VERSION ""

NS_ :

BS_:

BU_: AVM_SD CGW IVI eHBox

BO_ 1543 BCM_A106: 8 CGW
  SG_ SilentModeActivationState : 4|1@0+ (1,0) [0|0] "" IVI
  SG_ MirrorDownDisplayRequest : 8|1@0+ (1,0) [0|0] "" IVI
  SG_ MirrorUpDisplayRequest : 9|1@0+ (1,0) [0|0] "" IVI
  SG_ MirrorRightDisplayRequest : 10|1@0+ (1,0) [0|0] "" IVI
  SG_ MirrorLeftDisplayRequest : 11|1@0+ (1,0) [0|0] "" IVI
  SG_ MirrorSideSelectDisplayRequest : 13|2@0+ (1,0) [0|0] "" IVI
  SG_ AmbiLightColorStatus_v2 : 23|7@0+ (1,0) [0|0] "" IVI
  SG_ VR_AuthCondition_RL : 24|1@0+ (1,0) [0|0] "" IVI
  SG_ VR_AuthCondition_FR : 25|1@0+ (1,0) [0|0] "" IVI
  SG_ VR_AuthCondition_FL : 26|1@0+ (1,0) [0|0] "" IVI
  SG_ EmblemLightIntensityStatus : 36|5@0+ (5,0) [0|100] "%" IVI
  SG_ VR_AuthCondition_SSU : 37|1@0+ (1,0) [0|0] "" IVI
  SG_ VR_AuthCondition_SRU : 38|1@0+ (1,0) [0|0] "" IVI
  SG_ VR_AuthCondition_RR : 39|1@0+ (1,0) [0|0] "" IVI
  SG_ RearLeftWheelPressure_V2_twin : 47|8@0+ (30,0) [0|7620] "mbar" IVI
  SG_ RearRightWheelPressure_V2_twin : 55|8@0+ (30,0) [0|7620] "mbar" IVI
  SG_ EcoAdviceTirePressureRR_twin : 59|1@0+ (1,0) [0|0] "" IVI
  SG_ EcoAdviceTirePressureRL_twin : 60|1@0+ (1,0) [0|0] "" IVI

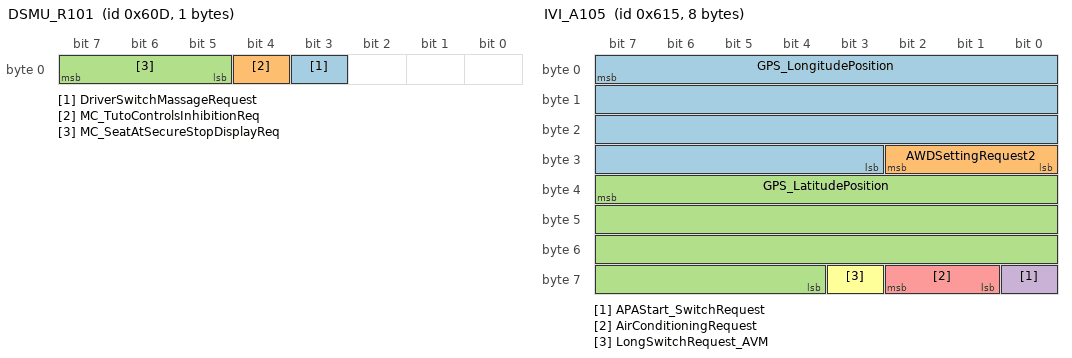
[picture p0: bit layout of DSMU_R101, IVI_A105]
BO_ 1549 DSMU_R101: 1 CGW
  SG_ DriverSwitchMassageRequest : 3|1@0+ (1,0) [0|0] "" IVI
  SG_ MC_TutoControlsInhibitionReq : 4|1@0+ (1,0) [0|0] "" IVI
  SG_ MC_SeatAtSecureStopDisplayReq : 7|3@0+ (1,0) [0|0] "" IVI

BO_ 1553 HVAC_A106: 8 CGW
  SG_ SecondRowCentralSeatStatus : 2|3@0+ (1,0) [0|0] "" IVI
  SG_ ClimForcedFreshDisplayStatus : 6|1@0+ (1,0) [0|0] "" IVI
  SG_ ClimForcedRecyDisplayStatus : 7|1@0+ (1,0) [0|0] "" IVI
  SG_ ClimForcedFreshDisplay : 9|2@0+ (1,0) [0|0] "" IVI
  SG_ ClimAQSSensitivityDisplay : 12|3@0+ (1,0) [0|0] "" IVI
  SG_ ClimExternalAirPollutionDisplay : 15|3@0+ (1,0) [0|0] "" IVI
  SG_ ClimRearDefrostDisplayStatus : 16|1@0+ (1,0) [0|0] "" IVI
  SG_ ClimExternAirPollutioDispStatus : 17|1@0+ (1,0) [0|0] "" IVI
  SG_ ClimLinkPriorityFLSeatAutoDisp : 20|3@0+ (1,0) [0|0] "" IVI
  SG_ ClimLinkPriorityFRSeatAutoDisp : 23|3@0+ (1,0) [0|0] "" IVI
  SG_ FrontRightSeatDisplayStatus : 24|1@0+ (1,0) [0|0] "" IVI
  SG_ FrontRightSeatStatus : 27|3@0+ (1,0) [0|0] "" IVI
  SG_ FrontLeftSeatStatus : 30|3@0+ (1,0) [0|0] "" IVI
  SG_ FrontLeftSeatDisplayStatus : 31|1@0+ (1,0) [0|0] "" IVI
  SG_ SecondRowLeftSeatAutoDisplay : 33|2@0+ (1,0) [0|0] "" IVI
  SG_ SecondRowRightSeatAutoDisplay : 35|2@0+ (1,0) [0|0] "" IVI
  SG_ FrontLeftSeatAutoDisplay : 37|2@0+ (1,0) [0|0] "" IVI
  SG_ FrontRightSeatAutoDisplay : 39|2@0+ (1,0) [0|0] "" IVI
  SG_ ThirdRowLeftSeatAutoDisplay : 41|2@0+ (1,0) [0|0] "" IVI
  SG_ ThirdRowRightSeatDisplayStatus : 42|1@0+ (1,0) [0|0] "" IVI
  SG_ ThirdRowLeftSeatDisplayStatus : 43|1@0+ (1,0) [0|0] "" IVI
  SG_ ThirdRowRightSeatAutoDisplay : 45|2@0+ (1,0) [0|0] "" IVI
  SG_ SecondRowRightSeatDisplayStatus : 46|1@0+ (1,0) [0|0] "" IVI
  SG_ SecondRowLeftSeatDisplayStatus : 47|1@0+ (1,0) [0|0] "" IVI
  SG_ ClimCabinTempDisplayUnit : 48|1@0+ (1,0) [0|0] "" IVI
  SG_ ClimLastFuncModifiedByCustomer_v2 : 55|4@0+ (1,0) [0|0] "" IVI
  SG_ ClimLinkPrioRearSeatsAutoDisp : 58|3@0+ (1,0) [0|0] "" IVI
  SG_ ClimACmaxDisplay : 63|2@0+ (1,0) [0|0] "" IVI

BO_ 1557 IVI_A105: 8 IVI
  SG_ GPS_LongitudePosition : 7|29@0+ (0.00010,-18000) [-18000|17959.999] "min" CGW
  SG_ AWDSettingRequest2 : 26|3@0+ (1,0) [0|0] "" CGW
  SG_ GPS_LatitudePosition : 39|28@0+ (0.00010,-9000) [-9000|8959.999] "min" CGW
  SG_ APAStart_SwitchRequest : 56|1@0+ (1,0) [0|0] "" CGW
  SG_ AirConditioningRequest : 58|2@0+ (1,0) [0|0] "" CGW
  SG_ LongSwitchRequest_AVM : 59|1@0+ (1,0) [0|0] "" CGW

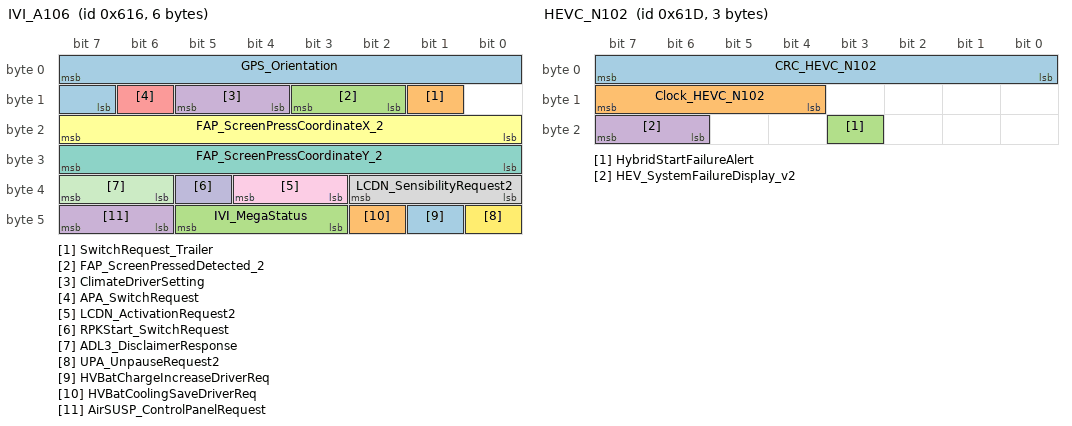
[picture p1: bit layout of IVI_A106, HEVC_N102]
BO_ 1558 IVI_A106: 6 IVI
  SG_ GPS_Orientation : 7|9@0+ (1,-180) [-180|179] "deg" CGW
  SG_ SwitchRequest_Trailer : 9|1@0+ (1,0) [0|0] "" CGW
  SG_ FAP_ScreenPressedDetected_2 : 11|2@0+ (1,0) [0|0] "" CGW
  SG_ ClimateDriverSetting : 13|2@0+ (1,0) [0|0] "" CGW
  SG_ APA_SwitchRequest : 14|1@0+ (1,0) [0|0] "" CGW
  SG_ FAP_ScreenPressCoordinateX_2 : 23|8@0+ (1,0) [0|255] "" CGW
  SG_ FAP_ScreenPressCoordinateY_2 : 31|8@0+ (1,0) [0|255] "" CGW
  SG_ LCDN_SensibilityRequest2 : 34|3@0+ (1,0) [0|0] "" CGW
  SG_ LCDN_ActivationRequest2 : 36|2@0+ (1,0) [0|0] "" CGW
  SG_ RPKStart_SwitchRequest : 37|1@0+ (1,0) [0|0] "" CGW
  SG_ ADL3_DisclaimerResponse : 39|2@0+ (1,0) [0|0] "" CGW
  SG_ UPA_UnpauseRequest2 : 40|1@0+ (1,0) [0|0] "" CGW
  SG_ HVBatChargeIncreaseDriverReq : 41|1@0+ (1,0) [0|0] "" CGW
  SG_ HVBatCoolingSaveDriverReq : 42|1@0+ (1,0) [0|0] "" CGW
  SG_ IVI_MegaStatus : 45|3@0+ (1,0) [0|0] "" CGW
  SG_ AirSUSP_ControlPanelRequest : 47|2@0+ (1,0) [0|0] "" CGW

BO_ 1561 HEVC_A131: 8 CGW
  SG_ HVB_MaxCapacity_HEVC_v2 : 9|16@0+ (0.1,0) [0|6553.5] "kWh" IVI

BO_ 1564 HEVC_A135: 8 CGW
  SG_ ReacheableUSOCatDepartureTime : 7|7@0+ (1,0) [0|100] "%" IVI
  SG_ ReacheableUSOCatDepartureTimeAl : 51|1@0+ (1,0) [0|0] "" IVI

BO_ 1565 HEVC_N102: 3 CGW
  SG_ CRC_HEVC_N102 : 7|8@0+ (1,0) [0|255] "" IVI
  SG_ Clock_HEVC_N102 : 15|4@0+ (1,0) [0|15] "" IVI
  SG_ HybridStartFailureAlert : 19|1@0+ (1,0) [0|0] "" IVI
  SG_ HEV_SystemFailureDisplay_v2 : 23|2@0+ (1,0) [0|0] "" IVI

BO_ 1567 AUDIOamp_A1: 2 CGW
  SG_ AudioAvailability_Amp : 10|1@0+ (1,0) [0|0] "" IVI

BO_ 1568 HEVC_A35: 5 CGW
  SG_ EcoNavDistanceSaving : 7|17@0+ (0.1,0) [0|10000] "wu" IVI

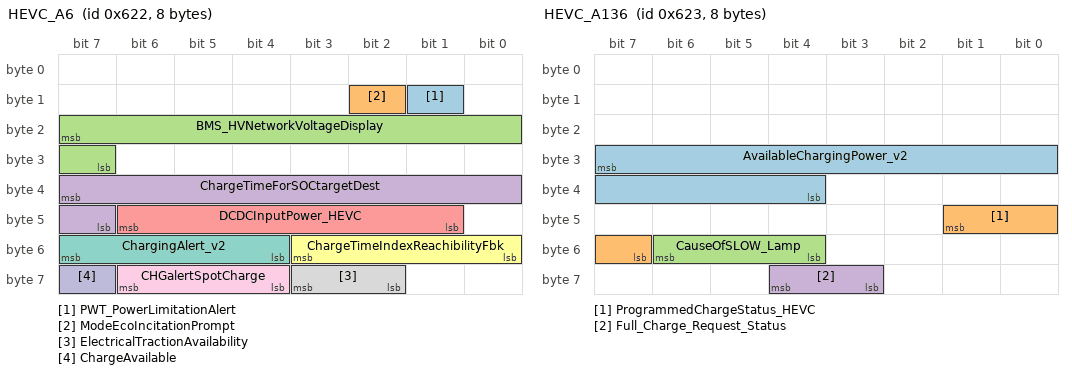
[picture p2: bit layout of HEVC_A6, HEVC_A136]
BO_ 1570 HEVC_A6: 8 CGW
  SG_ PWT_PowerLimitationAlert : 9|1@0+ (1,0) [0|0] "" IVI
  SG_ ModeEcoIncitationPrompt : 10|1@0+ (1,0) [0|0] "" IVI
  SG_ BMS_HVNetworkVoltageDisplay : 23|9@0+ (1,0) [0|500] "V" IVI
  SG_ ChargeTimeForSOCtargetDest : 39|9@0+ (5,0) [0|2555] "min" IVI
  SG_ DCDCInputPower_HEVC : 46|6@0+ (0.1,0) [0|6] "kW" IVI
  SG_ ChargeTimeIndexReachibilityFbk : 51|4@0+ (1,0) [0|0] "" IVI
  SG_ ChargingAlert_v2 : 55|4@0+ (1,0) [0|0] "" IVI
  SG_ ElectricalTractionAvailability : 59|2@0+ (1,0) [0|0] "" IVI
  SG_ CHGalertSpotCharge : 62|3@0+ (1,0) [0|0] "" IVI
  SG_ ChargeAvailable : 63|1@0+ (1,0) [0|0] "" IVI

BO_ 1571 HEVC_A136: 8 CGW
  SG_ AvailableChargingPower_v2 : 31|12@0+ (0.05,0) [0|200] "kW" IVI
  SG_ ProgrammedChargeStatus_HEVC : 41|3@0+ (1,0) [0|0] "" IVI
  SG_ CauseOfSLOW_Lamp : 54|3@0+ (1,0) [0|0] "" IVI
  SG_ Full_Charge_Request_Status : 60|2@0+ (1,0) [0|0] "" IVI

BO_ 1572 HEVC_R105: 7 CGW
  SG_ TotalConsumption_LastTrip : 7|12@0+ (0.1,0) [0|409.4] "kWh" IVI
  SG_ TotalRecovery_LastTrip : 11|12@0+ (0.1,0) [0|409.4] "kWh" IVI

BO_ 1573 HEVC_A23: 6 CGW
  SG_ CHGTemp_BLMS : 23|7@0+ (1,0) [0|100] "%" IVI
  SG_ OperatingTypeStatus_BLMS : 39|4@0+ (1,0) [0|0] "" IVI

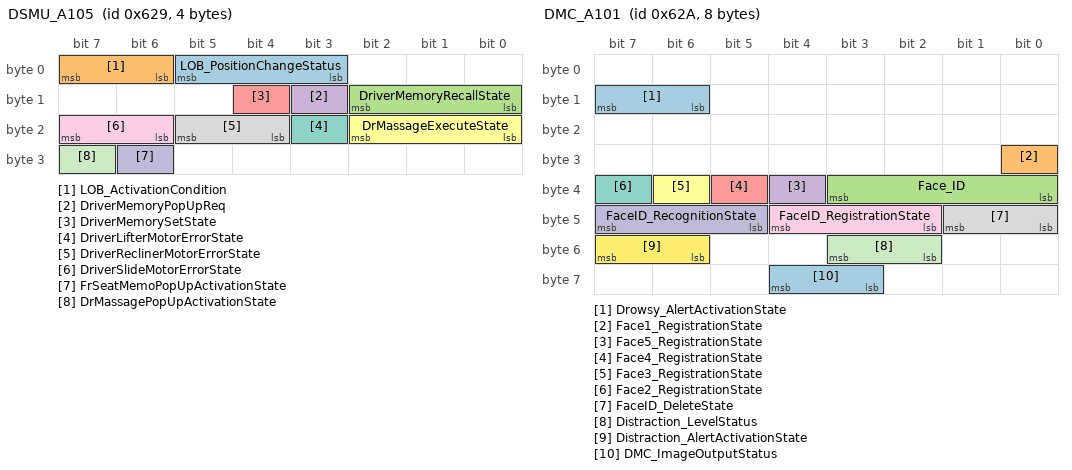
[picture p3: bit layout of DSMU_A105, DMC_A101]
BO_ 1577 DSMU_A105: 4 CGW
  SG_ LOB_PositionChangeStatus : 5|3@0+ (1,0) [0|0] "" IVI
  SG_ LOB_ActivationCondition : 7|2@0+ (1,0) [0|0] "" IVI
  SG_ DriverMemoryRecallState : 10|3@0+ (1,0) [0|0] "" IVI
  SG_ DriverMemoryPopUpReq : 11|1@0+ (1,0) [0|0] "" IVI
  SG_ DriverMemorySetState : 12|1@0+ (1,0) [0|0] "" IVI
  SG_ DrMassageExecuteState : 18|3@0+ (1,0) [0|0] "" IVI
  SG_ DriverLifterMotorErrorState : 19|1@0+ (1,0) [0|0] "" IVI
  SG_ DriverReclinerMotorErrorState : 21|2@0+ (1,0) [0|0] "" IVI
  SG_ DriverSlideMotorErrorState : 23|2@0+ (1,0) [0|0] "" IVI
  SG_ FrSeatMemoPopUpActivationState : 30|1@0+ (1,0) [0|0] "" IVI
  SG_ DrMassagePopUpActivationState : 31|1@0+ (1,0) [0|0] "" IVI

BO_ 1578 DMC_A101: 8 CGW
  SG_ Drowsy_AlertActivationState : 15|2@0+ (1,0) [0|0] "" IVI
  SG_ Face1_RegistrationState : 24|1@0+ (1,0) [0|0] "" IVI
  SG_ Face_ID : 35|4@0+ (1,0) [0|0] "" IVI
  SG_ Face5_RegistrationState : 36|1@0+ (1,0) [0|0] "" IVI
  SG_ Face4_RegistrationState : 37|1@0+ (1,0) [0|0] "" IVI
  SG_ Face3_RegistrationState : 38|1@0+ (1,0) [0|0] "" IVI
  SG_ Face2_RegistrationState : 39|1@0+ (1,0) [0|0] "" IVI
  SG_ FaceID_DeleteState : 41|2@0+ (1,0) [0|0] "" IVI
  SG_ FaceID_RegistrationState : 44|3@0+ (1,0) [0|0] "" IVI
  SG_ FaceID_RecognitionState : 47|3@0+ (1,0) [0|0] "" IVI
  SG_ Distraction_LevelStatus : 51|2@0+ (1,0) [0|0] "" IVI
  SG_ Distraction_AlertActivationState : 55|2@0+ (1,0) [0|0] "" IVI
  SG_ DMC_ImageOutputStatus : 60|2@0+ (1,0) [0|0] "" IVI

BO_ 1579 FRCAMERA_A115: 2 CGW
  SG_ OverspeedAlertActivationStatus : 7|2@0+ (1,0) [0|0] "" IVI

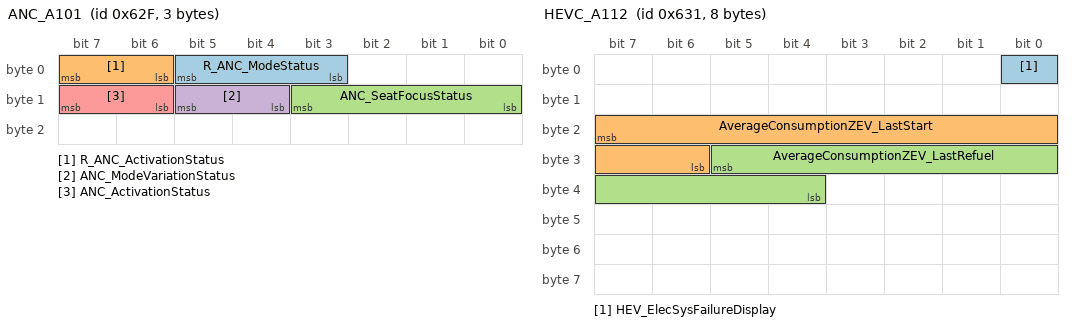
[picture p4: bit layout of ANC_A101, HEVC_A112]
BO_ 1583 ANC_A101: 3 CGW
  SG_ R_ANC_ModeStatus : 5|3@0+ (1,0) [0|0] "" IVI
  SG_ R_ANC_ActivationStatus : 7|2@0+ (1,0) [0|0] "" IVI
  SG_ ANC_SeatFocusStatus : 11|4@0+ (1,0) [0|0] "" IVI
  SG_ ANC_ModeVariationStatus : 13|2@0+ (1,0) [0|0] "" IVI
  SG_ ANC_ActivationStatus : 15|2@0+ (1,0) [0|0] "" IVI

BO_ 1585 HEVC_A112: 8 CGW
  SG_ HEV_ElecSysFailureDisplay : 0|1@0+ (1,0) [0|0] "" IVI
  SG_ AverageConsumptionZEV_LastStart : 23|10@0+ (0.1,0) [0|102.2] "-" IVI
  SG_ AverageConsumptionZEV_LastRefuel : 29|10@0+ (0.1,0) [0|102.2] "" IVI

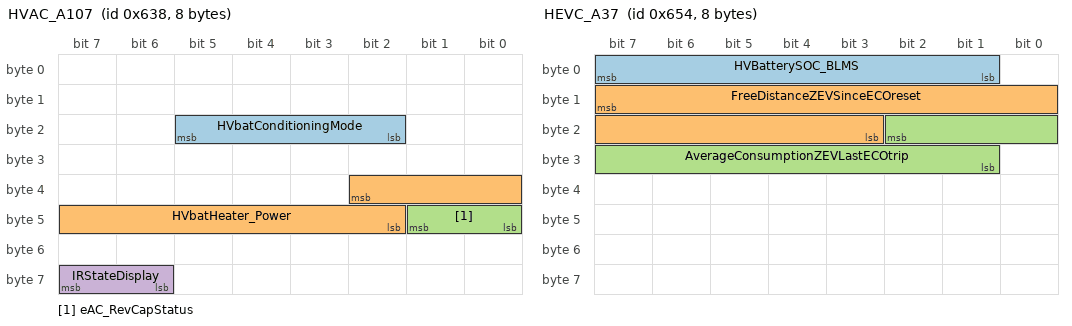
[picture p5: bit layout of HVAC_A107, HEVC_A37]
BO_ 1592 HVAC_A107: 8 CGW
  SG_ HVbatConditioningMode : 21|4@0+ (1,0) [0|0] "" IVI
  SG_ HVbatHeater_Power : 34|9@0+ (10,0) [0|5000] "W" IVI
  SG_ eAC_RevCapStatus : 41|2@0+ (1,0) [0|0] "" IVI
  SG_ IRStateDisplay : 63|2@0+ (1,0) [0|0] "" IVI

BO_ 1595 IVI_A114: 8 IVI
  SG_ FOTA_ProgValueRequest : 5|11@0+ (1,0) [0|1440] "min" CGW
  SG_ TrailerGuidelineActivationRequest : 7|2@0+ (1,0) [0|0] "" CGW
  SG_ HUD_RotationPositionRequest2 : 19|5@0+ (1,0) [0|0] "" CGW
  SG_ AVM_GuidelinesActivationRequest2 : 25|3@0+ (1,0) [0|0] "" CGW
  SG_ OffsetValue_Request2 : 30|5@0+ (1,0) [0|0] "" CGW
  SG_ AmbientLightingAreaADReq : 32|2@0+ (1,0) [0|0] "" CGW
  SG_ VolumAlarmActivationRequest2 : 35|3@0+ (1,0) [0|0] "" CGW
  SG_ ContextSpeed_ActivationRequest2 : 38|3@0+ (1,0) [0|0] "" CGW
  SG_ OffsetActivation_Request2 : 42|2@0+ (1,0) [0|0] "" CGW
  SG_ FOTA_ProgRequest : 44|2@0+ (1,0) [0|0] "" CGW
  SG_ ContextRoad_ActivationRequest2 : 46|2@0+ (1,0) [0|0] "" CGW
  SG_ Drowsy_AlertActivationRequest2 : 49|2@0+ (1,0) [0|0] "" CGW
  SG_ RearViewRVC_CancelReason_RER : 50|1@0+ (1,0) [0|0] "" CGW
  SG_ ZoomAutoActivationRequest2 : 52|2@0+ (1,0) [0|0] "" CGW
  SG_ RearViewRVC_CancelReason : 54|2@0+ (1,0) [0|0] "" CGW
  SG_ HVbatteryWarmingRequest : 57|2@0+ (1,0) [0|0] "" CGW
  SG_ OSE_ActivationRequest2 : 59|2@0+ (1,0) [0|0] "" CGW

BO_ 1596 IVI_R103: 8 IVI
  SG_ NextTurnProximityDetected : 0|1@0+ (1,0) [0|0] "" CGW
  SG_ CurrentAudioState : 2|2@0+ (1,0) [0|0] "" CGW
  SG_ CompassPosition : 7|5@0+ (1,0) [0|31] "wu" CGW
  SG_ CurrentRadioFavorite : 8|1@0+ (1,0) [0|0] "" CGW
  SG_ CurrentPhoneStatus : 11|3@0+ (1,0) [0|0] "" CGW
  SG_ CurrentAudioSource_v2 : 15|4@0+ (1,0) [0|0] "" CGW
  SG_ CurrentRadioBand_v2 : 23|3@0+ (1,0) [0|0] "" CGW
  SG_ AutoDimmingRequest : 25|2@0+ (1,0) [0|0] "" CGW
  SG_ CurrentRadioMode : 27|2@0+ (1,0) [0|0] "" CGW
  SG_ IconNumberForNavigationDisplay : 39|8@0+ (1,0) [0|255] "wu" CGW
  SG_ SC_DepartureTimeMinute : 41|6@0+ (1,0) [0|59] "min" CGW
  SG_ PnCactivationRequest_IVI : 43|2@0+ (1,0) [0|0] "" CGW
  SG_ TCS_DeactivationRequest2 : 45|2@0+ (1,0) [0|0] "" CGW
  SG_ HDC_ActivationRequest2 : 47|2@0+ (1,0) [0|0] "" CGW
  SG_ SC_DepartureTimeHour : 51|5@0+ (1,0) [0|23] "h" CGW
  SG_ ClusterSkinRequest_v2 : 59|4@0+ (1,0) [0|0] "" CGW
  SG_ SC_DepartureTimeWeekDay : 62|3@0+ (1,0) [0|0] "" CGW

BO_ 1599 SRRR_A107: 1 CGW
  SG_ CTA_ActivationState : 7|1@0+ (1,0) [0|0] "" IVI

BO_ 1614 IVI_A129: 8 IVI
  SG_ HUD_TelSMSactivationRequest2 : 1|2@0+ (1,0) [0|0] "" CGW
  SG_ HUD_ITactivationRequest2 : 3|2@0+ (1,0) [0|0] "" CGW
  SG_ FunctionalLightingActivReq : 5|2@0+ (1,0) [0|0] "" CGW
  SG_ CASP_ActivationRequest2 : 7|2@0+ (1,0) [0|0] "" CGW
  SG_ RearLeftLumbarMovingReq_X_Axis : 8|2@0+ (1,0) [0|0] "" CGW
  SG_ RearLeftFrontHeightMovingReq : 10|2@0+ (1,0) [0|0] "" CGW
  SG_ R_ANC_ModeSwitchRequest : 13|3@0+ (1,0) [0|0] "" CGW
  SG_ R_ANC_ActivationRequest : 15|2@0+ (1,0) [0|0] "" CGW
  SG_ RearLeftMassageProgramReq : 17|4@0+ (1,0) [0|0] "" CGW
  SG_ RearLeftMassageIntensityReq : 20|3@0+ (1,0) [0|0] "" CGW
  SG_ RearLeftLumbarMovingReq_Z_Axis : 22|2@0+ (1,0) [0|0] "" CGW
  SG_ RearLeftReclinerMovingReq : 24|2@0+ (1,0) [0|0] "" CGW
  SG_ RearLeftOttomanMovingReq : 26|2@0+ (1,0) [0|0] "" CGW
  SG_ RearLeftMassageVelocityReq : 29|3@0+ (1,0) [0|0] "" CGW
  SG_ RearRightLumbarMovingReq_X_Axis : 32|2@0+ (1,0) [0|0] "" CGW
  SG_ RearRightFrontHeightMovingReq : 34|2@0+ (1,0) [0|0] "" CGW
  SG_ RearLeftUpperbackrestMovingReq : 36|2@0+ (1,0) [0|0] "" CGW
  SG_ RearLeftSlideMovingReq : 38|2@0+ (1,0) [0|0] "" CGW
  SG_ RearRightMassageProgramReq : 41|4@0+ (1,0) [0|0] "" CGW
  SG_ RearRightMassageIntensityReq : 44|3@0+ (1,0) [0|0] "" CGW
  SG_ RearRightLumbarMovingReq_Z_Axis : 46|2@0+ (1,0) [0|0] "" CGW
  SG_ RearRightReclinerMovingReq : 48|2@0+ (1,0) [0|0] "" CGW
  SG_ RearRightOttomanMovingReq : 50|2@0+ (1,0) [0|0] "" CGW
  SG_ RearRightMassageVelocityReq : 53|3@0+ (1,0) [0|0] "" CGW
  SG_ PairingMode : 56|1@0+ (1,0) [0|0] "" CGW
  SG_ V2G_ActivationRequest : 58|2@0+ (1,0) [0|0] "" CGW
  SG_ RearRightUpperbackrestMovingReq : 60|2@0+ (1,0) [0|0] "" CGW
  SG_ RearRightSlideMovingReq : 62|2@0+ (1,0) [0|0] "" CGW

BO_ 1616 SONAR_A122: 2 CGW
  SG_ APA_WarningDisplayRequest2 : 7|6@0+ (1,0) [0|0] "" IVI
  SG_ APA_ScanInfo2 : 12|3@0+ (1,0) [0|0] "" IVI

BO_ 1620 HEVC_A37: 8 CGW
  SG_ HVBatterySOC_BLMS : 7|7@0+ (1,0) [0|100] "%" IVI
  SG_ FreeDistanceZEVSinceECOreset : 15|13@0+ (0.1,0) [0|800] "wu" IVI
  SG_ AverageConsumptionZEVLastECOtrip : 18|10@0+ (0.1,0) [0|102.2] "wu" IVI

BO_ 1625 CPLC_A109: 8 CGW
  SG_ EVSESelectedProtocol : 29|2@0+ (1,0) [0|0] "" IVI
  SG_ PnC_Contract_Certificate_Status : 57|2@0+ (1,0) [0|0] "" IVI

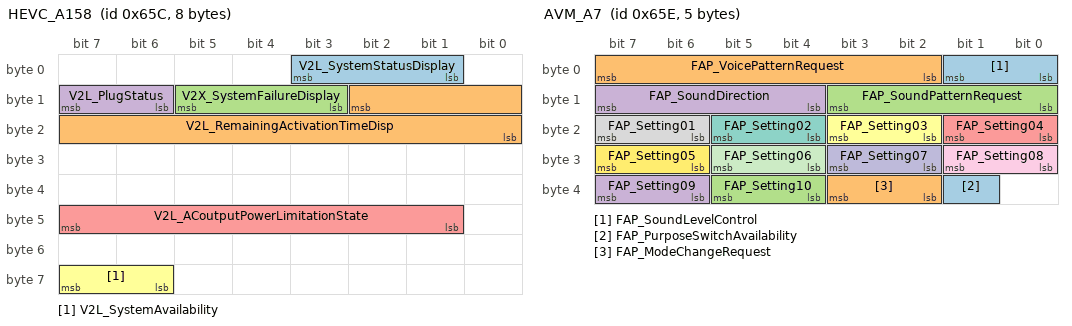
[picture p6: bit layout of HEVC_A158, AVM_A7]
BO_ 1628 HEVC_A158: 8 CGW
  SG_ V2L_SystemStatusDisplay : 3|3@0+ (1,0) [0|0] "" IVI
  SG_ V2L_RemainingActivationTimeDisp : 10|11@0+ (1,0) [0|2046] "min" IVI
  SG_ V2X_SystemFailureDisplay : 13|3@0+ (1,0) [0|0] "" IVI
  SG_ V2L_PlugStatus : 15|2@0+ (1,0) [0|0] "" IVI
  SG_ V2L_ACoutputPowerLimitationState : 47|7@0+ (0.1,0) [0|10] "kW" IVI
  SG_ V2L_SystemAvailability : 63|2@0+ (1,0) [0|0] "" IVI

BO_ 1629 AVM_A6: 6 CGW
  SG_ FAP_ChangeViewRequest : 0|1@0+ (1,0) [0|0] "" IVI
  SG_ FAP_FramePattern : 7|7@0+ (1,0) [0|127] "wu" IVI
  SG_ FAP_SwitchGrayOutRequest02 : 8|1@0+ (1,0) [0|0] "" IVI
  SG_ FAP_SwitchGrayOutRequest01 : 9|1@0+ (1,0) [0|0] "" IVI
  SG_ FAP_GuideDisplayRequest : 15|6@0+ (1,0) [0|63] "wu" IVI
  SG_ FAP_SwitchGrayOutRequest04 : 16|1@0+ (1,0) [0|0] "" IVI
  SG_ FAP_SwitchGrayOutRequest03 : 17|1@0+ (1,0) [0|0] "" IVI
  SG_ FAP_MessageDisplayRequest : 23|6@0+ (1,0) [0|63] "wu" IVI
  SG_ FAP_SwitchGrayOutRequest06 : 24|1@0+ (1,0) [0|0] "" IVI
  SG_ FAP_SwitchGrayOutRequest05 : 25|1@0+ (1,0) [0|0] "" IVI
  SG_ FAP_ParkingTypeRequest : 31|6@0+ (1,0) [0|63] "wu" IVI
  SG_ FAP_SwitchGrayOutRequest08 : 32|1@0+ (1,0) [0|0] "" IVI
  SG_ FAP_SwitchGrayOutRequest07 : 33|1@0+ (1,0) [0|0] "" IVI
  SG_ FAP_PopupDisplayRequest : 39|6@0+ (1,0) [0|63] "wu" IVI
  SG_ FAP_SwitchGrayOutRequest12 : 41|1@0+ (1,0) [0|0] "" IVI
  SG_ FAP_SwitchGrayOutRequest11 : 42|1@0+ (1,0) [0|0] "" IVI
  SG_ FAP_SwitchGrayOutRequest10 : 43|1@0+ (1,0) [0|0] "" IVI
  SG_ FAP_SwitchGrayOutRequest09 : 44|1@0+ (1,0) [0|0] "" IVI
  SG_ FAP_CameraIndicatorRequest : 47|3@0+ (1,0) [0|0] "" IVI

BO_ 1630 AVM_A7: 5 CGW
  SG_ FAP_SoundLevelControl : 1|2@0+ (1,0) [0|0] "" IVI
  SG_ FAP_VoicePatternRequest : 7|6@0+ (1,0) [0|63] "wu" IVI
  SG_ FAP_SoundPatternRequest : 11|4@0+ (1,0) [0|0] "" IVI
  SG_ FAP_SoundDirection : 15|4@0+ (1,0) [0|0] "" IVI
  SG_ FAP_Setting04 : 17|2@0+ (1,0) [0|0] "" IVI
  SG_ FAP_Setting03 : 19|2@0+ (1,0) [0|0] "" IVI
  SG_ FAP_Setting02 : 21|2@0+ (1,0) [0|0] "" IVI
  SG_ FAP_Setting01 : 23|2@0+ (1,0) [0|0] "" IVI
  SG_ FAP_Setting08 : 25|2@0+ (1,0) [0|0] "" IVI
  SG_ FAP_Setting07 : 27|2@0+ (1,0) [0|0] "" IVI
  SG_ FAP_Setting06 : 29|2@0+ (1,0) [0|0] "" IVI
  SG_ FAP_Setting05 : 31|2@0+ (1,0) [0|0] "" IVI
  SG_ FAP_PurposeSwitchAvailability : 33|1@0+ (1,0) [0|0] "" IVI
  SG_ FAP_ModeChangeRequest : 35|2@0+ (1,0) [0|0] "" IVI
  SG_ FAP_Setting10 : 37|2@0+ (1,0) [0|0] "" IVI
  SG_ FAP_Setting09 : 39|2@0+ (1,0) [0|0] "" IVI

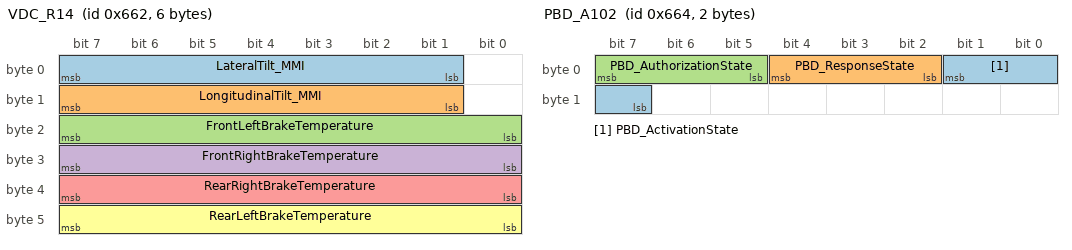
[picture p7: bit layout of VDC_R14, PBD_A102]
BO_ 1634 VDC_R14: 6 CGW
  SG_ LateralTilt_MMI : 7|7@0+ (1,-60) [-60|60] "°" IVI
  SG_ LongitudinalTilt_MMI : 15|7@0+ (1,-60) [-60|60] "°" IVI
  SG_ FrontLeftBrakeTemperature : 23|8@0+ (5,-50) [-50|1220] "°C" IVI
  SG_ FrontRightBrakeTemperature : 31|8@0+ (5,-50) [-50|1220] "°C" IVI
  SG_ RearRightBrakeTemperature : 39|8@0+ (5,-50) [-50|1220] "°C" IVI
  SG_ RearLeftBrakeTemperature : 47|8@0+ (5,-50) [-50|1220] "°C" IVI

BO_ 1635 HEVC_A162: 6 CGW
  SG_ V2X_HVBat_EnergyDurabilityWarn : 10|2@0+ (1,0) [0|0] "" IVI
  SG_ V2X_HVBat_EnergyDurabilityCount : 23|15@0+ (5,0) [0|150000] "KWh" IVI

BO_ 1636 PBD_A102: 2 CGW
  SG_ PBD_ActivationState : 1|3@0+ (1,0) [0|0] "" IVI
  SG_ PBD_ResponseState : 4|3@0+ (1,0) [0|0] "" IVI
  SG_ PBD_AuthorizationState : 7|3@0+ (1,0) [0|0] "" IVI

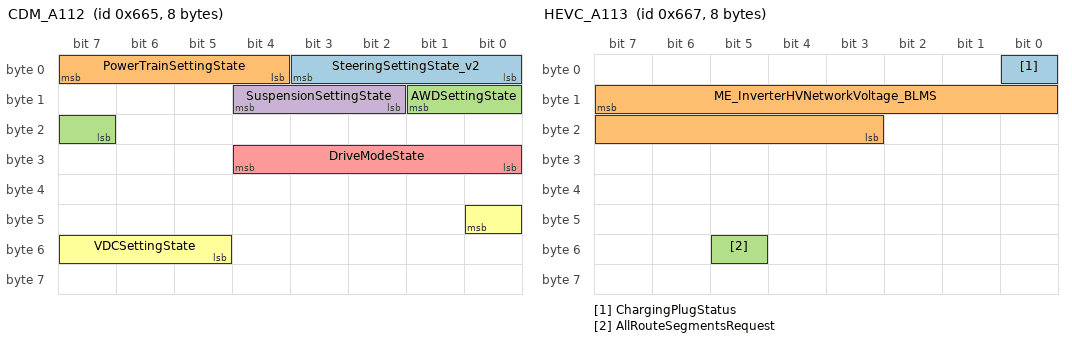
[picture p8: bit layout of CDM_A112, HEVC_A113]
BO_ 1637 CDM_A112: 8 CGW
  SG_ SteeringSettingState_v2 : 3|4@0+ (1,0) [0|0] "" IVI
  SG_ PowerTrainSettingState : 7|4@0+ (1,0) [0|0] "" IVI
  SG_ AWDSettingState : 9|3@0+ (1,0) [0|0] "" IVI
  SG_ SuspensionSettingState : 12|3@0+ (1,0) [0|0] "" IVI
  SG_ DriveModeState : 28|5@0+ (1,0) [0|0] "" IVI
  SG_ VDCSettingState : 40|4@0+ (1,0) [0|0] "" IVI

BO_ 1639 HEVC_A113: 8 CGW
  SG_ ChargingPlugStatus : 0|1@0+ (1,0) [0|0] "" IVI
  SG_ ME_InverterHVNetworkVoltage_BLMS : 15|13@0+ (0.1,0) [0|500] "V" IVI
  SG_ AllRouteSegmentsRequest : 53|1@0+ (1,0) [0|0] "" IVI

BO_ 1640 HEVC_A114: 8 CGW
  SG_ ChargeSpotPowerLevel : 43|9@0+ (0.3,0) [0|150] "kW" IVI
  SG_ SCdurabilityInhibition : 57|1@0+ (1,0) [0|0] "" IVI

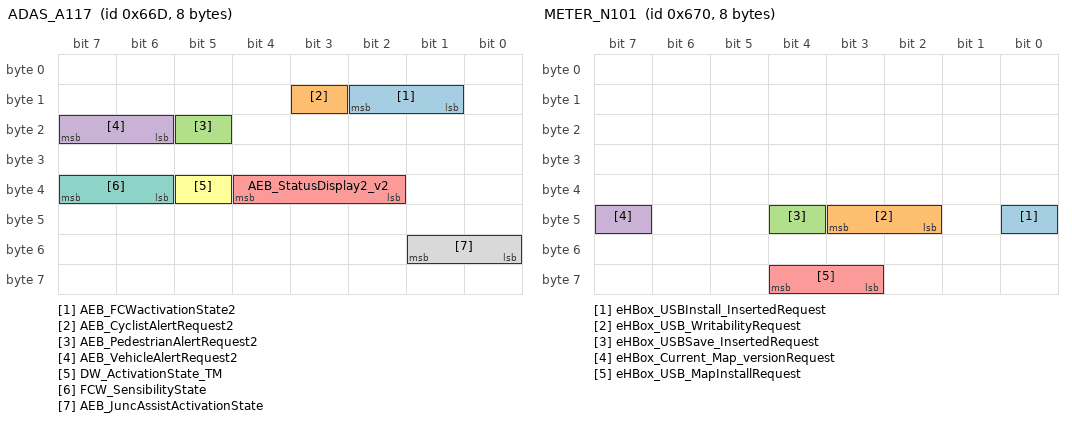
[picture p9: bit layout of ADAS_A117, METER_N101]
BO_ 1645 ADAS_A117: 8 CGW
  SG_ AEB_FCWactivationState2 : 10|2@0+ (1,0) [0|0] "" IVI
  SG_ AEB_CyclistAlertRequest2 : 11|1@0+ (1,0) [0|0] "" IVI
  SG_ AEB_PedestrianAlertRequest2 : 21|1@0+ (1,0) [0|0] "" IVI
  SG_ AEB_VehicleAlertRequest2 : 23|2@0+ (1,0) [0|0] "" IVI
  SG_ AEB_StatusDisplay2_v2 : 36|3@0+ (1,0) [0|0] "" IVI
  SG_ DW_ActivationState_TM : 37|1@0+ (1,0) [0|0] "" IVI
  SG_ FCW_SensibilityState : 39|2@0+ (1,0) [0|0] "" IVI
  SG_ AEB_JuncAssistActivationState : 49|2@0+ (1,0) [0|0] "" IVI

BO_ 1648 METER_N101: 8 CGW
  SG_ eHBox_USBInstall_InsertedRequest : 40|1@0+ (1,0) [0|0] "" eHBox
  SG_ eHBox_USB_WritabilityRequest : 43|2@0+ (1,0) [0|0] "" eHBox
  SG_ eHBox_USBSave_InsertedRequest : 44|1@0+ (1,0) [0|0] "" eHBox
  SG_ eHBox_Current_Map_versionRequest : 47|1@0+ (1,0) [0|0] "" eHBox
  SG_ eHBox_USB_MapInstallRequest : 60|2@0+ (1,0) [0|0] "" eHBox

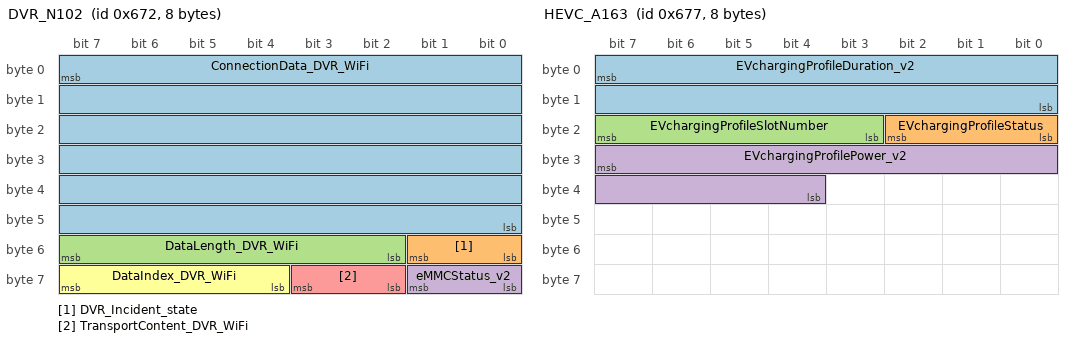
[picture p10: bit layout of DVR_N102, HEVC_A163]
BO_ 1650 DVR_N102: 8 CGW
  SG_ ConnectionData_DVR_WiFi : 7|48@0+ (1,0) [0|0] "" IVI
  SG_ DVR_Incident_state : 49|2@0+ (1,0) [0|0] "" IVI
  SG_ DataLength_DVR_WiFi : 55|6@0+ (1,0) [0|0] "" IVI
  SG_ eMMCStatus_v2 : 57|2@0+ (1,0) [0|0] "" IVI
  SG_ TransportContent_DVR_WiFi : 59|2@0+ (1,0) [0|0] "" IVI
  SG_ DataIndex_DVR_WiFi : 63|4@0+ (1,0) [0|0] "" IVI

BO_ 1653 IVI_R109: 2 IVI
  SG_ SC_TargetSOC_EVA : 15|5@0+ (5,0) [0|100] "%" CGW

BO_ 1655 HEVC_A163: 8 CGW
  SG_ EVchargingProfileDuration_v2 : 7|16@0+ (10,0) [0|604800] "s" IVI
  SG_ EVchargingProfileStatus : 18|3@0+ (1,0) [0|0] "" IVI
  SG_ EVchargingProfileSlotNumber : 23|5@0+ (1,0) [0|24] "" IVI
  SG_ EVchargingProfilePower_v2 : 31|12@0+ (100,0) [0|400000] "W" IVI

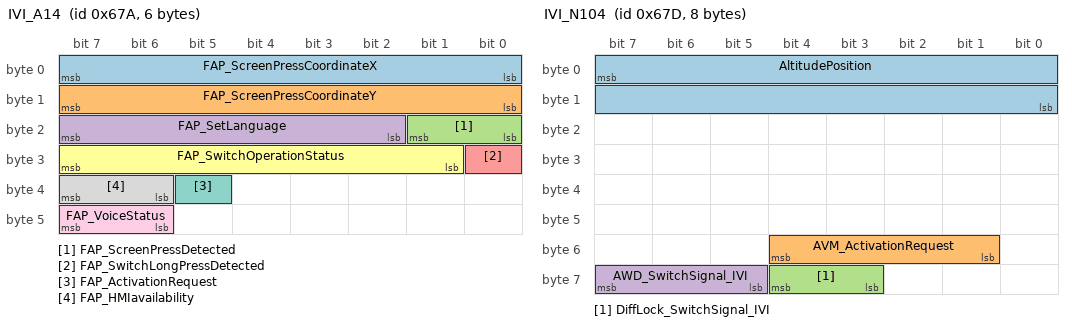
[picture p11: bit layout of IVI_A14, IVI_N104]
BO_ 1658 IVI_A14: 6 IVI
  SG_ FAP_ScreenPressCoordinateX : 7|8@0+ (1,0) [0|255] "wu" CGW
  SG_ FAP_ScreenPressCoordinateY : 15|8@0+ (1,0) [0|255] "wu" CGW
  SG_ FAP_ScreenPressDetected : 17|2@0+ (1,0) [0|0] "" CGW
  SG_ FAP_SetLanguage : 23|6@0+ (1,0) [0|63] "wu" CGW
  SG_ FAP_SwitchLongPressDetected : 24|1@0+ (1,0) [0|0] "" CGW
  SG_ FAP_SwitchOperationStatus : 31|7@0+ (1,0) [0|127] "wu" CGW
  SG_ FAP_ActivationRequest : 37|1@0+ (1,0) [0|0] "" CGW
  SG_ FAP_HMIavailability : 39|2@0+ (1,0) [0|0] "" CGW
  SG_ FAP_VoiceStatus : 47|2@0+ (1,0) [0|0] "" CGW

BO_ 1659 HFM_A102: 5 CGW
  SG_ UserIdentification_IKeyLink : 7|3@0+ (1,0) [0|0] "" IVI

BO_ 1660 HVAC_A102: 8 CGW
  SG_ RearSeatsLockStatus : 1|2@0+ (1,0) [0|0] "" IVI
  SG_ SecondRowRightSeatStatus : 4|3@0+ (1,0) [0|0] "" IVI
  SG_ SecondRowLeftSeatStatus : 7|3@0+ (1,0) [0|0] "" IVI
  SG_ ClimAutoRecyclingDisplayStatus : 8|1@0+ (1,0) [0|0] "" IVI
  SG_ ClimACDisplayStatus : 9|1@0+ (1,0) [0|0] "" IVI
  SG_ ThirdRowRightSeatStatus : 12|3@0+ (1,0) [0|0] "" IVI
  SG_ ThirdRowLeftSeatStatus : 15|3@0+ (1,0) [0|0] "" IVI
  SG_ ClimEVHeaterDisplayStatus : 16|1@0+ (1,0) [0|0] "" IVI
  SG_ ClimDriverZoneDisplayStatus : 17|1@0+ (1,0) [0|0] "" IVI
  SG_ ClimDriverZoneDisplay : 19|2@0+ (1,0) [0|0] "" IVI
  SG_ ClimClearnessDisplayStatus : 20|1@0+ (1,0) [0|0] "" IVI
  SG_ ClimBlowingLevelDisplayStatus : 21|1@0+ (1,0) [0|0] "" IVI
  SG_ ClimBlowingAutoDisplay : 23|2@0+ (1,0) [0|0] "" IVI
  SG_ ClimHumidityDisplayStatus : 24|1@0+ (1,0) [0|0] "" IVI
  SG_ ClimForestSettingDisplayStatus : 25|1@0+ (1,0) [0|0] "" IVI
  SG_ ClimForestDisplayStatus : 26|1@0+ (1,0) [0|0] "" IVI
  SG_ ClimForestDisplay : 28|2@0+ (1,0) [0|0] "" IVI
  SG_ ClimFlowDistrDisplayStatus : 29|1@0+ (1,0) [0|0] "" IVI
  SG_ ClimEVHeaterDisplay : 31|2@0+ (1,0) [0|0] "" IVI
  SG_ ClimLinkDefrostAndClearnesDisp : 33|2@0+ (1,0) [0|0] "" IVI
  SG_ ClimHumiditySensorSensitivDisp : 36|3@0+ (1,0) [0|0] "" IVI
  SG_ ClimHumidityDisplay : 39|3@0+ (1,0) [0|0] "" IVI
  SG_ ClimRightAutoDisplay : 41|2@0+ (1,0) [0|0] "" IVI
  SG_ ClimOFFModeDisplayStatus : 42|1@0+ (1,0) [0|0] "" IVI
  SG_ ClimLinkMaxFanSpeedAutoDisplay : 45|3@0+ (1,0) [0|0] "" IVI
  SG_ ClimLinkFreshRecyAndAutoDisplay : 47|2@0+ (1,0) [0|0] "" IVI
  SG_ ClimRightFlowDistrDisplayStatus : 48|1@0+ (1,0) [0|0] "" IVI
  SG_ ClimRightBlowingLevelDispStatus : 49|1@0+ (1,0) [0|0] "" IVI
  SG_ ClimRightBlowingLevelDisplay : 53|4@0+ (1,0) [0|0] "" IVI
  SG_ ClimRightBlowingAutoDisplay : 55|2@0+ (1,0) [0|0] "" IVI
  SG_ ClimTempDisplayStatus : 56|1@0+ (1,0) [0|0] "" IVI
  SG_ ClimSyncDisplayStatus : 57|1@0+ (1,0) [0|0] "" IVI
  SG_ ClimSyncDisplay : 59|2@0+ (1,0) [0|0] "" IVI
  SG_ ClimRightTempDisplayStatus : 60|1@0+ (1,0) [0|0] "" IVI
  SG_ ClimRightFlowDistrDisplay : 63|3@0+ (1,0) [0|0] "" IVI

BO_ 1661 IVI_N104: 8 IVI
  SG_ AltitudePosition : 7|16@0+ (0.1,-500) [-500|3000] "m" CGW
  SG_ AVM_ActivationRequest : 52|4@0+ (1,0) [0|0] "" CGW
  SG_ DiffLock_SwitchSignal_IVI : 60|2@0+ (1,0) [0|0] "" CGW
  SG_ AWD_SwitchSignal_IVI : 63|3@0+ (1,0) [0|0] "" CGW

BO_ 1662 IVI_A102: 8 IVI
  SG_ PassengerSeatMemoRecall : 4|3@0+ (1,0) [0|0] "" CGW
  SG_ PassengerSeatMemoRequest : 7|3@0+ (1,0) [0|0] "" CGW
  SG_ SecondRowRightSeatRequest : 11|4@0+ (1,0) [0|0] "" CGW
  SG_ SecondRowLeftSeatRequest : 15|4@0+ (1,0) [0|0] "" CGW
  SG_ ThirdRowRightSeatRequest : 19|4@0+ (1,0) [0|0] "" CGW
  SG_ ThirdRowLeftSeatRequest : 23|4@0+ (1,0) [0|0] "" CGW
  SG_ ClimClearnessPush : 24|1@0+ (1,0) [0|1] "-" CGW
  SG_ ClimACPush : 25|1@0+ (1,0) [0|1] "-" CGW
  SG_ RearSeatsLockRequest : 31|2@0+ (1,0) [0|0] "" CGW
  SG_ ClimHumiditySensorSensitivitReq : 34|3@0+ (1,0) [0|0] "" CGW
  SG_ ClimForestPush : 35|1@0+ (1,0) [0|1] "" CGW
  SG_ ClimForcedRecyclingPush : 36|1@0+ (1,0) [0|1] "-" CGW
  SG_ ClimForcedFreshPush : 37|1@0+ (1,0) [0|1] "-" CGW
  SG_ ClimEVHeaterPush : 38|1@0+ (1,0) [0|1] "-" CGW
  SG_ ClimDriverZonePush : 39|1@0+ (1,0) [0|1] "" CGW
  SG_ ClimRightFlowDistrDefPush : 40|1@0+ (1,0) [0|1] "-" CGW
  SG_ TimeFormatDisplay : 43|1@0+ (1,0) [0|0] "" CGW
  SG_ ClimFPrightBlowingRequest : 47|4@0+ (1,0) [0|0] "" CGW
  SG_ ClimRightFlowDistrVentPush : 48|1@0+ (1,0) [0|1] "-" CGW
  SG_ ClimRightFlowDistrFeetPush : 49|1@0+ (1,0) [0|1] "-" CGW
  SG_ ClimLinkPriorityFLSeatAutoReq : 52|3@0+ (1,0) [0|0] "" CGW
  SG_ ClimLinkMaxFanSpeedAutoReq : 55|3@0+ (1,0) [0|0] "" CGW
  SG_ ClimLinkDefrostAndClearnesPush : 56|1@0+ (1,0) [0|1] "" CGW
  SG_ ClimRightAutoNormalPush : 57|1@0+ (1,0) [0|1] "-" CGW
  SG_ FrontRightSeatAutoPush : 58|1@0+ (1,0) [0|1] "-" CGW
  SG_ FrontLeftSeatAutoPush : 59|1@0+ (1,0) [0|1] "-" CGW
  SG_ ClimSyncPush : 60|1@0+ (1,0) [0|1] "-" CGW
  SG_ ClimLinkPriorityFRSeatAutoReq : 63|3@0+ (1,0) [0|0] "" CGW

BO_ 1666 IVI_A134: 8 IVI
  SG_ Distract_AlertStatus2 : 1|2@0+ (1,0) [0|0] "" CGW
  SG_ Cluster_DisplayContentsChangeReq : 7|6@0+ (1,0) [0|0] "" CGW
  SG_ DynamicBackgroundState : 12|5@0+ (1,0) [0|0] "" CGW
  SG_ Cluster_DisplayViewModeChangeReq : 15|3@0+ (1,0) [0|0] "" CGW
  SG_ V2X_SOClimitationLevelRequest2 : 23|7@0+ (1,0) [0|100] "%" CGW
  SG_ DynamicBackgroundProgress : 31|4@0+ (1,0) [0|0] "" CGW
  SG_ SSickness_AlertStatus2 : 33|2@0+ (1,0) [0|0] "" CGW
  SG_ Fatigue_AlertStatus2 : 35|2@0+ (1,0) [0|0] "" CGW
  SG_ DriverEyesOnRoad2 : 37|2@0+ (1,0) [0|0] "" CGW
  SG_ Distraction_LevelStatus2 : 39|2@0+ (1,0) [0|0] "" CGW
  SG_ Fatigue_LevelStatus2 : 42|3@0+ (1,0) [0|0] "" CGW
  SG_ DMS_CameraCancelReason2 : 45|3@0+ (1,0) [0|0] "" CGW
  SG_ SSickness_State2 : 47|2@0+ (1,0) [0|0] "" CGW
  SG_ ANC_ModeVariationRequest : 49|2@0+ (1,0) [0|0] "" CGW
  SG_ ANC_ActivationRequest : 51|2@0+ (1,0) [0|0] "" CGW
  SG_ NapModeRequest : 53|2@0+ (1,0) [0|0] "" CGW
  SG_ RelaxModeRequest : 55|2@0+ (1,0) [0|0] "" CGW
  SG_ FrSeatMemoPopUpActivationReq : 57|1@0+ (1,0) [0|0] "" CGW
  SG_ PsMassagePopUpActivationReq : 58|1@0+ (1,0) [0|0] "" CGW
  SG_ DrMassagePopUpActivationReq : 59|1@0+ (1,0) [0|0] "" CGW
  SG_ ANC_SeatFocusRequest : 63|4@0+ (1,0) [0|0] "" CGW

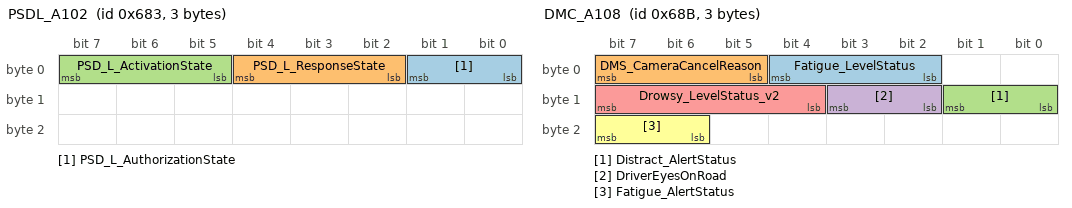
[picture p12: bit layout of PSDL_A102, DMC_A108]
BO_ 1667 PSDL_A102: 3 CGW
  SG_ PSD_L_AuthorizationState : 1|2@0+ (1,0) [0|0] "" IVI
  SG_ PSD_L_ResponseState : 4|3@0+ (1,0) [0|0] "" IVI
  SG_ PSD_L_ActivationState : 7|3@0+ (1,0) [0|0] "" IVI

BO_ 1670 IVI_A130: 8 IVI
  SG_ RearSignatureRequest : 0|2@0+ (1,0) [0|0] "" CGW
  SG_ AnimationPatternRequest : 4|4@0+ (1,0) [0|0] "" CGW
  SG_ InternalLightingIntensityReq2 : 7|3@0+ (1,0) [0|0] "" CGW
  SG_ ACCustomerCurrentLimit : 12|6@0+ (1,0) [0|62] "A" CGW
  SG_ AmbiLightADLINKTypeReq : 17|2@0+ (1,0) [0|0] "" CGW
  SG_ DMC_SensitivityRequest2 : 20|3@0+ (1,0) [0|0] "" CGW
  SG_ Distraction_AlertActivationReq2 : 22|2@0+ (1,0) [0|0] "" CGW
  SG_ AmbientlightADColorReq : 31|7@0+ (1,0) [0|0] "" CGW
  SG_ LKA_DL_ActivationRequest2 : 41|2@0+ (1,0) [0|0] "" CGW
  SG_ ELKA_OTOC_ActivationRequest2 : 43|2@0+ (1,0) [0|0] "" CGW
  SG_ ELKS_ActivationRequest2 : 45|2@0+ (1,0) [0|0] "" CGW
  SG_ LOB_PositionSaveRequest : 50|3@0+ (1,0) [0|0] "" CGW
  SG_ LOB_PositionRecallRequest : 53|3@0+ (1,0) [0|0] "" CGW
  SG_ OverspeedAlertActivationRequest2 : 55|2@0+ (1,0) [0|0] "" CGW
  SG_ Remote_Start_Stop_V2L : 58|3@0+ (1,0) [0|0] "" CGW
  SG_ AEB_JuncAssistActivationRequest2 : 60|2@0+ (1,0) [0|0] "" CGW
  SG_ VR_ESSURequest : 63|3@0+ (1,0) [0|0] "" CGW

BO_ 1671 USM_A106: 1 CGW
  SG_ AnimationPatternState : 7|4@0+ (1,0) [0|0] "" IVI

BO_ 1675 DMC_A108: 3 CGW
  SG_ Fatigue_LevelStatus : 4|3@0+ (1,0) [0|0] "" IVI
  SG_ DMS_CameraCancelReason : 7|3@0+ (1,0) [0|0] "" IVI
  SG_ Distract_AlertStatus : 9|2@0+ (1,0) [0|0] "" IVI
  SG_ DriverEyesOnRoad : 11|2@0+ (1,0) [0|0] "" IVI
  SG_ Drowsy_LevelStatus_v2 : 15|4@0+ (1,0) [0|0] "" IVI
  SG_ Fatigue_AlertStatus : 23|2@0+ (1,0) [0|0] "" IVI

BO_ 1677 IVI_A6: 3 IVI
  SG_ DistanceToDestination : 7|12@0+ (20,0) [0|81880] "m" CGW

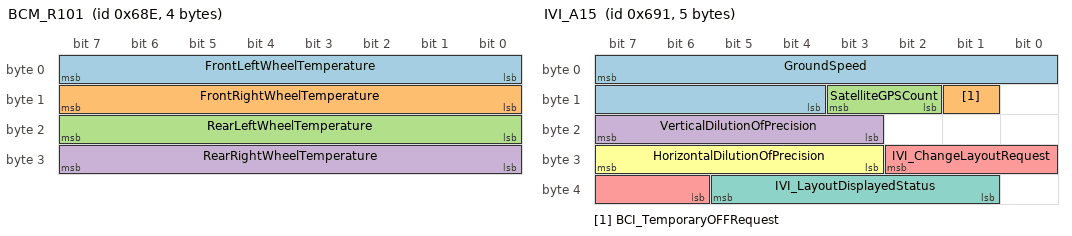
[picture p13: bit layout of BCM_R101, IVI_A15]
BO_ 1678 BCM_R101: 4 CGW
  SG_ FrontLeftWheelTemperature : 7|8@0+ (1,-30) [-30|224] "°C" IVI
  SG_ FrontRightWheelTemperature : 15|8@0+ (1,-30) [-30|224] "°C" IVI
  SG_ RearLeftWheelTemperature : 23|8@0+ (1,-30) [-30|224] "°C" IVI
  SG_ RearRightWheelTemperature : 31|8@0+ (1,-30) [-30|224] "°C" IVI

BO_ 1681 IVI_A15: 5 IVI
  SG_ GroundSpeed : 7|12@0+ (0.05,0) [0|150] "Kph" CGW
  SG_ BCI_TemporaryOFFRequest : 9|1@0+ (1,0) [0|0] "" CGW
  SG_ SatelliteGPSCount : 11|2@0+ (1,0) [0|3] "wu" CGW
  SG_ VerticalDilutionOfPrecision : 23|5@0+ (0.1,0) [0|3.1] "wu" CGW
  SG_ IVI_ChangeLayoutRequest : 26|5@0+ (1,0) [0|0] "" AVM_SD,CGW
  SG_ HorizontalDilutionOfPrecision : 31|5@0+ (0.1,0) [0|3.1] "wu" CGW
  SG_ IVI_LayoutDisplayedStatus : 37|5@0+ (1,0) [0|0] "" AVM_SD,CGW

BO_ 1682 HVAC_A6: 2 CGW
  SG_ ClimHeatedSteeringWheelDisplay : 5|2@0+ (1,0) [0|0] "" IVI

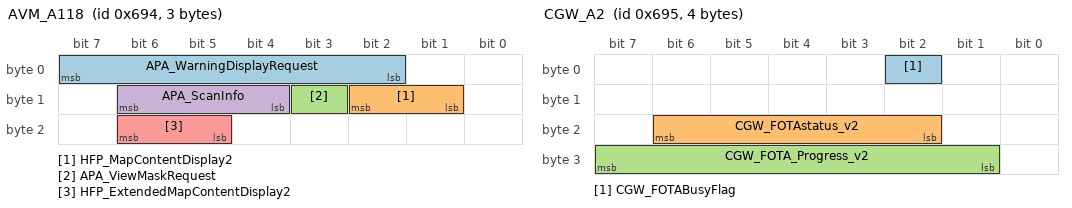
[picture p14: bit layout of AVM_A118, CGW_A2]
BO_ 1684 AVM_A118: 3 CGW
  SG_ APA_WarningDisplayRequest : 7|6@0+ (1,0) [0|0] "" IVI
  SG_ HFP_MapContentDisplay2 : 10|2@0+ (1,0) [0|0] "" IVI
  SG_ APA_ViewMaskRequest : 11|1@0+ (1,0) [0|0] "" IVI
  SG_ APA_ScanInfo : 14|3@0+ (1,0) [0|0] "" IVI
  SG_ HFP_ExtendedMapContentDisplay2 : 22|2@0+ (1,0) [0|0] "" IVI

BO_ 1685 CGW_A2: 4 CGW
  SG_ CGW_FOTABusyFlag : 2|1@0+ (1,0) [0|0] "" IVI
  SG_ CGW_FOTAstatus_v2 : 22|5@0+ (1,0) [0|0] "" IVI
  SG_ CGW_FOTA_Progress_v2 : 31|7@0+ (1,0) [0|100] "%" IVI

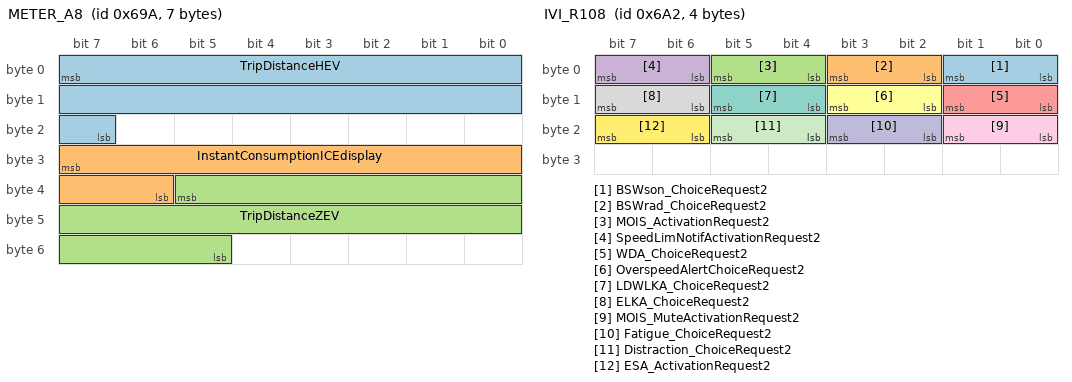
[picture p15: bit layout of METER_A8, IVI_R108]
BO_ 1690 METER_A8: 7 CGW
  SG_ TripDistanceHEV : 7|17@0+ (0.1,0) [0|10000] "-" IVI
  SG_ InstantConsumptionICEdisplay : 31|10@0+ (0.1,0) [0|102.3] "" IVI
  SG_ TripDistanceZEV : 37|17@0+ (0.1,0) [0|10000] "-" IVI

BO_ 1695 VehicleID_CANHS_R_01: 4 CGW
  SG_ VehicleID : 7|32@0+ (1,0) [0|0] "" IVI

BO_ 1697 ADASISv2_A106: 8 IVI
  SG_ ADASISv2_METADATA : 7|64@0+ (1,0) [0|0] "" CGW

BO_ 1698 IVI_R108: 4 IVI
  SG_ BSWson_ChoiceRequest2 : 1|2@0+ (1,0) [0|0] "" CGW
  SG_ BSWrad_ChoiceRequest2 : 3|2@0+ (1,0) [0|0] "" CGW
  SG_ MOIS_ActivationRequest2 : 5|2@0+ (1,0) [0|0] "" CGW
  SG_ SpeedLimNotifActivationRequest2 : 7|2@0+ (1,0) [0|0] "" CGW
  SG_ WDA_ChoiceRequest2 : 9|2@0+ (1,0) [0|0] "" CGW
  SG_ OverspeedAlertChoiceRequest2 : 11|2@0+ (1,0) [0|0] "" CGW
  SG_ LDWLKA_ChoiceRequest2 : 13|2@0+ (1,0) [0|0] "" CGW
  SG_ ELKA_ChoiceRequest2 : 15|2@0+ (1,0) [0|0] "" CGW
  SG_ MOIS_MuteActivationRequest2 : 17|2@0+ (1,0) [0|0] "" CGW
  SG_ Fatigue_ChoiceRequest2 : 19|2@0+ (1,0) [0|0] "" CGW
  SG_ Distraction_ChoiceRequest2 : 21|2@0+ (1,0) [0|0] "" CGW
  SG_ ESA_ActivationRequest2 : 23|2@0+ (1,0) [0|0] "" CGW

BO_ 1701 HEVC_A170: 7 CGW
  SG_ Acceptable_DC_CHG_Power_Display : 23|14@0+ (0.05,0) [0|500] "kW" IVI
  SG_ ActualChargeRate : 47|14@0+ (0.05,0) [0|500] "kW" IVI

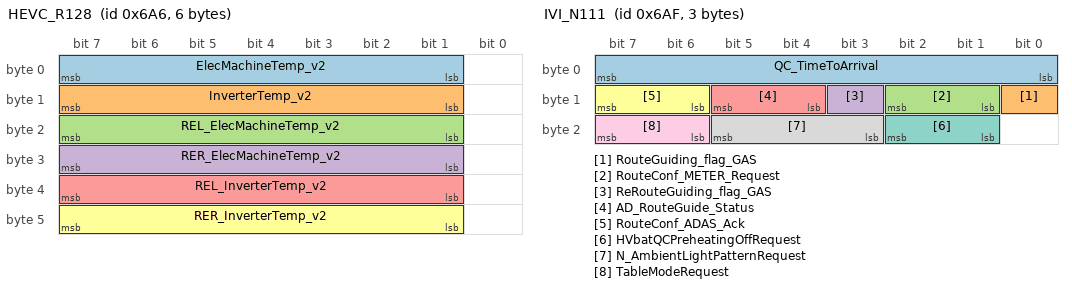
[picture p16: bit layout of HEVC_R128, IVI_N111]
BO_ 1702 HEVC_R128: 6 CGW
  SG_ ElecMachineTemp_v2 : 7|7@0+ (1,0) [0|100] "%" IVI
  SG_ InverterTemp_v2 : 15|7@0+ (1,0) [0|100] "%" IVI
  SG_ REL_ElecMachineTemp_v2 : 23|7@0+ (1,0) [0|100] "%" IVI
  SG_ RER_ElecMachineTemp_v2 : 31|7@0+ (1,0) [0|100] "%" IVI
  SG_ REL_InverterTemp_v2 : 39|7@0+ (1,0) [0|100] "%" IVI
  SG_ RER_InverterTemp_v2 : 47|7@0+ (1,0) [0|100] "%" IVI

BO_ 1703 BCM_R14: 6 CGW
  SG_ ProgrammedChargeStatus : 45|2@0+ (1,0) [0|0] "" IVI

BO_ 1705 FrCamADAS_R102: 7 CGW
  SG_ SpeedLimNotifActivationStatus : 7|2@0+ (1,0) [0|0] "" IVI

BO_ 1711 IVI_N111: 3 IVI
  SG_ QC_TimeToArrival : 7|8@0+ (1,0) [0|180] "min" CGW
  SG_ RouteGuiding_flag_GAS : 8|1@0+ (1,0) [0|0] "" CGW
  SG_ RouteConf_METER_Request : 10|2@0+ (1,0) [0|0] "" CGW
  SG_ ReRouteGuiding_flag_GAS : 11|1@0+ (1,0) [0|0] "" CGW
  SG_ AD_RouteGuide_Status : 13|2@0+ (1,0) [0|0] "" CGW
  SG_ RouteConf_ADAS_Ack : 15|2@0+ (1,0) [0|0] "" CGW
  SG_ HVbatQCPreheatingOffRequest : 18|2@0+ (1,0) [0|0] "" CGW
  SG_ N_AmbientLightPatternRequest : 21|3@0+ (1,0) [0|0] "" CGW
  SG_ TableModeRequest : 23|2@0+ (1,0) [0|0] "" CGW

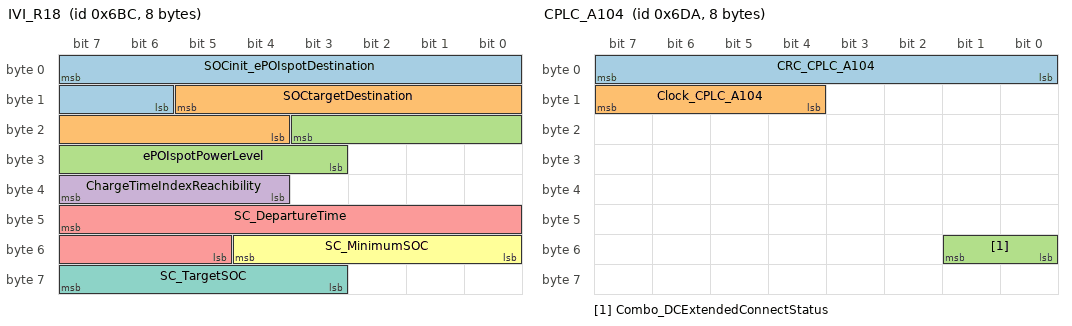
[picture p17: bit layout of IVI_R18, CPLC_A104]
BO_ 1724 IVI_R18: 8 IVI
  SG_ SOCinit_ePOIspotDestination : 7|10@0+ (0.1,0) [0|100] "%" CGW
  SG_ SOCtargetDestination : 13|10@0+ (0.1,0) [0|100] "%" CGW
  SG_ ePOIspotPowerLevel : 19|9@0+ (0.2,0) [0|100] "kW" CGW
  SG_ ChargeTimeIndexReachibility : 39|4@0+ (1,0) [0|0] "" CGW
  SG_ SC_DepartureTime : 47|11@0+ (5,0) [0|10080] "min" CGW
  SG_ SC_MinimumSOC : 52|5@0+ (5,0) [0|100] "%" CGW
  SG_ SC_TargetSOC : 63|5@0+ (5,0) [0|100] "%" CGW

BO_ 1737 HEVC_A22: 8 CGW
  SG_ HVBatteryTempMin_BLMS : 7|7@0+ (1,-40) [-40|80] "°C" IVI

BO_ 1742 ADAS_A124: 8 CGW
  SG_ ADmodeStatus_Slow : 55|3@0+ (1,0) [0|0] "" IVI

BO_ 1743 HEVC_R118: 8 CGW
  SG_ V2G_TotalDischargedEnergy_EVA : 39|15@0+ (5,0) [0|150000] "KWh" IVI

BO_ 1753 CPLC_A103: 7 CGW
  SG_ CPLC_FaultType : 51|4@0+ (1,0) [0|0] "" IVI

BO_ 1754 CPLC_A104: 8 CGW
  SG_ CRC_CPLC_A104 : 7|8@0+ (1,0) [0|255] "" IVI
  SG_ Clock_CPLC_A104 : 15|4@0+ (1,0) [0|15] "" IVI
  SG_ Combo_DCExtendedConnectStatus : 49|2@0+ (1,0) [0|0] "" IVI

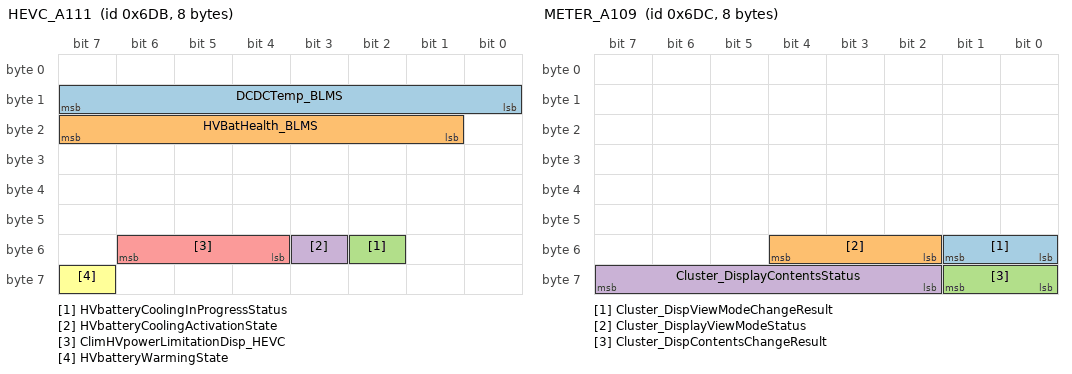
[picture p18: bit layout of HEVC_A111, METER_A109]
BO_ 1755 HEVC_A111: 8 CGW
  SG_ DCDCTemp_BLMS : 15|8@0+ (1,-40) [-40|214] "°C" IVI
  SG_ HVBatHealth_BLMS : 23|7@0+ (1,0) [0|126] "%" IVI
  SG_ HVbatteryCoolingInProgressStatus : 50|1@0+ (1,0) [0|0] "" IVI
  SG_ HVbatteryCoolingActivationState : 51|1@0+ (1,0) [0|0] "" IVI
  SG_ ClimHVpowerLimitationDisp_HEVC : 54|3@0+ (1,0) [0|0] "" IVI
  SG_ HVbatteryWarmingState : 63|1@0+ (1,0) [0|0] "" IVI

BO_ 1756 METER_A109: 8 CGW
  SG_ Cluster_DispViewModeChangeResult : 49|2@0+ (1,0) [0|0] "" IVI
  SG_ Cluster_DisplayViewModeStatus : 52|3@0+ (1,0) [0|0] "" IVI
  SG_ Cluster_DispContentsChangeResult : 57|2@0+ (1,0) [0|0] "" IVI
  SG_ Cluster_DisplayContentsStatus : 63|6@0+ (1,0) [0|0] "" IVI

BO_ 1768 IVI_N107: 8 IVI
  SG_ VideoType : 1|2@0+ (1,0) [0|0] "" CGW
  SG_ FaceID_RecognitionRequest : 3|2@0+ (1,0) [0|0] "" CGW
  SG_ FaceID_DeleteRequest : 6|3@0+ (1,0) [0|0] "" CGW
  SG_ FaceID_ActivationState : 7|1@0+ (1,0) [0|0] "" CGW
  SG_ DayNightUserRequest : 8|1@0+ (1,0) [0|0] "" CGW
  SG_ DVR_CameraView_Change : 10|2@0+ (1,0) [0|0] "" CGW
  SG_ DVR_Adjustment_Rotation : 12|2@0+ (1,0) [0|0] "" CGW
  SG_ FaceID_ResistrationRequest : 15|3@0+ (1,0) [0|0] "" CGW
  SG_ ContrastRequestINcam : 18|3@0+ (1,0) [0|0] "" CGW
  SG_ ContrastRequestFRcam : 21|3@0+ (1,0) [0|0] "" CGW
  SG_ VDCActivationRequest2 : 23|2@0+ (1,0) [0|0] "" CGW
  SG_ MMI_CommandList_2 : 28|5@0+ (1,0) [0|0] "" CGW
  SG_ ContrastRequestRRcam : 31|3@0+ (1,0) [0|0] "" CGW
  SG_ BrightnessRequest : 34|3@0+ (1,0) [0|0] "" CGW
  SG_ SelftimerRequest : 37|3@0+ (1,0) [0|0] "" CGW
  SG_ SetRecordQuality_HSL : 41|2@0+ (1,0) [0|0] "" CGW
  SG_ BrightnessRequestRRcam : 44|3@0+ (1,0) [0|0] "" CGW
  SG_ BrightnessRequestINcam : 47|3@0+ (1,0) [0|0] "" CGW
  SG_ AudioOnStatus : 48|1@0+ (1,0) [0|0] "" CGW
  SG_ WiFiSetting_v2 : 50|2@0+ (1,0) [0|0] "" CGW
  SG_ IlluminationControlReq : 55|5@0+ (1,0) [0|0] "" CGW
  SG_ GetSSIDandPassword : 56|1@0+ (1,0) [0|0] "" CGW
  SG_ GeneralRecordingSetting_v2 : 58|2@0+ (1,0) [0|0] "" CGW
  SG_ IlluminationContReqForCamera : 63|5@0+ (1,0) [0|0] "" CGW

BO_ 1769 IVI_N109: 1 IVI
  SG_ Navi_TollGateInformation : 7|8@0+ (1,0) [0|0] "" CGW

BO_ 1772 METER_A110: 8 CGW
  SG_ FuelGaugeDisplayValue : 47|7@0+ (1,0) [0|100] "%" IVI

BO_ 1774 HEVC_A166: 8 CGW
  SG_ V2X_MinSOClimitationLevelDisplay : 39|7@0+ (1,0) [0|100] "%" IVI
  SG_ V2X_SOClimitationLevelState : 47|7@0+ (1,0) [0|100] "%" IVI

BO_ 1775 TCU_A106: 3 CGW
  SG_ PnCcertificateTotalBlockNb_v2 : 7|12@0+ (1,0) [0|4095] "" IVI

BO_ 1776 METER_A121: 3 CGW
  SG_ SC_TargetSOC_Meter : 7|5@0+ (5,0) [0|100] "%" IVI
  SG_ RouteConf_IVI_Ack : 15|2@0+ (1,0) [0|0] "" IVI

BO_ 1779 IVI_R8: 8 IVI
  SG_ ChargeCal1DurationChange_MMI : 7|11@0+ (1,0) [0|1440] "min" CGW
  SG_ ChargeCal1BeginHourChange_MMI : 12|5@0+ (1,0) [0|23] "h" CGW
  SG_ ChargeCal1TuesdayChange_MMI : 16|1@0+ (1,0) [0|0] "" CGW
  SG_ ChargeCal1MondayChange_MMI : 17|1@0+ (1,0) [0|0] "" CGW
  SG_ ChargeCal1BeginMinChange_MMI : 23|6@0+ (1,0) [0|59] "min" CGW
  SG_ ChargeCal1SundayChange_MMI : 27|1@0+ (1,0) [0|0] "" CGW
  SG_ ChargeCal1SaturdayChange_MMI : 28|1@0+ (1,0) [0|0] "" CGW
  SG_ ChargeCal1FridayChange_MMI : 29|1@0+ (1,0) [0|0] "" CGW
  SG_ ChargeCal1ThursdayChange_MMI : 30|1@0+ (1,0) [0|0] "" CGW
  SG_ ChargeCal1WednesdayChange_MMI : 31|1@0+ (1,0) [0|0] "" CGW
  SG_ ChargeCal2DurationChange_MMI : 39|11@0+ (1,0) [0|1440] "min" CGW
  SG_ ChargeCal2BeginHourChange_MMI : 44|5@0+ (1,0) [0|23] "h" CGW
  SG_ ChargeCal2TuesdayChange_MMI : 48|1@0+ (1,0) [0|0] "" CGW
  SG_ ChargeCal2MondayChange_MMI : 49|1@0+ (1,0) [0|0] "" CGW
  SG_ ChargeCal2BeginMinChange_MMI : 55|6@0+ (1,0) [0|59] "min" CGW
  SG_ ChargeCalAllChange_MMI : 58|2@0+ (1,0) [0|0] "" CGW
  SG_ ChargeCal2SundayChange_MMI : 59|1@0+ (1,0) [0|0] "" CGW
  SG_ ChargeCal2SaturdayChange_MMI : 60|1@0+ (1,0) [0|0] "" CGW
  SG_ ChargeCal2FridayChange_MMI : 61|1@0+ (1,0) [0|0] "" CGW
  SG_ ChargeCal2ThursdayChange_MMI : 62|1@0+ (1,0) [0|0] "" CGW
  SG_ ChargeCal2WednesdayChange_MMI : 63|1@0+ (1,0) [0|0] "" CGW

BO_ 1780 IVI_R9: 8 IVI
  SG_ ChargeCal3DurationChange_MMI : 7|11@0+ (1,0) [0|1440] "min" CGW
  SG_ ChargeCal3BeginHourChange_MMI : 12|5@0+ (1,0) [0|23] "h" CGW
  SG_ ChargeCal3TuesdayChange_MMI : 16|1@0+ (1,0) [0|0] "" CGW
  SG_ ChargeCal3MondayChange_MMI : 17|1@0+ (1,0) [0|0] "" CGW
  SG_ ChargeCal3BeginMinChange_MMI : 23|6@0+ (1,0) [0|59] "min" CGW
  SG_ ChargeCal3SundayChange_MMI : 27|1@0+ (1,0) [0|0] "" CGW
  SG_ ChargeCal3SaturdayChange_MMI : 28|1@0+ (1,0) [0|0] "" CGW
  SG_ ChargeCal3FridayChange_MMI : 29|1@0+ (1,0) [0|0] "" CGW
  SG_ ChargeCal3ThursdayChange_MMI : 30|1@0+ (1,0) [0|0] "" CGW
  SG_ ChargeCal3WednesdayChange_MMI : 31|1@0+ (1,0) [0|0] "" CGW
  SG_ ChargeCal4DurationChange_MMI : 39|11@0+ (1,0) [0|1440] "min" CGW
  SG_ ChargeCal4BeginHourChange_MMI : 44|5@0+ (1,0) [0|23] "h" CGW
  SG_ ChargeCal4TuesdayChange_MMI : 48|1@0+ (1,0) [0|0] "" CGW
  SG_ ChargeCal4MondayChange_MMI : 49|1@0+ (1,0) [0|0] "" CGW
  SG_ ChargeCal4BeginMinChange_MMI : 55|6@0+ (1,0) [0|59] "min" CGW
  SG_ ChargeCal4SundayChange_MMI : 59|1@0+ (1,0) [0|0] "" CGW
  SG_ ChargeCal4SaturdayChange_MMI : 60|1@0+ (1,0) [0|0] "" CGW
  SG_ ChargeCal4FridayChange_MMI : 61|1@0+ (1,0) [0|0] "" CGW
  SG_ ChargeCal4ThursdayChange_MMI : 62|1@0+ (1,0) [0|0] "" CGW
  SG_ ChargeCal4WednesdayChange_MMI : 63|1@0+ (1,0) [0|0] "" CGW

BO_ 1781 IVI_R10: 8 IVI
  SG_ ChargeCal5DurationChange_MMI : 7|11@0+ (1,0) [0|1440] "min" CGW
  SG_ ChargeCal5BeginHourChange_MMI : 12|5@0+ (1,0) [0|23] "h" CGW
  SG_ ChargeCal5TuesdayChange_MMI : 16|1@0+ (1,0) [0|0] "" CGW
  SG_ ChargeCal5MondayChange_MMI : 17|1@0+ (1,0) [0|0] "" CGW
  SG_ ChargeCal5BeginMinChange_MMI : 23|6@0+ (1,0) [0|59] "min" CGW
  SG_ ChargeDelayedRequestValue : 26|11@0+ (1,1) [1|1440] "min" CGW
  SG_ ChargeCal5SundayChange_MMI : 27|1@0+ (1,0) [0|0] "" CGW
  SG_ ChargeCal5SaturdayChange_MMI : 28|1@0+ (1,0) [0|0] "" CGW
  SG_ ChargeCal5FridayChange_MMI : 29|1@0+ (1,0) [0|0] "" CGW
  SG_ ChargeCal5ThursdayChange_MMI : 30|1@0+ (1,0) [0|0] "" CGW
  SG_ ChargeCal5WednesdayChange_MMI : 31|1@0+ (1,0) [0|0] "" CGW
  SG_ EcoTripResetRequest : 40|1@0+ (1,0) [0|0] "" CGW
  SG_ SC_UserElecPriceSetNbSlot : 45|5@0+ (1,0) [0|24] "" CGW
  SG_ ChargeDelayedRequest : 46|1@0+ (1,0) [0|0] "" CGW
  SG_ ChargeAlwaysRequest : 47|1@0+ (1,0) [0|0] "" CGW
  SG_ SC_UserElecPriceSetSlotDuration : 55|5@0+ (30,0) [0|720] "min" CGW
  SG_ SC_UserElecPriceSetRelativeCost : 62|4@0+ (1,0) [0|15] "" CGW
  SG_ FuelSaveClearHistoRequest : 63|1@0+ (1,0) [0|0] "" CGW

BO_ 1782 IVI_R11: 7 IVI
  SG_ PreSoakCal1ArrivalHourChange_MMI : 1|5@0+ (1,0) [0|23] "h" CGW
  SG_ PreSoakCal1ArrivalMinChange_MMI : 7|6@0+ (1,0) [0|59] "min" CGW
  SG_ PreSoakCal1FridayChange_MMI : 8|1@0+ (1,0) [0|0] "" CGW
  SG_ PreSoakCal1ThursdayChange_MMI : 9|1@0+ (1,0) [0|0] "" CGW
  SG_ PreSoakCal1WednesdayChange_MMI : 10|1@0+ (1,0) [0|0] "" CGW
  SG_ PreSoakCal1TuesdayChange_MMI : 11|1@0+ (1,0) [0|0] "" CGW
  SG_ PreSoakCal1MondayChange_MMI : 12|1@0+ (1,0) [0|0] "" CGW
  SG_ PreSoakCal2ArrivalMinChange_MMI : 21|6@0+ (1,0) [0|59] "min" CGW
  SG_ PreSoakCal1SundayChange_MMI : 22|1@0+ (1,0) [0|0] "" CGW
  SG_ PreSoakCal1SaturdayChange_MMI : 23|1@0+ (1,0) [0|0] "" CGW
  SG_ PreSoakCal2WednesdayChange_MMI : 24|1@0+ (1,0) [0|0] "" CGW
  SG_ PreSoakCal2TuesdayChange_MMI : 25|1@0+ (1,0) [0|0] "" CGW
  SG_ PreSoakCal2MondayChange_MMI : 26|1@0+ (1,0) [0|0] "" CGW
  SG_ PreSoakCal2ArrivalHourChange_MMI : 31|5@0+ (1,0) [0|23] "h" CGW
  SG_ PreSoakCal3ArrivalMinChange_MMI : 35|6@0+ (1,0) [0|59] "min" CGW
  SG_ PreSoakCal2SundayChange_MMI : 36|1@0+ (1,0) [0|0] "" CGW
  SG_ PreSoakCal2SaturdayChange_MMI : 37|1@0+ (1,0) [0|0] "" CGW
  SG_ PreSoakCal2FridayChange_MMI : 38|1@0+ (1,0) [0|0] "" CGW
  SG_ PreSoakCal2ThursdayChange_MMI : 39|1@0+ (1,0) [0|0] "" CGW
  SG_ PreSoakCal3MondayChange_MMI : 40|1@0+ (1,0) [0|0] "" CGW
  SG_ PreSoakCal3ArrivalHourChange_MMI : 45|5@0+ (1,0) [0|23] "h" CGW
  SG_ PreSoakCalAllChange_MMI : 49|2@0+ (1,0) [0|0] "" CGW
  SG_ PreSoakCal3SundayChange_MMI : 50|1@0+ (1,0) [0|0] "" CGW
  SG_ PreSoakCal3SaturdayChange_MMI : 51|1@0+ (1,0) [0|0] "" CGW
  SG_ PreSoakCal3FridayChange_MMI : 52|1@0+ (1,0) [0|0] "" CGW
  SG_ PreSoakCal3ThursdayChange_MMI : 53|1@0+ (1,0) [0|0] "" CGW
  SG_ PreSoakCal3WednesdayChange_MMI : 54|1@0+ (1,0) [0|0] "" CGW
  SG_ PreSoakCal3TuesdayChange_MMI : 55|1@0+ (1,0) [0|0] "" CGW

BO_ 1783 IVI_R12: 7 IVI
  SG_ PreSoakCal4ArrivalHourChange_MMI : 1|5@0+ (1,0) [0|23] "h" CGW
  SG_ PreSoakCal4ArrivalMinChange_MMI : 7|6@0+ (1,0) [0|59] "min" CGW
  SG_ PreSoakCal4FridayChange_MMI : 8|1@0+ (1,0) [0|0] "" CGW
  SG_ PreSoakCal4ThursdayChange_MMI : 9|1@0+ (1,0) [0|0] "" CGW
  SG_ PreSoakCal4WednesdayChange_MMI : 10|1@0+ (1,0) [0|0] "" CGW
  SG_ PreSoakCal4TuesdayChange_MMI : 11|1@0+ (1,0) [0|0] "" CGW
  SG_ PreSoakCal4MondayChange_MMI : 12|1@0+ (1,0) [0|0] "" CGW
  SG_ PreSoakCal5ArrivalMinChange_MMI : 21|6@0+ (1,0) [0|59] "min" CGW
  SG_ PreSoakCal4SundayChange_MMI : 22|1@0+ (1,0) [0|0] "" CGW
  SG_ PreSoakCal4SaturdayChange_MMI : 23|1@0+ (1,0) [0|0] "" CGW
  SG_ PreSoakCal5WednesdayChange_MMI : 24|1@0+ (1,0) [0|0] "" CGW
  SG_ PreSoakCal5TuesdayChange_MMI : 25|1@0+ (1,0) [0|0] "" CGW
  SG_ PreSoakCal5MondayChange_MMI : 26|1@0+ (1,0) [0|0] "" CGW
  SG_ PreSoakCal5ArrivalHourChange_MMI : 31|5@0+ (1,0) [0|23] "h" CGW
  SG_ GainECOdistanceDisplay : 35|13@0+ (0.1,0) [0|800] "wu" CGW
  SG_ PreSoakCal5SundayChange_MMI : 36|1@0+ (1,0) [0|0] "" CGW
  SG_ PreSoakCal5SaturdayChange_MMI : 37|1@0+ (1,0) [0|0] "" CGW
  SG_ PreSoakCal5FridayChange_MMI : 38|1@0+ (1,0) [0|0] "" CGW
  SG_ PreSoakCal5ThursdayChange_MMI : 39|1@0+ (1,0) [0|0] "" CGW

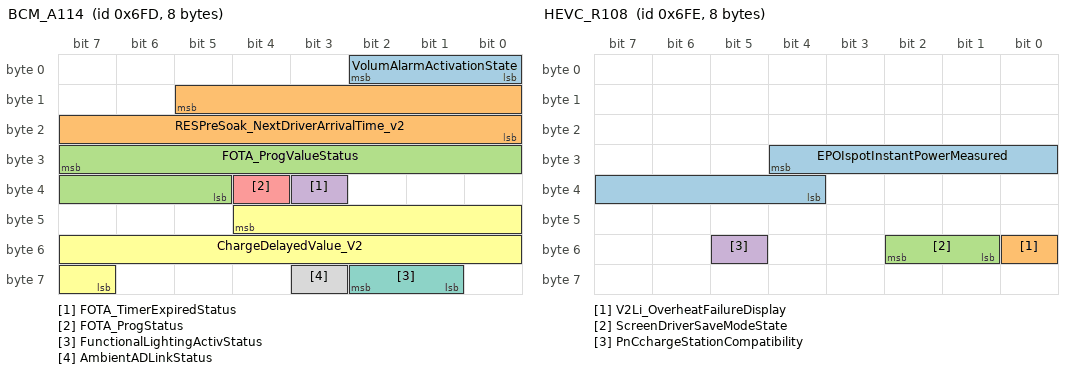
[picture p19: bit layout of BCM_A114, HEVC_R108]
BO_ 1789 BCM_A114: 8 CGW
  SG_ VolumAlarmActivationState : 2|3@0+ (1,0) [0|0] "" IVI
  SG_ RESPreSoak_NextDriverArrivalTime_v2 : 13|14@0+ (1,0) [0|10080] "min" IVI
  SG_ FOTA_ProgValueStatus : 31|11@0+ (1,0) [0|1440] "min" IVI
  SG_ FOTA_TimerExpiredStatus : 35|1@0+ (1,0) [0|0] "" IVI
  SG_ FOTA_ProgStatus : 36|1@0+ (1,0) [0|0] "" IVI
  SG_ ChargeDelayedValue_V2 : 44|14@0+ (1,0) [0|10080] "min" IVI
  SG_ FunctionalLightingActivStatus : 58|2@0+ (1,0) [0|0] "" IVI
  SG_ AmbientADLinkStatus : 59|1@0+ (1,0) [0|0] "" IVI

BO_ 1790 HEVC_R108: 8 CGW
  SG_ EPOIspotInstantPowerMeasured : 28|9@0+ (0.2,0) [0|100] "kW" IVI
  SG_ V2Li_OverheatFailureDisplay : 48|1@0+ (1,0) [0|0] "" IVI
  SG_ ScreenDriverSaveModeState : 50|2@0+ (1,0) [0|0] "" IVI
  SG_ PnCchargeStationCompatibility : 53|1@0+ (1,0) [0|0] "" IVI

BO_ 1791 HEVC_R109: 8 CGW
  SG_ ElecAutonomyGainClimOffDisplay : 7|8@0+ (1,0) [0|250] "km" IVI
  SG_ FuelSaveSinceClearHistoZEV : 28|14@0+ (0.1,0) [0|1024] "" IVI

BO_ 1799 DTOOL_to_eHBox: 8 CGW
  SG_ DTOOL_to_eHBox : 7|64@0+ (1,0) [0|0] "" eHBox

BO_ 1810 DTOOL_to_Radio: 8 CGW
  SG_ DTOOL_to_Radio : 7|64@0+ (1,0) [0|0] "" IVI

BO_ 1812 DTOOL_to_CPANEL: 8 CGW
  SG_ DTOOL_to_CPANEL : 7|64@0+ (1,0) [0|0] "" IVI

BO_ 1842 Radio_to_DTOOL: 8 IVI
  SG_ Radio_to_DTOOL : 7|64@0+ (1,0) [0|0] "" CGW

BO_ 1844 CPANEL_to_DTOOL: 8 IVI
  SG_ CPANEL_to_DTOOL : 7|64@0+ (1,0) [0|0] "" CGW

BO_ 1863 DTOOL_to_NAV: 8 CGW
  SG_ DTOOL_to_NAV : 7|64@0+ (1,0) [0|0] "" IVI

BO_ 1895 NAV_to_DTOOL: 8 IVI
  SG_ NAV_to_DTOOL : 7|64@0+ (1,0) [0|0] "" CGW

BO_ 1975 DTOOL_to_AVM_SD: 8 CGW
  SG_ DTOOL_to_AVM_SD : 7|64@0+ (1,0) [0|0] "" AVM_SD

BO_ 1978 AVM_SD_to_DTOOL: 8 AVM_SD
  SG_ AVM_SD_to_DTOOL : 7|64@0+ (1,0) [0|0] "" CGW

BO_ 2563507968 SIGMA_CDMTriggerFrame: 7 CGW
  SG_ SIGMA_CDM : 4|29@0+ (1,0) [0|0] "" IVI,eHBox
  SG_ SIGMA_DTCCDM : 39|24@0+ (1,0) [0|0] "" IVI,eHBox

BO_ 2563508007 SIGMA_eHBoxTriggerFrame: 7 eHBox
  SG_ SIGMA_eHBox : 4|29@0+ (1,0) [0|0] "" CGW,IVI
  SG_ SIGMA_DTCeHBox : 39|24@0+ (1,0) [0|0] "" CGW,IVI

BO_ 2563508009 SIGMA_PSD_RTriggerFrame: 7 CGW
  SG_ SIGMA_PSD_R : 4|29@0+ (1,0) [0|0] "" IVI,eHBox
  SG_ SIGMA_DTCPSD_R : 39|24@0+ (1,0) [0|0] "" IVI,eHBox

BO_ 2563508019 SIGMA_PBDTriggerFrame: 7 CGW
  SG_ SIGMA_PBD : 4|29@0+ (1,0) [0|0] "" IVI,eHBox
  SG_ SIGMA_DTCPBD : 39|24@0+ (1,0) [0|0] "" IVI,eHBox

BO_ 2563508021 SIGMA_RADARTriggerFrame: 7 CGW
  SG_ SIGMA_RADAR : 4|29@0+ (1,0) [0|0] "" IVI,eHBox
  SG_ SIGMA_DTCRADAR : 39|24@0+ (1,0) [0|0] "" IVI,eHBox

BO_ 2563508022 SIGMA_PSCUTriggerFrame: 7 CGW
  SG_ SIGMA_PSCU : 4|29@0+ (1,0) [0|0] "" IVI,eHBox
  SG_ SIGMA_DTCPSCU : 39|24@0+ (1,0) [0|0] "" IVI,eHBox

BO_ 2563508030 SIGMA_SRad_RLTriggerFrame: 7 CGW
  SG_ SIGMA_SRad_RL : 4|29@0+ (1,0) [0|0] "" IVI,eHBox
  SG_ SIGMA_DTCSRad_RL : 39|24@0+ (1,0) [0|0] "" IVI,eHBox

BO_ 2563508035 SIGMA_eRDC_LTriggerFrame: 7 CGW
  SG_ SIGMA_eRDC_L : 4|29@0+ (1,0) [0|0] "" IVI,eHBox
  SG_ SIGMA_DTCeRDC_L : 39|24@0+ (1,0) [0|0] "" IVI,eHBox

BO_ 2563508037 SIGMA_eRDC_RTriggerFrame: 7 CGW
  SG_ SIGMA_eRDC_R : 4|29@0+ (1,0) [0|0] "" IVI,eHBox
  SG_ SIGMA_DTCeRDC_R : 39|24@0+ (1,0) [0|0] "" IVI,eHBox

BO_ 2563508042 SIGMA_ANCTriggerFrame: 7 CGW
  SG_ SIGMA_ANC : 4|29@0+ (1,0) [0|0] "" IVI,eHBox
  SG_ SIGMA_DTCANC : 39|24@0+ (1,0) [0|0] "" IVI,eHBox

BO_ 2563508064 SIGMA_VDCTriggerFrame: 7 CGW
  SG_ SIGMA_VDC : 4|29@0+ (1,0) [0|0] "" IVI,eHBox
  SG_ SIGMA_DTCVDC : 39|24@0+ (1,0) [0|0] "" IVI,eHBox

BO_ 2563508066 SIGMA_EPSTriggerFrame: 7 CGW
  SG_ SIGMA_EPS : 4|29@0+ (1,0) [0|0] "" IVI,eHBox
  SG_ SIGMA_DTCEPS : 39|24@0+ (1,0) [0|0] "" IVI,eHBox

BO_ 2563508067 SIGMA_METERTriggerFrame: 7 CGW
  SG_ SIGMA_METER : 4|29@0+ (1,0) [0|0] "" IVI,eHBox
  SG_ SIGMA_DTCMETER : 39|24@0+ (1,0) [0|0] "" IVI,eHBox

BO_ 2563508068 SIGMA_HVACTriggerFrame: 7 CGW
  SG_ SIGMA_HVAC : 4|29@0+ (1,0) [0|0] "" IVI,eHBox
  SG_ SIGMA_DTCHVAC : 39|24@0+ (1,0) [0|0] "" IVI,eHBox

BO_ 2563508069 SIGMA_BCMTriggerFrame: 7 CGW
  SG_ SIGMA_BCM : 4|29@0+ (1,0) [0|0] "" IVI,eHBox
  SG_ SIGMA_DTCBCM : 39|24@0+ (1,0) [0|0] "" IVI,eHBox

BO_ 2563508071 SIGMA_IVITriggerFrame: 7 IVI
  SG_ SIGMA_IVI : 4|29@0+ (1,0) [0|0] "" CGW,eHBox
  SG_ SIGMA_DTCIVI : 39|24@0+ (1,0) [0|0] "" CGW,eHBox

BO_ 2563508072 SIGMA_4WDTriggerFrame: 7 CGW
  SG_ SIGMA_4WD : 4|29@0+ (1,0) [0|0] "" IVI,eHBox
  SG_ SIGMA_DTC4WD : 39|24@0+ (1,0) [0|0] "" IVI,eHBox

BO_ 2563508077 SIGMA_USMTriggerFrame: 7 CGW
  SG_ SIGMA_USM : 4|29@0+ (1,0) [0|0] "" IVI,eHBox
  SG_ SIGMA_DTCUSM : 39|24@0+ (1,0) [0|0] "" IVI,eHBox

BO_ 2563508078 SIGMA_SONARTriggerFrame: 7 CGW
  SG_ SIGMA_SONAR : 4|29@0+ (1,0) [0|0] "" IVI,eHBox
  SG_ SIGMA_DTCSONAR : 39|24@0+ (1,0) [0|0] "" IVI,eHBox

BO_ 2563508079 SIGMA_DSMUTriggerFrame: 7 CGW
  SG_ SIGMA_DSMU : 4|29@0+ (1,0) [0|0] "" IVI,eHBox
  SG_ SIGMA_DTCDSMU : 39|24@0+ (1,0) [0|0] "" IVI,eHBox

BO_ 2563508082 SIGMA_ACUTriggerFrame: 7 CGW
  SG_ SIGMA_ACU : 4|29@0+ (1,0) [0|0] "" IVI,eHBox
  SG_ SIGMA_DTCACU : 39|24@0+ (1,0) [0|0] "" IVI,eHBox

BO_ 2563508089 SIGMA_PSD_LTriggerFrame: 7 CGW
  SG_ SIGMA_PSD_L : 4|29@0+ (1,0) [0|0] "" IVI,eHBox
  SG_ SIGMA_DTCPSD_L : 39|24@0+ (1,0) [0|0] "" IVI,eHBox

BO_ 2563508093 SIGMA_ADASTriggerFrame: 7 CGW
  SG_ SIGMA_ADAS : 4|29@0+ (1,0) [0|0] "" IVI,eHBox
  SG_ SIGMA_DTCADAS : 39|24@0+ (1,0) [0|0] "" IVI,eHBox

BO_ 2563508099 SIGMA_A_IVCTriggerFrame: 7 CGW
  SG_ SIGMA_A_IVC : 4|29@0+ (1,0) [0|0] "" IVI,eHBox
  SG_ SIGMA_DTCA_IVC : 39|24@0+ (1,0) [0|0] "" IVI,eHBox

BO_ 2563508108 SIGMA_INV_METriggerFrame: 7 CGW
  SG_ SIGMA_INV_ME : 4|29@0+ (1,0) [0|0] "" IVI,eHBox
  SG_ SIGMA_DTCINV_ME : 39|24@0+ (1,0) [0|0] "" IVI,eHBox

BO_ 2563508115 SIGMA_OBC_ACTriggerFrame: 7 CGW
  SG_ SIGMA_OBC_AC : 4|29@0+ (1,0) [0|0] "" IVI,eHBox
  SG_ SIGMA_DTCOBC_AC : 39|24@0+ (1,0) [0|0] "" IVI,eHBox

BO_ 2563508122 SIGMA_HEVCTriggerFrame: 7 CGW
  SG_ SIGMA_HEVC : 4|29@0+ (1,0) [0|0] "" IVI,eHBox
  SG_ SIGMA_DTCHEVC : 39|24@0+ (1,0) [0|0] "" IVI,eHBox

BO_ 2563508130 SIGMA_AUDIOampTriggerFrame: 7 CGW
  SG_ SIGMA_AUDIOamp : 4|29@0+ (1,0) [0|0] "" IVI,eHBox
  SG_ SIGMA_DTCAUDIOamp : 39|24@0+ (1,0) [0|0] "" IVI,eHBox

BO_ 2563508133 SIGMA_HNSTriggerFrame: 7 CGW
  SG_ SIGMA_HNS : 4|29@0+ (1,0) [0|0] "" IVI,eHBox
  SG_ SIGMA_DTCHNS : 39|24@0+ (1,0) [0|0] "" IVI,eHBox

BO_ 2563508139 SIGMA_VKMTriggerFrame: 7 CGW
  SG_ SIGMA_VKM : 4|29@0+ (1,0) [0|0] "" IVI,eHBox
  SG_ SIGMA_DTCVKM : 39|24@0+ (1,0) [0|0] "" IVI,eHBox

BO_ 2563508153 SIGMA_HFMTriggerFrame: 7 CGW
  SG_ SIGMA_HFM : 4|29@0+ (1,0) [0|0] "" IVI,eHBox
  SG_ SIGMA_DTCHFM : 39|24@0+ (1,0) [0|0] "" IVI,eHBox

BO_ 2563508154 SIGMA_AVMTriggerFrame: 7 CGW
  SG_ SIGMA_AVM : 4|29@0+ (1,0) [0|0] "" IVI,eHBox
  SG_ SIGMA_DTCAVM : 39|24@0+ (1,0) [0|0] "" IVI,eHBox

BO_ 2563508157 SIGMA_SCUTriggerFrame: 7 CGW
  SG_ SIGMA_SCU : 4|29@0+ (1,0) [0|0] "" IVI,eHBox
  SG_ SIGMA_DTCSCU : 39|24@0+ (1,0) [0|0] "" IVI,eHBox

BO_ 2563508164 SIGMA_eShifterTriggerFrame: 7 CGW
  SG_ SIGMA_eShifter : 4|29@0+ (1,0) [0|0] "" IVI,eHBox
  SG_ SIGMA_DTCeShifter : 39|24@0+ (1,0) [0|0] "" IVI,eHBox

BO_ 2563508181 SIGMA_SRad_RRTriggerFrame: 7 CGW
  SG_ SIGMA_SRad_RR : 4|29@0+ (1,0) [0|0] "" IVI,eHBox
  SG_ SIGMA_DTCSRad_RR : 39|24@0+ (1,0) [0|0] "" IVI,eHBox

BO_ 2563508189 SIGMA_FrCameraTriggerFrame: 7 CGW
  SG_ SIGMA_FrCamera : 4|29@0+ (1,0) [0|0] "" IVI,eHBox
  SG_ SIGMA_DTCFrCamera : 39|24@0+ (1,0) [0|0] "" IVI,eHBox

BO_ 2563508200 SIGMA_ECMTriggerFrame: 7 CGW
  SG_ SIGMA_ECM : 4|29@0+ (1,0) [0|0] "" IVI,eHBox
  SG_ SIGMA_DTCECM : 39|24@0+ (1,0) [0|0] "" IVI,eHBox

BO_ 2563508201 SIGMA_ATCUTriggerFrame: 7 CGW
  SG_ SIGMA_ATCU : 4|29@0+ (1,0) [0|0] "" IVI,eHBox
  SG_ SIGMA_DTCATCU : 39|24@0+ (1,0) [0|0] "" IVI,eHBox

BO_ 2563508205 SIGMA_BMS_HVTriggerFrame: 7 CGW
  SG_ SIGMA_BMS_HV : 4|29@0+ (1,0) [0|0] "" IVI,eHBox
  SG_ SIGMA_DTCBMS_HV : 39|24@0+ (1,0) [0|0] "" IVI,eHBox

BO_ 2563508207 SIGMA_INV_HSGTriggerFrame: 7 CGW
  SG_ SIGMA_INV_HSG : 4|29@0+ (1,0) [0|0] "" IVI,eHBox
  SG_ SIGMA_DTCINV_HSG : 39|24@0+ (1,0) [0|0] "" IVI,eHBox

BO_ 2563567883 SIGMA_BMS_12VTriggerFrame: 7 CGW
  SG_ SIGMA_BMS_12V : 4|29@0+ (1,0) [0|0] "" IVI,eHBox
  SG_ SIGMA_DTCBMS_12V : 39|24@0+ (1,0) [0|0] "" IVI,eHBox

BO_ 2563567951 SIGMA_EPS_subTriggerFrame: 7 CGW
  SG_ SIGMA_EPS_sub : 4|29@0+ (1,0) [0|0] "" IVI,eHBox
  SG_ SIGMA_DTCEPS_sub : 39|24@0+ (1,0) [0|0] "" IVI,eHBox

BO_ 2563567958 SIGMA_eShiftActTriggerFrame: 7 CGW
  SG_ SIGMA_eShiftAct : 4|29@0+ (1,0) [0|0] "" IVI,eHBox
  SG_ SIGMA_DTCeShiftAct : 39|24@0+ (1,0) [0|0] "" IVI,eHBox

BO_ 2563567968 SIGMA_HUDTriggerFrame: 7 CGW
  SG_ SIGMA_HUD : 4|29@0+ (1,0) [0|0] "" IVI,eHBox
  SG_ SIGMA_DTCHUD : 39|24@0+ (1,0) [0|0] "" IVI,eHBox

BO_ 2563568024 SIGMA_HPCUTriggerFrame: 7 CGW
  SG_ SIGMA_HPCU : 4|29@0+ (1,0) [0|0] "" IVI,eHBox
  SG_ SIGMA_DTCHPCU : 39|24@0+ (1,0) [0|0] "" IVI,eHBox

BO_ 2563568093 SIGMA_DCDC_HVTriggerFrame: 7 CGW
  SG_ SIGMA_DCDC_HV : 4|29@0+ (1,0) [0|0] "" IVI,eHBox
  SG_ SIGMA_DTCDCDC_HV : 39|24@0+ (1,0) [0|0] "" IVI,eHBox

BO_ 2563568098 SIGMA_EBATriggerFrame: 7 CGW
  SG_ SIGMA_EBA : 4|29@0+ (1,0) [0|0] "" IVI,eHBox
  SG_ SIGMA_DTCEBA : 39|24@0+ (1,0) [0|0] "" IVI,eHBox

BO_ 2563568101 SIGMA_INV_RETriggerFrame: 7 CGW
  SG_ SIGMA_INV_RE : 4|29@0+ (1,0) [0|0] "" IVI,eHBox
  SG_ SIGMA_DTCINV_RE : 39|24@0+ (1,0) [0|0] "" IVI,eHBox

BO_ 2563568130 SIGMA_AirSUSPTriggerFrame: 7 CGW
  SG_ SIGMA_AirSUSP : 4|29@0+ (1,0) [0|0] "" IVI,eHBox
  SG_ SIGMA_DTCAirSUSP : 39|24@0+ (1,0) [0|0] "" IVI,eHBox

BO_ 2563568148 SIGMA_BSGTriggerFrame: 7 CGW
  SG_ SIGMA_BSG : 4|29@0+ (1,0) [0|0] "" IVI,eHBox
  SG_ SIGMA_DTCBSG : 39|24@0+ (1,0) [0|0] "" IVI,eHBox

BO_ 2563568163 SIGMA_SRad_FL_TriggerFrame: 7 CGW
  SG_ SIGMA_SRad_FL : 4|29@0+ (1,0) [0|0] "" IVI,eHBox
  SG_ SIGMA_DTCSRad_FL : 39|24@0+ (1,0) [0|0] "" IVI,eHBox

BO_ 2563568164 SIGMA_SRad_FRTriggerFrame: 7 CGW
  SG_ SIGMA_SRad_FR : 4|29@0+ (1,0) [0|0] "" IVI,eHBox
  SG_ SIGMA_DTCSRad_FR : 39|24@0+ (1,0) [0|0] "" IVI,eHBox

BO_ 2563568201 SIGMA_STBWTriggerFrame: 7 CGW
  SG_ SIGMA_STBW : 4|29@0+ (1,0) [0|0] "" IVI,eHBox
  SG_ SIGMA_DTCSTBW : 39|24@0+ (1,0) [0|0] "" IVI,eHBox

BO_ 2563568233 SIGMA_DMCTriggerFrame: 7 CGW
  SG_ SIGMA_DMC : 4|29@0+ (1,0) [0|0] "" IVI,eHBox
  SG_ SIGMA_DTCDMC : 39|24@0+ (1,0) [0|0] "" IVI,eHBox

BO_ 2563568267 SIGMA_RSCU3RTriggerFrame: 7 CGW
  SG_ SIGMA_RSCU3R : 4|29@0+ (1,0) [0|0] "" IVI,eHBox
  SG_ SIGMA_DTCRSCU3R : 39|24@0+ (1,0) [0|0] "" IVI,eHBox

BO_ 2563568288 SIGMA_BLM_RPKTriggerFrame: 7 CGW
  SG_ SIGMA_BLM_RPK : 4|29@0+ (1,0) [0|0] "" IVI,eHBox
  SG_ SIGMA_DTCBLM_RPK : 39|24@0+ (1,0) [0|0] "" IVI,eHBox

BO_ 2563568290 SIGMA_SCCMTriggerFrame: 7 CGW
  SG_ SIGMA_SCCM : 4|29@0+ (1,0) [0|0] "" IVI,eHBox
  SG_ SIGMA_DTCSCCM : 39|24@0+ (1,0) [0|0] "" IVI,eHBox

BO_ 2563568300 SIGMA_RSCU2RTriggerFrame: 7 CGW
  SG_ SIGMA_RSCU2R : 4|29@0+ (1,0) [0|0] "" IVI,eHBox
  SG_ SIGMA_DTCRSCU2R : 39|24@0+ (1,0) [0|0] "" IVI,eHBox

BO_ 2564460018 DTOOL_to_FCP: 8 CGW
  SG_ DTOOL_to_FCP : 7|64@0+ (1,0) [0|0] "" IVI

BO_ 2564460274 DTOOL_to_RCP: 8 CGW
  SG_ DTOOL_to_RCP : 7|64@0+ (1,0) [0|0] "" IVI

BO_ 2564485773 FCP_to_DTOOL: 8 IVI
  SG_ FCP_to_DTOOL : 7|64@0+ (1,0) [0|0] "" CGW

BO_ 2564485774 RCP_to_DTOOL: 8 IVI
  SG_ RCP_to_DTOOL : 7|64@0+ (1,0) [0|0] "" CGW

BO_ 2609102848 CGW_WakeUpFrame_extd: 2 CGW
  SG_ CGW_WakeUp_Signal : 7|16@0+ (1,0) [0|0] "" IVI

BO_ 2615050482 FTOOLS_IVCtoSWMC: 8 CGW
  SG_ FTOOLS_IVCtoSWMC : 7|64@0+ (1,0) [0|0] "" IVI

BO_ 2615070962 FTOOLS_SWMCtoCGW: 8 IVI
  SG_ FTOOLS_SWMCtoCGW : 7|64@0+ (1,0) [0|0] "" CGW

BO_ 2615079552 FTOOLS_SWMCtoIVC: 8 IVI
  SG_ FTOOLS_SWMCtoIVC : 7|64@0+ (1,0) [0|0] "" CGW

BO_ 2615079632 FTOOLS_CGWtoSWMC: 8 CGW
  SG_ FTOOLS_CGWtoSWMC : 7|64@0+ (1,0) [0|0] "" IVI

VAL_ 1543 SilentModeActivationState 0 "Silent mode is Deactivated" 1 "Silent mode is Activated";
VAL_ 1543 MirrorDownDisplayRequest 0 "No mirror down display request" 1 "Mirror down display request";
VAL_ 1543 MirrorUpDisplayRequest 0 "No mirror up display request" 1 "Mirror up display request";
VAL_ 1543 MirrorRightDisplayRequest 0 "No mirror right display request" 1 "Mirror right display request";
VAL_ 1543 MirrorLeftDisplayRequest 0 "No mirror left display request" 1 "Mirror left display request";
VAL_ 1543 MirrorSideSelectDisplayRequest 0 "No mirror selected" 1 "Left mirror selected" 2 "Right mirror selected" 3 "Not Used";
VAL_ 1543 AmbiLightColorStatus_v2 0 "Color 1" 1 "Color 2" 2 "Color 3" 3 "Color 4" 4 "Color 5" 5 "Color 6" 6 "Color 7" 7 "Color 8" 8 "Color 9" 9 "Color 10" 10 "Color 11" 11 "Color 12" 12 "Color 13" 13 "Color 14" 14 "Color 15" 15 "Color 16" 16 "Color 17" 17 "Color 18" 18 "Color 19" 19 "Color 20" 20 "Color 21" 21 "Color 22" 22 "Color 23" 23 "Color 24" 24 "Color 25" 25 "Color 26" 26 "Color 27" 27 "Color 28" 28 "Color 29" 29 "Color 30" 30 "Color 31" 31 "Color 32" 32 "Color 33" 33 "Color 34" 34 "Color 35" 35 "Color 36" 36 "Color 37" 37 "Color 38" 38 "Color 39" 39 "Color 40" 40 "Color 41" 41 "Color 42" 42 "Color 43" 43 "Color 44" 44 "Color 45" 45 "Color 46" 46 "Color 47" 47 "Color 48" 48 "Color 49" 49 "Color 50" 50 "Color 51" 51 "Color 52" 52 "Color 53" 53 "Color 54" 54 "Color 55" 55 "Color 56" 56 "Color 57" 57 "Color 58" 58 "Color 59" 59 "Color 60" 60 "Color 61" 61 "Color 62" 62 "Color 63" 63 "Color 64" 64 "Color 65" 65 "Color 66" 66 "Color 67" 67 "Color 68" 68 "Color 69" 69 "Color 70" 70 "Color 71" 71 "Color 72" 72 "Color 73" 73 "Color 74" 74 "Color 75" 75 "Color 76" 76 "Color 77" 77 "Color 78" 78 "Color 79" 79 "Color 80" 80 "Color 81" 81 "Color 82" 82 "Color 83" 83 "Color 84" 84 "Color 85" 85 "Color 86" 86 "Color 87" 87 "Color 88" 88 "Color 89" 89 "Color 90" 90 "Color 91" 91 "Color 92" 92 "Color 93" 93 "Color 94" 94 "Color 95" 95 "Color 96" 96 "Color 97" 97 "Color 98" 98 "Color 99" 99 "Color 100" 100 "Color 101" 101 "Color 102" 102 "Color 103" 103 "Color 104" 104 "Color 105" 105 "Color 106" 106 "Color 107" 107 "Color 108" 108 "Color 109" 109 "Color 110" 110 "Color 111" 111 "Color 112" 112 "Color 113" 113 "Color 114" 114 "Color 115" 115 "Color 116" 116 "Color 117" 117 "Color 118" 118 "Color 119" 119 "Color 120" 120 "Color 121" 121 "Color 122" 122 "Color 123" 123 "Color 124" 124 "Color 125" 125 "Color 126" 126 "Color 127" 127 "Color 128";
VAL_ 1543 VR_AuthCondition_RL 0 "Not satisfied" 1 "Satisfied";
VAL_ 1543 VR_AuthCondition_FR 0 "Not satisfied" 1 "Satisfied";
VAL_ 1543 VR_AuthCondition_FL 0 "Not satisfied" 1 "Satisfied";
VAL_ 1543 VR_AuthCondition_SSU 0 "Not satisfied" 1 "Satisfied";
VAL_ 1543 VR_AuthCondition_SRU 0 "Not satisfied" 1 "Satisfied";
VAL_ 1543 VR_AuthCondition_RR 0 "Not satisfied" 1 "Satisfied";
VAL_ 1543 EcoAdviceTirePressureRR_twin 0 "No Advice" 1 "Advice";
VAL_ 1543 EcoAdviceTirePressureRL_twin 0 "No Advice" 1 "Advice";
VAL_ 1549 DriverSwitchMassageRequest 0 "No massage request" 1 "Massage Request";
VAL_ 1549 MC_TutoControlsInhibitionReq 0 "No request" 1 "Controls inhibition request";
VAL_ 1549 MC_SeatAtSecureStopDisplayReq 0 "No display request" 1 "Seat at X secure stop" 2 "seat beyond secure stop Magic cockpit is now OFF" 3 "Seat at X secure stop Tuto will be reset to do it again" 4 "Not used" 5 "Not used" 6 "Not used" 7 "Not used";
VAL_ 1553 SecondRowCentralSeatStatus 0 "Unavailable" 1 "OFF display" 2 "Heater Low display" 3 "Heater Middle display" 4 "Heater High display" 5 "Ventilated Low display" 6 "Ventilated Middle display" 7 "Ventilated High display";
VAL_ 1553 ClimForcedFreshDisplayStatus 0 "Function not available" 1 "Function available";
VAL_ 1553 ClimForcedRecyDisplayStatus 0 "Function not available" 1 "Function available";
VAL_ 1553 ClimForcedFreshDisplay 0 "No display" 1 "Fresh ON" 2 "Fresh OFF" 3 "Not Used";
VAL_ 1553 ClimAQSSensitivityDisplay 0 "No display" 1 "Level 1" 2 "Level 2" 3 "Level 3" 4 "Level 4" 5 "Level 5" 6 "OFF" 7 "Not used";
VAL_ 1553 ClimExternalAirPollutionDisplay 0 "No display" 1 "LEVEL 1" 2 "LEVEL 2" 3 "LEVEL 3" 4 "LEVEL 4" 5 "LEVEL 5" 6 "Not used" 7 "Not used";
VAL_ 1553 ClimRearDefrostDisplayStatus 0 "Function not available" 1 "Function available";
VAL_ 1553 ClimExternAirPollutioDispStatus 0 "Function not available" 1 "Function available";
VAL_ 1553 ClimLinkPriorityFLSeatAutoDisp 0 "No display" 1 "Level 1" 2 "Level 2" 3 "Level 3" 4 "Level 4" 5 "Level 5" 6 "OFF" 7 "Not used";
VAL_ 1553 ClimLinkPriorityFRSeatAutoDisp 0 "No display" 1 "Level 1" 2 "Level 2" 3 "Level 3" 4 "Level 4" 5 "Level 5" 6 "OFF" 7 "Not used";
VAL_ 1553 FrontRightSeatDisplayStatus 0 "Function not available" 1 "Function available";
VAL_ 1553 FrontRightSeatStatus 0 "Unavailable" 1 "OFF display" 2 "Heater Low display" 3 "Heater Middle display" 4 "Heater High display" 5 "Ventilated Low display" 6 "Ventilated Middle display" 7 "Ventilated High display";
VAL_ 1553 FrontLeftSeatStatus 0 "Unavailable" 1 "OFF display" 2 "Heater Low display" 3 "Heater Middle display" 4 "Heater High display" 5 "Ventilated Low display" 6 "Ventilated Middle display" 7 "Ventilated High display";
VAL_ 1553 FrontLeftSeatDisplayStatus 0 "Function not available" 1 "Function available";
VAL_ 1553 SecondRowLeftSeatAutoDisplay 0 "No display" 1 "Seat Auto ON" 2 "Seat Auto OFF" 3 "Not used";
VAL_ 1553 SecondRowRightSeatAutoDisplay 0 "No display" 1 "Seat Auto ON" 2 "Seat Auto OFF" 3 "Not used";
VAL_ 1553 FrontLeftSeatAutoDisplay 0 "No display" 1 "Seat Auto ON" 2 "Seat Auto OFF" 3 "Not used";
VAL_ 1553 FrontRightSeatAutoDisplay 0 "No display" 1 "Seat Auto ON" 2 "Seat Auto OFF" 3 "Not used";
VAL_ 1553 ThirdRowLeftSeatAutoDisplay 0 "No display" 1 "Seat Auto ON" 2 "Seat Auto OFF" 3 "Not used";
VAL_ 1553 ThirdRowRightSeatDisplayStatus 0 "Function not available" 1 "Function available";
VAL_ 1553 ThirdRowLeftSeatDisplayStatus 0 "Function not available" 1 "Function available";
VAL_ 1553 ThirdRowRightSeatAutoDisplay 0 "No display" 1 "Seat Auto ON" 2 "Seat Auto OFF" 3 "Not used";
VAL_ 1553 SecondRowRightSeatDisplayStatus 0 "Function not available" 1 "Function available";
VAL_ 1553 SecondRowLeftSeatDisplayStatus 0 "Function not available" 1 "Function available";
VAL_ 1553 ClimCabinTempDisplayUnit 0 "display mode in °C" 1 "display mode in °F";
VAL_ 1553 ClimLastFuncModifiedByCustomer_v2 0 "No last action" 1 "Temperature" 2 "Rear Climate" 3 "Rear defrost" 4 "Clearness" 5 "Flow Distribution" 6 "Forced Recycling" 7 "OFF Button" 8 "Blower Level" 9 "Seat heating / ventilating" 10 "Auto" 11 "AC" 12 "Auto Recycling" 13 "Front defrost" 14 "Sync" 15 "Steering Wheel Heater";
VAL_ 1553 ClimLinkPrioRearSeatsAutoDisp 0 "No display" 1 "Level 1" 2 "Level 2" 3 "Level 3" 4 "Level 4" 5 "Level 5" 6 "OFF" 7 "Not used";
VAL_ 1553 ClimACmaxDisplay 0 "No display" 1 "AC max ON" 2 "AC max OFF" 3 "Not Used";
VAL_ 1557 AWDSettingRequest2 0 "No request" 1 "Mode 1" 2 "Mode 2" 3 "Mode 3" 4 "Mode 4" 5 "Mode 5" 6 "Mode 6" 7 "Reset Request";
VAL_ 1557 APAStart_SwitchRequest 0 "Switch released" 1 "Switch pushed";
VAL_ 1557 AirConditioningRequest 0 "No request" 1 "Mode HVAC 1 Normal" 2 "Mode HVAC 2 Eco" 3 "Unavailable";
VAL_ 1557 LongSwitchRequest_AVM 0 "Long Switch press not detected" 1 "Long Switch press detected";
VAL_ 1558 SwitchRequest_Trailer 0 "Switch released" 1 "Switch pushed";
VAL_ 1558 FAP_ScreenPressedDetected_2 0 "Not detected" 1 "Detected" 2 "Invalid" 3 "Not Used";
VAL_ 1558 ClimateDriverSetting 0 "Defog priority" 1 "Climate AutoMode" 2 "No Climate AutoMode" 3 "Not Used";
VAL_ 1558 APA_SwitchRequest 0 "Switch released" 1 "Switch pushed";
VAL_ 1558 LCDN_SensibilityRequest2 0 "No request" 1 "Low sensibility request" 2 "Middle sensibility request" 3 "High sensibility request" 4 "Not used" 5 "Not used" 6 "Not used" 7 "Reset request";
VAL_ 1558 LCDN_ActivationRequest2 0 "No request" 1 "LCDN activation request" 2 "LCDN deactivation request" 3 "Reset request";
VAL_ 1558 RPKStart_SwitchRequest 0 "Switch released" 1 "Switch pushed";
VAL_ 1558 ADL3_DisclaimerResponse 0 "No response" 1 "Accepted" 2 "Dismissed" 3 "Not used";
VAL_ 1558 UPA_UnpauseRequest2 0 "no Request" 1 "Unpause Request";
VAL_ 1558 HVBatChargeIncreaseDriverReq 0 "No request" 1 "Battery charging increase at low load requested";
VAL_ 1558 HVBatCoolingSaveDriverReq 0 "No request" 1 "Battery cooling save at low load requested";
VAL_ 1558 IVI_MegaStatus 0 "Not support" 1 "System deactivated" 2 "Customer deactivated" 3 "Operational" 4 "Reserved" 5 "Reserved" 6 "Reserved" 7 "Unavailable";
VAL_ 1558 AirSUSP_ControlPanelRequest 0 "Not Request" 1 "Access Height Request" 2 "High Height Request" 3 "Unavailable";
VAL_ 1564 ReacheableUSOCatDepartureTimeAl 0 "No Alert" 1 "Alert";
VAL_ 1565 HybridStartFailureAlert 0 "No alert" 1 "Unable to restart after pwr off";
VAL_ 1565 HEV_SystemFailureDisplay_v2 0 "No failure" 1 "Failure" 2 "Maintenance mode" 3 "Failure and Emergency alert";
VAL_ 1567 AudioAvailability_Amp 0 "audio available" 1 "audio unavailable";
VAL_ 1570 PWT_PowerLimitationAlert 0 "No alert" 1 "Alert";
VAL_ 1570 ModeEcoIncitationPrompt 0 "No Ecomode incitation request" 1 "Ecomode incitation request";
VAL_ 1570 ChargeTimeIndexReachibilityFbk 0 "No Index Data" 1 "Index Data 1" 2 "Index Data 2" 3 "Index Data 3" 4 "Index Data 4" 5 "Index Data 5" 6 "Index Data 6" 7 "Index Data 7" 8 "Index Data 8" 9 "Not used" 10 "Not used" 11 "Not used" 12 "Not used" 13 "Not used" 14 "Not used" 15 "Not used";
VAL_ 1570 ChargingAlert_v2 0 "No alert" 1 "Plug Unlocking" 2 "Unplug charging cable (EV and/or Spot Side)" 3 "Programmed charge interruption" 4 "Out of Park Position charge interruption" 5 "Start driving charge interruption" 6 "Charge failure" 7 "Prohibition battery rental" 8 "Battery full" 9 "Interruption due to Change profile renegotiation" 10 "Not used" 11 "Not used" 12 "Not used" 13 "Not used" 14 "Not used" 15 "Not used";
VAL_ 1570 ElectricalTractionAvailability 0 "EV traction available" 1 "EV traction soon not available" 2 "EV traction not available" 3 "Not used";
VAL_ 1570 CHGalertSpotCharge 0 "No Fault Type" 1 "Battery charge impossible with AC charge" 2 "Battery charge impossible with DC charge" 3 "Connexion Problem" 4 "Spot To Check" 5 "Power Supply Cutoff" 6 "Plug Signal lost" 7 "not used";
VAL_ 1570 ChargeAvailable 0 "Charge not available " 1 "Charge available";
VAL_ 1571 ProgrammedChargeStatus_HEVC 0 "No display (default value)" 1 "Always authorized charge" 2 "Delayed charge" 3 "Programmed charge by Calendar" 4 "Smartcharging" 5 "AC V2G" 6 "Not Used" 7 "Not Used";
VAL_ 1571 CauseOfSLOW_Lamp 0 "No alert" 1 "Overheat" 2 "Battery cold" 3 "Low SOC" 4 "Other" 5 "power suppression" 6 "speed down" 7 "Not used";
VAL_ 1571 Full_Charge_Request_Status 0 "No request" 1 "SOC is degraded" 2 "SOC is heavily degraded" 3 "Unavailable";
VAL_ 1573 OperatingTypeStatus_BLMS 0 "No request" 1 "Isolated charge" 2 "Non-isolated charge" 3 "External charge (battery outside vehicle)" 4 "Transitory" 5 "Driving" 6 "Init" 7 "DC Charging without RISOL" 8 "risolCheckMode" 9 "DC Charging with RISOL" 10 "V2G" 11 "V2L" 12 "Reserved" 13 "Reserved" 14 "Reserved" 15 "Reserved";
VAL_ 1577 LOB_PositionChangeStatus 0 "Unavailable" 1 "LOB position 1" 2 "LOB position 2" 3 "LOB position 3" 4 "LOB position 4" 5 "LOB position 5" 6 "LOB position 6" 7 "Position Change on going";
VAL_ 1577 LOB_ActivationCondition 0 "Feature absent" 1 "EV LOB feature allowed" 2 "EV LOB feature not allowed" 3 "Not Used";
VAL_ 1577 DriverMemoryRecallState 0 "No request" 1 "Seat execute failed" 2 "Seat execute forbid" 3 "Seat executing" 4 "Seat execute forbid for not in P mode" 5 "Stop for not in P mode" 6 "Not used" 7 "Not used";
VAL_ 1577 DriverMemoryPopUpReq 0 "No request" 1 "Display request";
VAL_ 1577 DriverMemorySetState 0 "No request" 1 "Memory set forbid";
VAL_ 1577 DrMassageExecuteState 0 "No request" 1 "Massage execute failed" 2 "Massage execute forbid" 3 "Massage execute forbid for Ready OFF" 4 "Massage stop for Ready OFF" 5 "Not used" 6 "Not used" 7 "Not used";
VAL_ 1577 DriverLifterMotorErrorState 0 "Normal" 1 "Motor position lost";
VAL_ 1577 DriverReclinerMotorErrorState 0 "Normal" 1 "Motor position lost" 2 "Anti-pinch" 3 "Not used";
VAL_ 1577 DriverSlideMotorErrorState 0 "Normal" 1 "Motor position lost" 2 "Anti-pinch" 3 "Not used";
VAL_ 1577 FrSeatMemoPopUpActivationState 0 "OFF" 1 "ON";
VAL_ 1577 DrMassagePopUpActivationState 0 "OFF" 1 "ON";
VAL_ 1578 Drowsy_AlertActivationState 0 "Unavailable" 1 "Activated" 2 "Deactivated" 3 "Not used";
VAL_ 1578 Face1_RegistrationState 0 "Not Registered" 1 "Registered";
VAL_ 1578 Face_ID 0 "initial valure" 1 "User1" 2 "User2" 3 "User3" 4 "User4" 5 "User5" 6 "Unregistered" 7 "Time Out" 8 "Error" 9 "Not used" 10 "Not used" 11 "Not used" 12 "Not used" 13 "Not used" 14 "Not used" 15 "Temporary Failure";
VAL_ 1578 Face5_RegistrationState 0 "Not Registered" 1 "Registered";
VAL_ 1578 Face4_RegistrationState 0 "Not Registered" 1 "Registered";
VAL_ 1578 Face3_RegistrationState 0 "Not Registered" 1 "Registered";
VAL_ 1578 Face2_RegistrationState 0 "Not Registered" 1 "Registered";
VAL_ 1578 FaceID_DeleteState 0 "Initial Value" 1 "Start/Deleting" 2 "Complete" 3 "Error";
VAL_ 1578 FaceID_RegistrationState 0 "Initial Value" 1 "Start/Registering" 2 "Complete" 3 "Stop (Cancel)" 4 "Time Out" 5 "Error" 6 "Not used" 7 "Imaging Failure";
VAL_ 1578 FaceID_RecognitionState 0 "Initial Value" 1 "Start/Recognizing" 2 "Complete" 3 "Stop (Cancel)" 4 "Time Out" 5 "Error" 6 "Not used" 7 "Imaging Failure";
VAL_ 1578 Distraction_LevelStatus 0 "Unavailable" 1 "Focussed" 2 "Distracted" 3 "Very distracted";
VAL_ 1578 Distraction_AlertActivationState 0 "Unavailable" 1 "Activated" 2 "Deactivated" 3 "Not used";
VAL_ 1578 DMC_ImageOutputStatus 0 "No video output with normally" 1 "Video output" 2 "No video output with failure" 3 "Not used";
VAL_ 1579 OverspeedAlertActivationStatus 0 "Deactivated" 1 "Activated" 2 "Not used" 3 "Unavailable";
VAL_ 1583 R_ANC_ModeStatus 0 "No Display" 1 "Mode1_Current seat mode all" 2 "Mode2_Current seat mode front" 3 "Mode3_Current seat mode rear" 4 "Mode4_Current seat mode front Left" 5 "Mode5_Current seat mode front Right" 6 "Not Used" 7 "Unavailable";
VAL_ 1583 R_ANC_ActivationStatus 0 "No Display" 1 "R-ANC status activation" 2 "R-ANC status deactivation" 3 "Unavailable";
VAL_ 1583 ANC_SeatFocusStatus 0 "Mode_seat1:ALL Mode" 1 "Mode_seat2:FR_LH Mode" 2 "Mode_seat3:FR_RH Mode" 3 "Mode_seat4:FR Mode" 4 "Mode_seat5:2nd_LH Mode" 5 "Mode_seat6:2nd_RH Mode" 6 "Mode_seat7: 2nd Mode" 7 "Mode_seat8:3rd_LH Mode" 8 "Mode_seat9:3rd_RH Mode" 9 "Mode_seat10:3rd_Mode" 10 "Not Used" 11 "Not Used" 12 "Not Used" 13 "Not Used" 14 "Not Used" 15 "Unavailable";
VAL_ 1583 ANC_ModeVariationStatus 0 "Mode_status1 AUTO Mode" 1 "Mode_status2 MANUAL Mode" 2 "Mode_status3 Not used" 3 "Mode_status4 Unavailable";
VAL_ 1583 ANC_ActivationStatus 0 "Mode_activation1 ANC ON" 1 "Mode_activation2 ANC OFF" 2 "Mode_activation3 Not used" 3 "Mode_activation4 Unavailable";
VAL_ 1585 HEV_ElecSysFailureDisplay 0 "No Alert" 1 "Alert";
VAL_ 1592 HVbatConditioningMode 0 "No request" 1 "Cooling by Chiller" 2 "Heating Recovery" 3 "Heating by PTC" 4 "Battery Range Boost" 5 "Cooling by Radiator" 6 "Heating Recovery without Battery" 7 "Not used" 8 "Not used" 9 "Not used" 10 "Not used" 11 "Not used" 12 "Not used" 13 "Not used" 14 "Not used" 15 "Not used";
VAL_ 1592 eAC_RevCapStatus 0 "Unavailable" 1 "Capped eAC rpm" 2 "Uncapped eAC rpm" 3 "Not used";
VAL_ 1592 IRStateDisplay 0 "No Display" 1 "IR ON" 2 "IR OFF" 3 "Not Used";
VAL_ 1595 TrailerGuidelineActivationRequest 0 "No Request" 1 "Activation Request" 2 "Deactivation Request" 3 "Reset Request";
VAL_ 1595 HUD_RotationPositionRequest2 0 "No Request" 1 "step 1" 2 "step 2" 3 "step 3" 4 "step 4" 5 "step 5" 6 "step 6" 7 "step 7" 8 "step 8" 9 "step 9" 10 "step 10" 11 "step 11" 12 "step 12" 13 "step 13" 14 "step 14" 15 "step 15" 16 "step 16" 17 "step 17" 18 "step 18" 19 "step 19" 20 "step 20" 21 "step 21" 22 "Reset Request" 23 "Not Used" 24 "Not Used" 25 "Not Used" 26 "Not Used" 27 "Not Used" 28 "Not Used" 29 "Not Used" 30 "Not Used" 31 "Not Used";
VAL_ 1595 AVM_GuidelinesActivationRequest2 0 "No Request" 1 "Static and Dynamic Guideline Deactivation Request" 2 "Static Guideline Activation Request" 3 "Dynamic Guideline Activation Request" 4 "Static and Dynamic Guideline Activation Request" 5 "Reset Request" 6 "Not Used" 7 "Not Used";
VAL_ 1595 OffsetValue_Request2 0 "No Request" 1 "-10" 2 "-9" 3 "-8" 4 "-7" 5 "-6" 6 "-5" 7 "-4" 8 "-3" 9 "-2" 10 "-1" 11 "0" 12 "1" 13 "2" 14 "3" 15 "4" 16 "5" 17 "6" 18 "7" 19 "8" 20 "9" 21 "10" 22 "Reset Request" 23 "Not used" 24 "Not used" 25 "Not used" 26 "Not used" 27 "Not used" 28 "Not used" 29 "Not used" 30 "Not used" 31 "Not used";
VAL_ 1595 AmbientLightingAreaADReq 0 "No Request" 1 "AmbientLighting AD requested" 2 "AmbientLighting AD not requested" 3 "Reset Request";
VAL_ 1595 VolumAlarmActivationRequest2 0 "No Request" 1 "Activation Request" 2 "Ask On Exit Request" 3 "Deactivation Once Request" 4 "Deactivation Request" 5 "Not used" 6 "Not used" 7 "Reset Request";
VAL_ 1595 ContextSpeed_ActivationRequest2 0 "No Request" 1 "OFF" 2 "Auto mode activation Request" 3 "Prompt mode activation Request" 4 "Reset Request" 5 "Not Used" 6 "Not Used" 7 "Not Used";
VAL_ 1595 OffsetActivation_Request2 0 "No request" 1 "Activation request" 2 "Deactivation  request" 3 "Reset request";
VAL_ 1595 FOTA_ProgRequest 0 "No Request" 1 "Timer Request" 2 "Cancel Request" 3 "Not Used";
VAL_ 1595 ContextRoad_ActivationRequest2 0 "No request" 1 "OFF" 2 "ON" 3 "Reset Request";
VAL_ 1595 Drowsy_AlertActivationRequest2 0 "No request" 1 "Drowsy alert activation" 2 "Drowsy alert deactivation" 3 "Reset request";
VAL_ 1595 RearViewRVC_CancelReason_RER 0 "No request" 1 "Reemission request";
VAL_ 1595 ZoomAutoActivationRequest2 0 "No Request" 1 "Zoom auto Deactivation Request" 2 "Zoom auto Activation Request" 3 "Reset Request";
VAL_ 1595 RearViewRVC_CancelReason 0 "No display" 1 "RearView Camera is blocked" 2 "RearView Camera permanent failure" 3 "Not Used";
VAL_ 1595 HVbatteryWarmingRequest 0 "No request" 1 "Battery warming OFF request" 2 "Battery warming ON request" 3 "Reset request";
VAL_ 1595 OSE_ActivationRequest2 0 "No request" 1 "Activation request" 2 "Deactivation request" 3 "Reset request";
VAL_ 1596 NextTurnProximityDetected 0 "No requested" 1 "Navigation picture requested";
VAL_ 1596 CurrentAudioState 0 "Normal listening" 1 "Update list signal" 2 "Mute audio" 3 "Not used";
VAL_ 1596 CurrentRadioFavorite 0 "No favorite radio selected" 1 "Favorite radio selected";
VAL_ 1596 CurrentPhoneStatus 0 "No call on going" 1 "Incoming call" 2 "Call on going" 3 "Automatic put on hold" 4 "Manual put on hold" 5 "Rejected call" 6 "Missed call" 7 "Call ended";
VAL_ 1596 CurrentAudioSource_v2 0 "All Off" 1 "Radio" 2 "CD DA" 3 "CD MP3" 4 "BT" 5 "SD" 6 "Aux" 7 "IPod" 8 "USB1" 9 "USB2" 10 "DVD" 11 "Blu-Ray" 12 "DTV" 13 "CarPlay" 14 "AndroidAuto" 15 "other sources";
VAL_ 1596 CurrentRadioBand_v2 0 "FM" 1 "AM" 2 "Digital radio" 3 "SXM" 4 "HD Radio" 5 "DAB" 6 "DRM" 7 "Not used";
VAL_ 1596 AutoDimmingRequest 0 "No request" 1 "AutoDimming Not activated" 2 "AutoDimming Activated" 3 "Reset request";
VAL_ 1596 CurrentRadioMode 0 "List" 1 "Manual" 2 "Preset" 3 "Not used";
VAL_ 1596 PnCactivationRequest_IVI 0 "No request" 1 "Activation request" 2 "Desactivation request" 3 "Not Used";
VAL_ 1596 TCS_DeactivationRequest2 0 "No request" 1 "TCS deactivation request" 2 "TCS activation request" 3 "Not used";
VAL_ 1596 HDC_ActivationRequest2 0 "HDC not requested" 1 "HDC requested" 2 "Reset requested" 3 "Unavailable";
VAL_ 1596 ClusterSkinRequest_v2 0 "No Request" 1 "Skin1" 2 "Skin2" 3 "Skin3" 4 "Skin4" 5 "Skin5" 6 "Skin6" 7 "Skin7" 8 "Skin8" 9 "Skin9" 10 "Skin10" 11 "Skin11" 12 "not used" 13 "not used" 14 "not used" 15 "Reset Request";
VAL_ 1596 SC_DepartureTimeWeekDay 0 "Monday" 1 "Tuesday" 2 "Wednesday" 3 "Thursday" 4 "Friday" 5 "Saturday" 6 "Sunday" 7 "unavailable";
VAL_ 1599 CTA_ActivationState 0 "Activated" 1 "Deactivated";
VAL_ 1614 HUD_TelSMSactivationRequest2 0 "No Request" 1 "Activation request" 2 "De-activation request" 3 "Reset request";
VAL_ 1614 HUD_ITactivationRequest2 0 "No Request" 1 "Activation request" 2 "De-activation request" 3 "Reset request";
VAL_ 1614 FunctionalLightingActivReq 0 "No Request" 1 "Functional Light activation requested" 2 "Functional Light deactivation requested" 3 "Functional Light auto requested";
VAL_ 1614 CASP_ActivationRequest2 0 "No Request" 1 "Activation request" 2 "Deactivation request" 3 "Reset request";
VAL_ 1614 RearLeftLumbarMovingReq_X_Axis 0 "No request" 1 "Forward ON" 2 "Backward ON" 3 "Not Used";
VAL_ 1614 RearLeftFrontHeightMovingReq 0 "No request" 1 "Upward ON" 2 "Downward ON" 3 "Not Used";
VAL_ 1614 R_ANC_ModeSwitchRequest 0 "No request" 1 "Mode1_Switching request all seat mode" 2 "Mode2_Switching request front seat mode" 3 "Mode3_Switching request rear seat mode" 4 "Mode4_Switching request front Left seat mode" 5 "Mode5_Switching request front Right seat mode" 6 "Not Used" 7 "Unavailable";
VAL_ 1614 R_ANC_ActivationRequest 0 "No R-ANC request" 1 "R-ANC activation request" 2 "R-ANC deactivation request" 3 "Unavailable";
VAL_ 1614 RearLeftMassageProgramReq 0 "No request" 1 "Program 1 requested" 2 "Program 2 requested" 3 "Program 3 requested" 4 "Program 4 requested" 5 "Program 5 requested" 6 "Program 6 requested" 7 "Program 7 requested" 8 "Program 8 requested" 9 "Program 9 requested" 10 "Program 10 requested" 11 "Program 11 requested" 12 "Program 12 requested" 13 "Program 13 requested" 14 "Program 14 requested" 15 "Not used";
VAL_ 1614 RearLeftMassageIntensityReq 0 "No request" 1 "Intensity 1 requested" 2 "Intensity 2 requested" 3 "Intensity 3 requested" 4 "Intensity 4 requested" 5 "Intensity 5 requested" 6 "Not used" 7 "Not used";
VAL_ 1614 RearLeftLumbarMovingReq_Z_Axis 0 "No request" 1 "Upward ON" 2 "Downward ON" 3 "Not Used";
VAL_ 1614 RearLeftReclinerMovingReq 0 "No request" 1 "Forward ON" 2 "Backward ON" 3 "Not Used";
VAL_ 1614 RearLeftOttomanMovingReq 0 "No request" 1 "Upward ON" 2 "Downward ON" 3 "Not Used";
VAL_ 1614 RearLeftMassageVelocityReq 0 "No request" 1 "Velocity 1 requested" 2 "Velocity 2 requested" 3 "Velocity 3 requested" 4 "Velocity 4 requested" 5 "Velocity 5 requested" 6 "Not Used" 7 "Not Used";
VAL_ 1614 RearRightLumbarMovingReq_X_Axis 0 "No request" 1 "Forward ON" 2 "Backward ON" 3 "Not Used";
VAL_ 1614 RearRightFrontHeightMovingReq 0 "No request" 1 "Upward ON" 2 "Downward ON" 3 "Not Used";
VAL_ 1614 RearLeftUpperbackrestMovingReq 0 "No request" 1 "Forward ON" 2 "Backward ON" 3 "Not Used";
VAL_ 1614 RearLeftSlideMovingReq 0 "No request" 1 "Forward ON" 2 "Backward ON" 3 "Not Used";
VAL_ 1614 RearRightMassageProgramReq 0 "No request" 1 "Program 1 requested" 2 "Program 2 requested" 3 "Program 3 requested" 4 "Program 4 requested" 5 "Program 5 requested" 6 "Program 6 requested" 7 "Program 7 requested" 8 "Program 8 requested" 9 "Program 9 requested" 10 "Program 10 requested" 11 "Program 11 requested" 12 "Program 12 requested" 13 "Program 13 requested" 14 "Program 14 requested" 15 "Not used";
VAL_ 1614 RearRightMassageIntensityReq 0 "No request" 1 "Intensity 1 requested" 2 "Intensity 2 requested" 3 "Intensity 3 requested" 4 "Intensity 4 requested" 5 "Intensity 5 requested" 6 "Not used" 7 "Not used";
VAL_ 1614 RearRightLumbarMovingReq_Z_Axis 0 "No request" 1 "Upward ON" 2 "Downward ON" 3 "Not Used";
VAL_ 1614 RearRightReclinerMovingReq 0 "No request" 1 "Forward ON" 2 "Backward ON" 3 "Not Used";
VAL_ 1614 RearRightOttomanMovingReq 0 "No request" 1 "Upward ON" 2 "Downward ON" 3 "Not Used";
VAL_ 1614 RearRightMassageVelocityReq 0 "No request" 1 "Velocity 1 requested" 2 "Velocity 2 requested" 3 "Velocity 3 requested" 4 "Velocity 4 requested" 5 "Velocity 5 requested" 6 "Not Used" 7 "Not Used";
VAL_ 1614 PairingMode 0 "Not Activated" 1 "Activated";
VAL_ 1614 V2G_ActivationRequest 0 "No request" 1 "V2G not activated" 2 "V2G activated" 3 "Reset request";
VAL_ 1614 RearRightUpperbackrestMovingReq 0 "No request" 1 "Forward ON" 2 "Backward ON" 3 "Not Used";
VAL_ 1614 RearRightSlideMovingReq 0 "No request" 1 "Forward ON" 2 "Backward ON" 3 "Not Used";
VAL_ 1616 APA_WarningDisplayRequest2 0 "no message" 1 "message1" 2 "message2" 3 "message3" 4 "message4" 5 "message5" 6 "message6" 7 "message7" 8 "message8" 9 "message9" 10 "message10" 11 "message11" 12 "message12" 13 "message13" 14 "message14" 15 "message15" 16 "message16" 17 "message17" 18 "message18" 19 "message19" 20 "message20" 21 "message21" 22 "message22" 23 "message23" 24 "message24" 25 "message25" 26 "message26" 27 "message27" 28 "message28" 29 "message29" 30 "message30" 31 "message31" 32 "message32" 33 "message33" 34 "message34" 35 "message35" 36 "message36" 37 "message37" 38 "message38" 39 "message39" 40 "message40" 41 "message41" 42 "message42" 43 "message43" 44 "message44" 45 "message45" 46 "message46" 47 "message47" 48 "message48" 49 "message49" 50 "message50" 51 "message51" 52 "message52" 53 "message53" 54 "message54" 55 "message55" 56 "message56" 57 "message57" 58 "message58" 59 "message59" 60 "message60" 61 "message61" 62 "message62" 63 "Not used";
VAL_ 1616 APA_ScanInfo2 0 "No display" 1 "Scan" 2 "SlotLeft" 3 "SlotRight" 4 "SlotLeftRight" 5 "Not used" 6 "Not used" 7 "Not used";
VAL_ 1625 EVSESelectedProtocol 0 "15118-20" 1 "15118-2" 2 "DIN" 3 "Not Used";
VAL_ 1625 PnC_Contract_Certificate_Status 0 "Not installed" 1 "installed" 2 "expired" 3 "errors";
VAL_ 1628 V2L_SystemStatusDisplay 0 "No display" 1 "ALL OFF" 2 "V2L Inside ON" 3 "V2L Outside ON" 4 "V2L Both ON" 5 "V2L Disabled with error" 6 "Not Used" 7 "Unavailable value";
VAL_ 1628 V2X_SystemFailureDisplay 0 "No display" 1 "V2X stopped because of low SOC" 2 "Low SOC for V2X" 3 "V2X System failure(Leakage current detection etc)" 4 "V2G aborted due to communication failure" 5 "V2G aborted due to technical failure" 6 "V2L stopped due to timeout" 7 "Unavailable value";
VAL_ 1628 V2L_PlugStatus 0 "No display" 1 "V2L plug available" 2 "V2L plug not available" 3 "Not Used";
VAL_ 1628 V2L_SystemAvailability 0 "No display" 1 "V2L Inside available" 2 "V2L Outside available" 3 "V2L Both available";
VAL_ 1629 FAP_ChangeViewRequest 0 "No request" 1 "Request";
VAL_ 1629 FAP_SwitchGrayOutRequest02 0 "Not requested" 1 "Requested";
VAL_ 1629 FAP_SwitchGrayOutRequest01 0 "Not requested" 1 "Requested";
VAL_ 1629 FAP_SwitchGrayOutRequest04 0 "Not requested" 1 "Requested";
VAL_ 1629 FAP_SwitchGrayOutRequest03 0 "Not requested" 1 "Requested";
VAL_ 1629 FAP_SwitchGrayOutRequest06 0 "Not requested" 1 "Requested";
VAL_ 1629 FAP_SwitchGrayOutRequest05 0 "Not requested" 1 "Requested";
VAL_ 1629 FAP_SwitchGrayOutRequest08 0 "Not requested" 1 "Requested";
VAL_ 1629 FAP_SwitchGrayOutRequest07 0 "Not requested" 1 "Requested";
VAL_ 1629 FAP_SwitchGrayOutRequest12 0 "Not requested" 1 "Requested";
VAL_ 1629 FAP_SwitchGrayOutRequest11 0 "Not requested" 1 "Requested";
VAL_ 1629 FAP_SwitchGrayOutRequest10 0 "Not requested" 1 "Requested";
VAL_ 1629 FAP_SwitchGrayOutRequest09 0 "Not requested" 1 "Requested";
VAL_ 1629 FAP_CameraIndicatorRequest 0 "No Displayed" 1 "Front View" 2 "Rear View" 3 "Rear Wide View" 4 "Front Wide View" 5 "Reserved" 6 "Reserved" 7 "Reserved";
VAL_ 1630 FAP_SoundLevelControl 0 "No request" 1 "Mute" 2 "Attenuate" 3 "Not used";
VAL_ 1630 FAP_SoundPatternRequest 0 "No sound selection" 1 "Sound pattern 1" 2 "Sound pattern 2" 3 "Sound pattern 3" 4 "Sound pattern 4" 5 "Sound pattern 5" 6 "Sound pattern 6" 7 "Sound pattern 7" 8 "Sound pattern 8" 9 "Sound pattern 9" 10 "Sound pattern 10" 11 "Sound pattern 11" 12 "Sound pattern 12" 13 "Sound pattern 13" 14 "Sound pattern 14" 15 "Sound pattern 15";
VAL_ 1630 FAP_SoundDirection 0 "No request" 1 "Front" 2 "Left front" 3 "Right front" 4 "Rear" 5 "Left rear" 6 "Right rear" 7 "Arround" 8 "Left" 9 "Right" 10 "Reserved" 11 "Reserved" 12 "Reserved" 13 "Reserved" 14 "Reserved" 15 "Reserved";
VAL_ 1630 FAP_Setting04 0 "No display" 1 "State 1 displayed" 2 "State 2 displayed" 3 "State 3 displayed";
VAL_ 1630 FAP_Setting03 0 "No display" 1 "State 1 displayed" 2 "State 2 displayed" 3 "State 3 displayed";
VAL_ 1630 FAP_Setting02 0 "No display" 1 "State 1 displayed" 2 "State 2 displayed" 3 "State 3 displayed";
VAL_ 1630 FAP_Setting01 0 "No display" 1 "State 1 displayed" 2 "State 2 displayed" 3 "State 3 displayed";
VAL_ 1630 FAP_Setting08 0 "No display" 1 "State 1 displayed" 2 "State 2 displayed" 3 "State 3 displayed";
VAL_ 1630 FAP_Setting07 0 "No display" 1 "State 1 displayed" 2 "State 2 displayed" 3 "State 3 displayed";
VAL_ 1630 FAP_Setting06 0 "No display" 1 "State 1 displayed" 2 "State 2 displayed" 3 "State 3 displayed";
VAL_ 1630 FAP_Setting05 0 "No display" 1 "State 1 displayed" 2 "State 2 displayed" 3 "State 3 displayed";
VAL_ 1630 FAP_PurposeSwitchAvailability 0 "Ignore purpose switch" 1 "Available purpose switch";
VAL_ 1630 FAP_ModeChangeRequest 0 "No request" 1 "Entry parking request" 2 "Exit parking request" 3 "Not used";
VAL_ 1630 FAP_Setting10 0 "No display" 1 "State 1 displayed" 2 "State 2 displayed" 3 "State 3 displayed";
VAL_ 1630 FAP_Setting09 0 "No display" 1 "State 1 displayed" 2 "State 2 displayed" 3 "State 3 displayed";
VAL_ 1634 FrontLeftBrakeTemperature 255 "not available";
VAL_ 1634 FrontRightBrakeTemperature 255 "not available";
VAL_ 1634 RearRightBrakeTemperature 255 "not available";
VAL_ 1634 RearLeftBrakeTemperature 255 "not available";
VAL_ 1635 V2X_HVBat_EnergyDurabilityWarn 0 "No warning / No Display" 1 "1st inhibition warning" 2 "2nd inhibition warning" 3 "Inhibition of V2G service";
VAL_ 1636 PBD_ActivationState 0 "No activation" 1 "Opening_movement_ongoing" 2 "Closing_movement_ongoing" 3 "Movement_delayed" 4 "Antipinch_movement_ongoing" 5 "Not Used" 6 "Not Used" 7 "Not Used";
VAL_ 1636 PBD_ResponseState 0 "No activation" 1 "ActivationRequest_Accepted" 2 "ActivationRequest_Completed" 3 "ActivationRequest_Rejected_Underqualified" 4 "Failure_detected" 5 "Obstacle_detected" 6 "Antipinch_detected" 7 "Not Used";
VAL_ 1636 PBD_AuthorizationState 0 "PBDNotAuthorized_AllMovementsInhibited" 1 "PBDAuthorized_AllMovementsAuthorized" 2 "PBDMainSwitchoff_LatchReleaseAuthorized" 3 "PBDFailure_LatchReleaseAuthorized" 4 "PBDFailure_AllMovementsInhibited" 5 "PBDAuthorized_ClosingMovementsAuthorized" 6 "Not Used" 7 "Not Used";
VAL_ 1637 SteeringSettingState_v2 0 "Mode EPS 1 Normal / Normal" 1 "Mode EPS 2 Normal / Confort" 2 "Mode EPS 3 Normal / Sport" 3 "Mode EPS 4" 4 "Mode EPS 5 Casual / Normal" 5 "Mode EPS 6 Casual / Confort" 6 "Mode EPS 7 Casual / Sport" 7 "Mode EPS 8" 8 "Mode EPS 9 Quick / Normal" 9 "Mode EPS 10 Quick / Confort" 10 "Mode EPS 11 Quick / Sport" 11 "Mode EPS 12" 12 "Mode EPS 13" 13 "Drive Mode" 14 "Not used" 15 "Not used";
VAL_ 1637 PowerTrainSettingState 0 "Mode 1 (Standard)" 1 "Mode 2 (Sport)" 2 "Mode 3 (Eco)" 3 "Mode 4 (Snow)" 4 "Mode 5" 5 "Mode 6" 6 "Mode 7" 7 "Mode 8" 8 "Mode 9" 9 "Mode 10" 10 "Mode 11" 11 "Mode 12" 12 "Mode 13" 13 "Mode 14" 14 "Not used" 15 "Not used";
VAL_ 1637 AWDSettingState 0 "Mode 1" 1 "Mode 2" 2 "Mode 3" 3 "Mode 4" 4 "Mode 5" 5 "Mode 6" 6 "Not used" 7 "Not used";
VAL_ 1637 SuspensionSettingState 0 "Mode VADA 1 (Normal)" 1 "Mode VADA 2 (Comfort)" 2 "Mode VADA 3 (Sport)" 3 "Mode VADA 4" 4 "Mode VADA 5" 5 "Mode VADA 6 (Race)" 6 "Not used" 7 "Not used";
VAL_ 1637 DriveModeState 0 "Mode 0=NORMAL/STANDARD/AUTO" 1 "Mode 1=ECO" 2 "Mode 2=SPORT/TARMAC" 3 "Mode 3=SPORT+/POWER" 4 "Mode 4=COMFORT" 5 "Mode 5=PERSONAL" 6 "Mode 6=SNOW" 7 "Mode 7" 8 "Mode 8=OFF-ROAD/GRAVEL" 9 "Mode 9=MUD/RUT" 10 "Mode 10=SAND" 11 "Mode 11=TOW" 12 "Mode 12=ALL ROAD/ROCK" 13 "Mode 13=EXTREM" 14 "Mode 14=PERFO" 15 "Mode 15=VITAMIN" 16 "Mode 16=RACE" 17 "Mode 17" 18 "Mode 18" 19 "Mode 19" 20 "Mode 20" 21 "Mode 21" 22 "Mode 22" 23 "Mode 23" 24 "Mode 24" 25 "Mode 25" 26 "Mode 26" 27 "Mode 27" 28 "Mode 28" 29 "Mode 29" 30 "Mode 30" 31 "Unavailable";
VAL_ 1637 VDCSettingState 0 "Mode1" 1 "Mode2" 2 "Mode3" 3 "Mode4" 4 "Mode5" 5 "Mode6" 6 "Mode7" 7 "Mode8" 8 "Mode9" 9 "Mode10" 10 "Mode11" 11 "Mode12" 12 "Mode13" 13 "Mode14" 14 "Not used" 15 "Not used";
VAL_ 1639 ChargingPlugStatus 0 "Not connected" 1 "Connected";
VAL_ 1639 AllRouteSegmentsRequest 0 "No Request" 1 "Send all route segment request";
VAL_ 1640 SCdurabilityInhibition 0 "No smartcharging inhibition" 1 "Smartcharging inhibited";
VAL_ 1645 AEB_FCWactivationState2 0 "AEB OFF / FCW OFF" 1 "AEB OFF / FCW ON" 2 "Not used" 3 "AEB ON / FCW ON";
VAL_ 1645 AEB_CyclistAlertRequest2 0 "No AEB cyclist alert" 1 "AEB cyclist alert";
VAL_ 1645 AEB_PedestrianAlertRequest2 0 "No AEB PEDESTRIAN alert" 1 "AEB PEDESTRIAN alert";
VAL_ 1645 AEB_VehicleAlertRequest2 0 "No AEB vehicle alert" 1 "AEB vehicle Approach alert" 2 "AEB vehicle Collision alert" 3 "AEB vehicle Alert reminder";
VAL_ 1645 AEB_StatusDisplay2_v2 0 "No display" 1 "AEB Off" 2 "operation" 3 "Not operation" 4 "Temporary failure" 5 "Permanent failure" 6 "Initial" 7 "Not Used";
VAL_ 1645 DW_ActivationState_TM 0 "DW deactivated" 1 "DW activated";
VAL_ 1645 FCW_SensibilityState 0 "Unavailable" 1 "Early" 2 "Standard" 3 "Late";
VAL_ 1645 AEB_JuncAssistActivationState 0 "Unavailable" 1 "Activated" 2 "Deactivated" 3 "Not used";
VAL_ 1648 eHBox_USBInstall_InsertedRequest 0 "No Request" 1 "Request";
VAL_ 1648 eHBox_USB_WritabilityRequest 0 "No Request" 1 "No writing request" 2 "Writing request" 3 "Not used";
VAL_ 1648 eHBox_USBSave_InsertedRequest 0 "No Request" 1 "Request";
VAL_ 1648 eHBox_Current_Map_versionRequest 0 "No request" 1 "Request";
VAL_ 1648 eHBox_USB_MapInstallRequest 0 "No Request" 1 "No update request" 2 "Update request" 3 "Not used";
VAL_ 1650 ConnectionData_DVR_WiFi 0 "Table Value414235";
VAL_ 1650 DVR_Incident_state 0 "Unavailable" 1 "Incident Recording start" 2 "Incident Recording end" 3 "Not used";
VAL_ 1650 DataLength_DVR_WiFi 0 "0" 1 "1" 2 "2" 3 "3" 4 "4" 5 "5" 6 "6" 7 "7" 8 "8" 9 "9" 10 "10" 11 "11" 12 "12" 13 "13" 14 "14" 15 "15" 16 "16" 17 "17" 18 "18" 19 "19" 20 "20" 21 "21" 22 "22" 23 "23" 24 "24" 25 "25" 26 "26" 27 "27" 28 "28" 29 "29" 30 "30" 31 "31" 32 "32" 33 "Not used" 34 "Not used" 35 "Not used" 36 "Not used" 37 "Not used" 38 "Not used" 39 "Not used" 40 "Not used" 41 "Not used" 42 "Not used" 43 "Not used" 44 "Not used" 45 "Not used" 46 "Not used" 47 "Not used" 48 "Not used" 49 "Not used" 50 "Not used" 51 "Not used" 52 "Not used" 53 "Not used" 54 "Not used" 55 "Not used" 56 "Not used" 57 "Not used" 58 "Not used" 59 "Not used" 60 "Not used" 61 "Not used" 62 "Not used" 63 "Invalid";
VAL_ 1650 eMMCStatus_v2 0 "EMMC normal" 1 "EMMC onlyRead" 2 "EMMC error" 3 "Unavailable value";
VAL_ 1650 TransportContent_DVR_WiFi 0 "SSID" 1 "Password" 2 "Reserved" 3 "Invalid value";
VAL_ 1650 DataIndex_DVR_WiFi 0 "0" 1 "1" 2 "2" 3 "3" 4 "4" 5 "5" 6 "Reserved" 7 "Reserved" 8 "Reserved" 9 "Reserved" 10 "Reserved" 11 "Reserved" 12 "Reserved" 13 "Reserved" 14 "Reserved" 15 "Invalid";
VAL_ 1655 EVchargingProfileStatus 0 "No Schedule transmitted" 1 "Schedule #1 transmission in progress" 2 "Schedule #2 transmission in progress" 3 "Schedule #3 transmission in progress" 4 "Transmission is finished" 5 "Error" 6 "Not used" 7 "Not used";
VAL_ 1658 FAP_ScreenPressDetected 0 "No detected" 1 "Detected" 2 "Invalid" 3 "Not used";
VAL_ 1658 FAP_SwitchLongPressDetected 0 "Not detected" 1 "detected";
VAL_ 1658 FAP_ActivationRequest 0 "Not Requested" 1 "Requested";
VAL_ 1658 FAP_HMIavailability 0 "Under Preparation" 1 "Complete Display Preparation and Start Sound Preparation" 2 "Complete Sound Preparation and Start Display Preparation" 3 "All Preparation complete";
VAL_ 1658 FAP_VoiceStatus 0 "No voice" 1 "Voice is played" 2 "Voice can't be playes" 3 "Not used";
VAL_ 1659 UserIdentification_IKeyLink 0 "No request" 1 "Key No. 1" 2 "Key No. 2" 3 "Key No. 3" 4 "Key No. 4" 5 "Not used" 6 "Not used" 7 "Not used";
VAL_ 1660 RearSeatsLockStatus 0 "Unavailable" 1 "Thermal comfort lockdisplay" 2 "Thermal comfort unlock display" 3 "Not Used";
VAL_ 1660 SecondRowRightSeatStatus 0 "Unvailable" 1 "OFF display" 2 "Heater Low display" 3 "Heater Middle display" 4 "Heater High display" 5 "Ventilated Low display" 6 "Ventilated Middle display" 7 "Ventilated High display";
VAL_ 1660 SecondRowLeftSeatStatus 0 "Unvailable" 1 "OFF display" 2 "Heater Low display" 3 "Heater Middle display" 4 "Heater High display" 5 "Ventilated Low display" 6 "Ventilated Middle display" 7 "Ventilated High display";
VAL_ 1660 ClimAutoRecyclingDisplayStatus 0 "Function not available" 1 "Function available";
VAL_ 1660 ClimACDisplayStatus 0 "Function not available" 1 "Function available";
VAL_ 1660 ThirdRowRightSeatStatus 0 "Unvailable" 1 "OFF display" 2 "Heater Low display" 3 "Heater Middle display" 4 "Heater High display" 5 "Ventilated Low display" 6 "Ventilated Middle display" 7 "Ventilated High display";
VAL_ 1660 ThirdRowLeftSeatStatus 0 "Unvailable" 1 "OFF display" 2 "Heater Low display" 3 "Heater Middle display" 4 "Heater High display" 5 "Ventilated Low display" 6 "Ventilated Middle display" 7 "Ventilated High display";
VAL_ 1660 ClimEVHeaterDisplayStatus 0 "Function not available" 1 "Function available";
VAL_ 1660 ClimDriverZoneDisplayStatus 0 "Function not available" 1 "Function available";
VAL_ 1660 ClimDriverZoneDisplay 0 "No display" 1 "Driver zone ON" 2 "Driver zone OFF" 3 "Not used";
VAL_ 1660 ClimClearnessDisplayStatus 0 "Function not available" 1 "Function available";
VAL_ 1660 ClimBlowingLevelDisplayStatus 0 "Function not available" 1 "Function available";
VAL_ 1660 ClimBlowingAutoDisplay 0 "No display" 1 "Blowing auto ON" 2 "Blowing auto OFF" 3 "Not used";
VAL_ 1660 ClimHumidityDisplayStatus 0 "Function not available" 1 "Function available";
VAL_ 1660 ClimForestSettingDisplayStatus 0 "Function not available" 1 "Function available";
VAL_ 1660 ClimForestDisplayStatus 0 "Function not available" 1 "Function available";
VAL_ 1660 ClimForestDisplay 0 "No display" 1 "Forest ON" 2 "Forest OFF" 3 "Not used";
VAL_ 1660 ClimFlowDistrDisplayStatus 0 "Function not available" 1 "Function available";
VAL_ 1660 ClimEVHeaterDisplay 0 "No display" 1 "EV heater ON" 2 "EV heater OFF" 3 "Not Used";
VAL_ 1660 ClimLinkDefrostAndClearnesDisp 0 "No display" 1 "HFS and Rear def link to Clearness ON" 2 "HFS and Rear def link to Clearness OFF" 3 "Not used";
VAL_ 1660 ClimHumiditySensorSensitivDisp 0 "No display" 1 "Level 1" 2 "Level 2" 3 "Level 3" 4 "Level 4" 5 "Level 5" 6 "OFF" 7 "not used";
VAL_ 1660 ClimHumidityDisplay 0 "No display" 1 "Humidity OFF" 2 "Humidity Low" 3 "Humidity Mid" 4 "Humidity High" 5 "Not used" 6 "Not used" 7 "Not used";
VAL_ 1660 ClimRightAutoDisplay 0 "No display" 1 "Auto ON" 2 "Auto OFF" 3 "Not Used";
VAL_ 1660 ClimOFFModeDisplayStatus 0 "Function not available" 1 "Function available";
VAL_ 1660 ClimLinkMaxFanSpeedAutoDisplay 0 "No display" 1 "Level 1" 2 "Level 2" 3 "Level 3" 4 "Level 4" 5 "Level 5" 6 "OFF" 7 "not used";
VAL_ 1660 ClimLinkFreshRecyAndAutoDisplay 0 "No display" 1 "Air intake link to Auto ON" 2 "Air intake link to Auto OFF" 3 "Not used";
VAL_ 1660 ClimRightFlowDistrDisplayStatus 0 "Function not available" 1 "Function available";
VAL_ 1660 ClimRightBlowingLevelDispStatus 0 "Function not available" 1 "Function available";
VAL_ 1660 ClimRightBlowingLevelDisplay 0 "No display" 1 "Level 1" 2 "Level 2" 3 "Level 3" 4 "Level 4" 5 "Level 5" 6 "Level 6" 7 "Level 7" 8 "Level 8" 9 "Level 9" 10 "Level 10" 11 "Level 11" 12 "Level 12" 13 "Level 13" 14 "Level 14" 15 "Blower OFF";
VAL_ 1660 ClimRightBlowingAutoDisplay 0 "No display" 1 "Blowing auto ON" 2 "Blowing auto OFF" 3 "Not used";
VAL_ 1660 ClimTempDisplayStatus 0 "Function not available" 1 "Function available";
VAL_ 1660 ClimSyncDisplayStatus 0 "Function not available" 1 "Function available";
VAL_ 1660 ClimSyncDisplay 0 "No display" 1 "Sync mode ON" 2 "Sync mode OFF" 3 "Not Used";
VAL_ 1660 ClimRightTempDisplayStatus 0 "Function not available" 1 "Function available";
VAL_ 1660 ClimRightFlowDistrDisplay 0 "No display" 1 "Feet" 2 "Vent" 3 "Feet + Vent" 4 "Defrost" 5 "Defrost + Feet" 6 "Defrost + Vent" 7 "Defrost + Vent + Feet";
VAL_ 1661 AVM_ActivationRequest 0 "No request" 1 "Request1" 2 "Request2" 3 "Request3" 4 "Request4" 5 "Request5" 6 "Request6" 7 "Request7" 8 "Request8" 9 "Request9" 10 "Request10" 11 "Request11" 12 "Request12" 13 "Request13" 14 "Request14" 15 "Request15";
VAL_ 1661 DiffLock_SwitchSignal_IVI 0 "Not used" 1 "ON" 2 "OFF" 3 "Invalid";
VAL_ 1661 AWD_SwitchSignal_IVI 0 "No request" 1 "AUTO" 2 "4H" 3 "4L" 4 "Reset request" 5 "Not Used" 6 "Not Used" 7 "Not Used";
VAL_ 1662 PassengerSeatMemoRecall 0 "No recall" 1 "Recall of memorization 1" 2 "Recall of memorization 2" 3 "Recall of memorization 3" 4 "Recall of memorization 4" 5 "Recall of memorization 5" 6 "Recall of memorization 6" 7 "Not used";
VAL_ 1662 PassengerSeatMemoRequest 0 "No request of memorization" 1 "Request of memorization 1" 2 "Request of memorization 2" 3 "Request of memorization 3" 4 "Request of memorization 4" 5 "Request of memorization 5" 6 "Request of memorization 6" 7 "Reset Request";
VAL_ 1662 SecondRowRightSeatRequest 0 "No request" 1 "OFF request" 2 "Heater Low request" 3 "Heater Middle request" 4 "Heater High request" 5 "Ventilated Low request" 6 "Ventilated Middle request" 7 "Ventilated High request" 8 "Reset request" 9 "Not Used" 10 "Not Used" 11 "Not Used" 12 "Not Used" 13 "Not Used" 14 "Not Used" 15 "Not Used";
VAL_ 1662 SecondRowLeftSeatRequest 0 "No request" 1 "OFF request" 2 "Heater Low request" 3 "Heater Middle request" 4 "Heater High request" 5 "Ventilated Low request" 6 "Ventilated Middle request" 7 "Ventilated High request" 8 "Reset request" 9 "Not Used" 10 "Not Used" 11 "Not Used" 12 "Not Used" 13 "Not Used" 14 "Not Used" 15 "Not Used";
VAL_ 1662 ThirdRowRightSeatRequest 0 "No request" 1 "OFF request" 2 "Heater Low request" 3 "Heater Middle request" 4 "Heater High request" 5 "Ventilated Low request" 6 "Ventilated Middle request" 7 "Ventilated High request" 8 "Reset request" 9 "Not Used" 10 "Not Used" 11 "Not Used" 12 "Not Used" 13 "Not Used" 14 "Not Used" 15 "Not Used";
VAL_ 1662 ThirdRowLeftSeatRequest 0 "No request" 1 "OFF request" 2 "Heater Low request" 3 "Heater Middle request" 4 "Heater High request" 5 "Ventilated Low request" 6 "Ventilated Middle request" 7 "Ventilated High request" 8 "Reset request" 9 "Not Used" 10 "Not Used" 11 "Not Used" 12 "Not Used" 13 "Not Used" 14 "Not Used" 15 "Not Used";
VAL_ 1662 RearSeatsLockRequest 0 "No request" 1 "Thermal comfort lock request" 2 "Thermal comfort unlock request" 3 "Reset request";
VAL_ 1662 ClimHumiditySensorSensitivitReq 0 "No request" 1 "Level 1" 2 "Level 2" 3 "Level 3" 4 "Level 4" 5 "Level 5" 6 "OFF request" 7 "Reset request";
VAL_ 1662 TimeFormatDisplay 0 "24h format" 1 "12h format";
VAL_ 1662 ClimFPrightBlowingRequest 0 "No Request" 1 "Level 1" 2 "Level 2" 3 "Level 3" 4 "Level 4" 5 "Level 5" 6 "Level 6" 7 "Level 7" 8 "Level 8" 9 "Level 9" 10 "Level 10" 11 "Level 11" 12 "Level 12" 13 "Level 13" 14 "Level 14" 15 "Blower OFF";
VAL_ 1662 ClimLinkPriorityFLSeatAutoReq 0 "No request" 1 "Level 1" 2 "Level 2" 3 "Level 3" 4 "Level 4" 5 "Level 5" 6 "OFF request" 7 "Reset request";
VAL_ 1662 ClimLinkMaxFanSpeedAutoReq 0 "No request" 1 "Level 1" 2 "Level 2" 3 "Level 3" 4 "Level 4" 5 "Level 5" 6 "OFF request" 7 "Reset request";
VAL_ 1662 ClimLinkPriorityFRSeatAutoReq 0 "No request" 1 "Level 1" 2 "Level 2" 3 "Level 3" 4 "Level 4" 5 "Level 5" 6 "OFF request" 7 "Reset request";
VAL_ 1666 Distract_AlertStatus2 0 "No Alert" 1 "Warning Alert" 2 "Danger Alert" 3 "Warning AlertRER";
VAL_ 1666 Cluster_DisplayContentsChangeReq 0 "No Request" 1 "Contents 1 request" 2 "Contents 2 request" 3 "Contents 3 request" 4 "Contents 4 request" 5 "Contents 5 request" 6 "Contents 6 request" 7 "Contents 7 request" 8 "Contents 8 request" 9 "Contents 9 request" 10 "Contents 10 request" 11 "Contents 11 request" 12 "Contents 12 request" 13 "Contents 13 request" 14 "Contents 14 request" 15 "Contents 15 request" 16 "Contents 16 request" 17 "Contents 17 request" 18 "Contents 18 request" 19 "Contents 19 request" 20 "Contents 20 request" 21 "Contents 21 request" 22 "Contents 22 request" 23 "Contents 23 request" 24 "Contents 24 request" 25 "Contents 25 request" 26 "Contents 26 request" 27 "Contents 27 request" 28 "Contents 28 request" 29 "Contents 29 request" 30 "Contents 30 request" 31 "Contents 31 request" 32 "Contents 32 request" 33 "Contents 33 request" 34 "Contents 34 request" 35 "Contents 35 request" 36 "Contents 36 request" 37 "Contents 37 request" 38 "Contents 38 request" 39 "Contents 39 request" 40 "Contents 40 request" 41 "Contents 41 request" 42 "Contents 42 request" 43 "Contents 43 request" 44 "Contents 44 request" 45 "Contents 45 request" 46 "Contents 46 request" 47 "Contents 47 request" 48 "Contents 48 request" 49 "Contents 49 request" 50 "Contents 50 request" 51 "Contents 51 request" 52 "Contents 52 request" 53 "Contents 53 request" 54 "Contents 54 request" 55 "Contents 55 request" 56 "Contents 56 request" 57 "Contents 57 request" 58 "Contents 58 request" 59 "Contents 59 request" 60 "Contents 60 request" 61 "Contents 61 request" 62 "Contents 62 request" 63 "Contents 63 request";
VAL_ 1666 DynamicBackgroundState 0 "No Request" 1 "State1" 2 "State2" 3 "State3" 4 "State4" 5 "State5" 6 "State6" 7 "State7" 8 "State8" 9 "State9" 10 "State10" 11 "State11" 12 "State12" 13 "State13" 14 "State14" 15 "State15" 16 "State16" 17 "Not used" 18 "Not used" 19 "Not used" 20 "Not used" 21 "Not used" 22 "Not used" 23 "Not used" 24 "Not used" 25 "Not used" 26 "Not used" 27 "Not used" 28 "Not used" 29 "Not used" 30 "Not used" 31 "Not used";
VAL_ 1666 Cluster_DisplayViewModeChangeReq 0 "No Request" 1 "View Mode1 request" 2 "View Mode2 request" 3 "View Mode3 request" 4 "View Mode4 request" 5 "View Mode5 request" 6 "View Mode6 request" 7 "View Mode7 request";
VAL_ 1666 V2X_SOClimitationLevelRequest2 126 "No request" 127 "Reset request";
VAL_ 1666 DynamicBackgroundProgress 0 "0" 1 "10" 2 "20" 3 "30" 4 "40" 5 "50" 6 "60" 7 "70" 8 "80" 9 "90" 10 "100" 11 "Not used" 12 "Not used" 13 "Not used" 14 "Not used" 15 "Not used";
VAL_ 1666 SSickness_AlertStatus2 0 "No Alert" 1 "Danger Alert" 2 "Reserved" 3 "Reserved";
VAL_ 1666 Fatigue_AlertStatus2 0 "No Alert" 1 "Warning Alert" 2 "Danger Alert" 3 "Warning AlertRER";
VAL_ 1666 DriverEyesOnRoad2 0 "Eyes off road" 1 "Eyes on road" 2 "Eyes on driving related area" 3 "Unavailable value";
VAL_ 1666 Distraction_LevelStatus2 0 "Unavailable" 1 "Focussed" 2 "Distracted" 3 "Very distracted";
VAL_ 1666 Fatigue_LevelStatus2 0 "Unavailable" 1 "Awake" 2 "Drowsy" 3 "Micro-sleep" 4 "Sleep" 5 "Not Used" 6 "Not Used" 7 "Not Used";
VAL_ 1666 DMS_CameraCancelReason2 0 "No display" 1 "Camera temporary OBSTRUCTION" 2 "Camera temporary DIRTY" 3 "Camera temporary FACE MASKED" 4 "Camera temporary EYES MASKED" 5 "LEDs UNAVAILABLE" 6 "Camera OVER HEAT" 7 "DMS Permanent failure";
VAL_ 1666 SSickness_State2 0 "No state" 1 "Conscious" 2 "Unconscious" 3 "Unavailable";
VAL_ 1666 ANC_ModeVariationRequest 0 "Mode_status1 AUTO Mode" 1 "Mode_status2 MANUAL Mode" 2 "Mode_status3 Not used" 3 "Mode_status4 Unavailable";
VAL_ 1666 ANC_ActivationRequest 0 "Mode_activation1 ANC ON" 1 "Mode_activation2 ANC OFF" 2 "Mode_activation3 Not used" 3 "Mode_activation4 Unavailable";
VAL_ 1666 NapModeRequest 0 "No request" 1 "Nap Mode OFF" 2 "Nap Mode ON" 3 "Not used";
VAL_ 1666 RelaxModeRequest 0 "No request" 1 "Relax Mode OFF" 2 "Relax Mode ON" 3 "Not used";
VAL_ 1666 FrSeatMemoPopUpActivationReq 0 "Deactivation request" 1 "Activation request";
VAL_ 1666 PsMassagePopUpActivationReq 0 "Deactivation request" 1 "Activation request";
VAL_ 1666 DrMassagePopUpActivationReq 0 "Deactivation request" 1 "Activation request";
VAL_ 1666 ANC_SeatFocusRequest 0 "Mode_seat1:ALL Mode" 1 "Mode_seat2:FR_LH Mode" 2 "Mode_seat3:FR_RH Mode" 3 "Mode_seat4:FR Mode" 4 "Mode_seat5:2nd_LH Mode" 5 "Mode_seat6:2nd_RH Mode" 6 "Mode_seat7: 2nd Mode" 7 "Mode_seat8:3rd_LH Mode" 8 "Mode_seat9:3rd_RH Mode" 9 "Mode_seat10:3rd_Mode" 10 "Not Used" 11 "Not Used" 12 "Not Used" 13 "Not Used" 14 "Not Used" 15 "Unavailable";
VAL_ 1667 PSD_L_AuthorizationState 0 "PSDNotAuthorized_AllMovementsInhibited" 1 "PSDAuthorized_AllMovementsAuthorized" 2 "PSDFailure_AllMovementsInhibited" 3 "Not Used";
VAL_ 1667 PSD_L_ResponseState 0 "No activation" 1 "ActivationRequest_Accepted" 2 "ActivationRequest_Completed" 3 "ActivationRequest_Rejected_Underqualified" 4 "Failure_detected" 5 "Antipinch_detected" 6 "Not Used" 7 "Not Used";
VAL_ 1667 PSD_L_ActivationState 0 "No activation" 1 "Opening_movement_ongoing" 2 "Closing_movement_ongoing" 3 "Movement_delayed" 4 "Antipinch_movement_ongoing" 5 "Not Used" 6 "Not Used" 7 "Not Used";
VAL_ 1670 RearSignatureRequest 0 "No Request" 1 "Activation" 2 "Deactivation" 3 "Reset Requested";
VAL_ 1670 AnimationPatternRequest 0 "No Request" 1 "Pattern1" 2 "Pattern2" 3 "Pattern3" 4 "Pattern4" 5 "Pattern5" 6 "Pattern6" 7 "Pattern7" 8 "Pattern8" 9 "Pattern9" 10 "Pattern10" 11 "Pattern11" 12 "Pattern12" 13 "Pattern13" 14 "Pattern14" 15 "Reset requested";
VAL_ 1670 InternalLightingIntensityReq2 0 "No Request" 1 "Level 0_OFF requested" 2 "Level 1 requested" 3 "Level 2 requested" 4 "Level 3 requested" 5 "Level 4 requested" 6 "Level 5 requested" 7 "Reset requested";
VAL_ 1670 AmbiLightADLINKTypeReq 0 "No Request" 1 "Request Type1" 2 "Request Type2" 3 "Request Type3";
VAL_ 1670 DMC_SensitivityRequest2 0 "No request" 1 "Low sensitivity request" 2 "Middle sensitivity request" 3 "High sensitivity request" 4 "Not used" 5 "Not used" 6 "Not used" 7 "Reset request";
VAL_ 1670 Distraction_AlertActivationReq2 0 "No request" 1 "Distraction alert activation" 2 "Distraction alert deactivation" 3 "Reset request";
VAL_ 1670 AmbientlightADColorReq 0 "No request" 1 "Color 1" 2 "Color 2" 3 "Color 3" 4 "Color 4" 5 "Color 5" 6 "Color 6" 7 "Color 7" 8 "Color 8" 9 "Color 9" 10 "Color 10" 11 "Color 11" 12 "Color 12" 13 "Color 13" 14 "Color 14" 15 "Color 15" 16 "Color 16" 17 "Color 17" 18 "Color 18" 19 "Color 19" 20 "Color 20" 21 "Color 21" 22 "Color 22" 23 "Color 23" 24 "Color 24" 25 "Color 25" 26 "Color 26" 27 "Color 27" 28 "Color 28" 29 "Color 29" 30 "Color 30" 31 "Color 31" 32 "Color 32" 33 "Color 33" 34 "Color 34" 35 "Color 35" 36 "Color 36" 37 "Color 37" 38 "Color 38" 39 "Color 39" 40 "Color 40" 41 "Color 41" 42 "Color 42" 43 "Color 43" 44 "Color 44" 45 "Color 45" 46 "Color 46" 47 "Color 47" 48 "Color 48" 49 "Color 49" 50 "Color 50" 51 "Color 51" 52 "Color 52" 53 "Color 53" 54 "Color 54" 55 "Color 55" 56 "Color 56" 57 "Color 57" 58 "Color 58" 59 "Color 59" 60 "Color 60" 61 "Color 61" 62 "Color 62" 63 "Color 63" 64 "Color 64" 65 "Color 65" 66 "Color 66" 67 "Color 67" 68 "Color 68" 69 "Color 69" 70 "Color 70" 71 "Color 71" 72 "Color 72" 73 "Color 73" 74 "Color 74" 75 "Color 75" 76 "Color 76" 77 "Color 77" 78 "Color 78" 79 "Color 79" 80 "Color 80" 81 "Color 81" 82 "Color 82" 83 "Color 83" 84 "Color 84" 85 "Color 85" 86 "Color 86" 87 "Color 87" 88 "Color 88" 89 "Color 89" 90 "Color 90" 91 "Color 91" 92 "Color 92" 93 "Color 93" 94 "Color 94" 95 "Color 95" 96 "Color 96" 97 "Color 97" 98 "Color 98" 99 "Color 99" 100 "Color 100" 101 "Color 101" 102 "Color 102" 103 "Color 103" 104 "Color 104" 105 "Color 105" 106 "Color 106" 107 "Color 107" 108 "Color 108" 109 "Color 109" 110 "Color 110" 111 "Color 111" 112 "Color 112" 113 "Color 113" 114 "Color 114" 115 "Color 115" 116 "Color 116" 117 "Color 117" 118 "Color 118" 119 "Color 119" 120 "Color 120" 121 "Color 121" 122 "Color 122" 123 "Color 123" 124 "Color 124" 125 "Color 125" 126 "Color 126" 127 "Reset Request";
VAL_ 1670 LKA_DL_ActivationRequest2 0 "No request" 1 "Activation" 2 "Deactivation" 3 "Reset request";
VAL_ 1670 ELKA_OTOC_ActivationRequest2 0 "No request" 1 "Activation" 2 "Deactivation" 3 "Reset request";
VAL_ 1670 ELKS_ActivationRequest2 0 "No request" 1 "Activation" 2 "Deactivation" 3 "Reset request";
VAL_ 1670 LOB_PositionSaveRequest 0 "No request" 1 "SAVE LOB position 1" 2 "SAVE LOB position 2" 3 "SAVE LOB position 3" 4 "SAVE LOB position 4" 5 "SAVE LOB position 5" 6 "SAVE LOB position 6" 7 "Not Used";
VAL_ 1670 LOB_PositionRecallRequest 0 "No request" 1 "RECALL LOB position 1" 2 "RECALL LOB position 2" 3 "RECALL LOB position 3" 4 "RECALL LOB position 4" 5 "RECALL LOB position 5" 6 "RECALL LOB position 6" 7 "Reset request";
VAL_ 1670 OverspeedAlertActivationRequest2 0 "No request" 1 "Overspeed alert activation request" 2 "Overspeed alert deactivation request" 3 "Reset request";
VAL_ 1670 Remote_Start_Stop_V2L 0 "No Request" 1 "Stop all V2L sockets" 2 "Start all V2L sockets" 3 "Not Used" 4 "Not Used" 5 "Not Used" 6 "Not Used" 7 "Not Used";
VAL_ 1670 AEB_JuncAssistActivationRequest2 0 "No request" 1 "Activation" 2 "Deactivation" 3 "Reset request";
VAL_ 1670 VR_ESSURequest 0 "No Request" 1 "Clear All Roof" 2 "Clear Front Area Roof" 3 "Clear Rear Area Roof" 4 "Opacify All Roof" 5 "Opacify Front Area Roof" 6 "Opacify Rear Area Roof" 7 "Not Used";
VAL_ 1671 AnimationPatternState 0 "Not used" 1 "Pattern1" 2 "Pattern2" 3 "Pattern3" 4 "Pattern4" 5 "Pattern5" 6 "Pattern6" 7 "Pattern7" 8 "Pattern8" 9 "Pattern9" 10 "Pattern10" 11 "Pattern11" 12 "Pattern12" 13 "Pattern13" 14 "Pattern14" 15 "Unavailable";
VAL_ 1675 Fatigue_LevelStatus 0 "Unavailable" 1 "Awake" 2 "Drowsy" 3 "Micro-sleep" 4 "Sleep" 5 "Not Used" 6 "Not Used" 7 "Not Used";
VAL_ 1675 DMS_CameraCancelReason 0 "No display" 1 "Camera temporary OBSTRUCTION" 2 "Camera temporary DIRTY" 3 "Camera temporary FACE MASKED" 4 "Camera temporary EYES MASKED" 5 "LEDs UNAVAILABLE" 6 "Camera OVER HEAT" 7 "DMS Permanent failure";
VAL_ 1675 Distract_AlertStatus 0 "No Alert" 1 "Warning Alert" 2 "Danger Alert" 3 "Warning AlertRER";
VAL_ 1675 DriverEyesOnRoad 0 "Eyes off road" 1 "Eyes on road" 2 "Eyes on driving related area" 3 "Unavailable value";
VAL_ 1675 Drowsy_LevelStatus_v2 0 "No display" 1 "Drowsy level 1" 2 "Drowsy level 2" 3 "Drowsy level 3" 4 "Drowsy level 4" 5 "Drowsy level 5" 6 "Drowsy level 6" 7 "Drowsy level 7" 8 "Drowsy level 8" 9 "Drowsy level 9" 10 "Not used" 11 "Not used" 12 "Not used" 13 "Not used" 14 "Not used" 15 "Not used";
VAL_ 1675 Fatigue_AlertStatus 0 "No Alert" 1 "Warning Alert" 2 "Danger Alert" 3 "Warning AlertRER";
VAL_ 1681 BCI_TemporaryOFFRequest 0 "Not requested" 1 "Deactivation requested";
VAL_ 1681 IVI_ChangeLayoutRequest 0 "No request" 1 "Layout 1" 2 "Layout 2" 3 "Layout 3" 4 "Layout 4" 5 "Layout 5" 6 "Layout 6" 7 "Layout 7" 8 "Layout 8" 9 "Layout 9" 10 "Layout 10" 11 "Layout 11" 12 "Layout 12" 13 "Layout 13" 14 "Layout 14" 15 "Layout 15" 16 "Layout 16" 17 "Layout 17" 18 "Layout 18" 19 "Layout 19" 20 "Layout 20" 21 "Layout 21" 22 "Layout 22" 23 "Layout 23" 24 "Layout 24" 25 "Layout 25" 26 "Layout 26" 27 "Layout 27" 28 "Layout 28" 29 "Layout 29" 30 "Layout 30" 31 "Layout 31";
VAL_ 1681 IVI_LayoutDisplayedStatus 0 "No display" 1 "Layout 1" 2 "Layout 2" 3 "Layout 3" 4 "Layout 4" 5 "Layout 5" 6 "Layout 6" 7 "Layout 7" 8 "Layout 8" 9 "Layout 9" 10 "Layout 10" 11 "Layout 11" 12 "Layout 12" 13 "Layout 13" 14 "Layout 14" 15 "Layout 15" 16 "Layout 16" 17 "Layout 17" 18 "Layout 18" 19 "Layout 19" 20 "Layout 20" 21 "Layout 21" 22 "Layout 22" 23 "Layout 23" 24 "Layout 24" 25 "Layout 25" 26 "Layout 26" 27 "Layout 27" 28 "Layout 28" 29 "Layout 29" 30 "Layout 30" 31 "Layout 31";
VAL_ 1682 ClimHeatedSteeringWheelDisplay 0 "No display" 1 "Heated Steering Wheel ON" 2 "Heated Steering Wheel OFF" 3 "Not used";
VAL_ 1684 APA_WarningDisplayRequest 0 "no message" 1 "message1" 2 "message2" 3 "message3" 4 "message4" 5 "message5" 6 "message6" 7 "message7" 8 "message8" 9 "message9" 10 "message10" 11 "message11" 12 "message12" 13 "message13" 14 "message14" 15 "message15" 16 "message16" 17 "message17" 18 "message18" 19 "message19" 20 "message20" 21 "message21" 22 "message22" 23 "message23" 24 "message24" 25 "message25" 26 "message26" 27 "message27" 28 "message28" 29 "message29" 30 "message30" 31 "message31" 32 "message32" 33 "message33" 34 "message34" 35 "message35" 36 "message36" 37 "message37" 38 "message38" 39 "message39" 40 "message40" 41 "message41" 42 "message42" 43 "message43" 44 "message44" 45 "message45" 46 "message46" 47 "message47" 48 "message48" 49 "message49" 50 "message50" 51 "message51" 52 "message52" 53 "message53" 54 "message54" 55 "message55" 56 "message56" 57 "message57" 58 "message58" 59 "message59" 60 "message60" 61 "message61" 62 "message62" 63 "Not used";
VAL_ 1684 HFP_MapContentDisplay2 0 "Empty Display" 1 "Scanning Display" 2 "ParkOutConfirmation Display" 3 "Guidance Display";
VAL_ 1684 APA_ViewMaskRequest 0 "No request" 1 "Request";
VAL_ 1684 APA_ScanInfo 0 "No display" 1 "Scan" 2 "SlotLeft" 3 "SlotRight" 4 "SlotLeftRight" 5 "Not used" 6 "Not used" 7 "Not used";
VAL_ 1684 HFP_ExtendedMapContentDisplay2 0 "Empty Display" 1 "RPK Display" 2 "Reserved" 3 "Reserved";
VAL_ 1685 CGW_FOTABusyFlag 0 "CGW FOTA Busy" 1 "CGW FOTA Ready";
VAL_ 1685 CGW_FOTAstatus_v2 0 "Idle" 1 "Inventory read in progress" 2 "Inventory read complete" 3 "Menu Package distribution in progress" 4 "Menu Package Integrity check in progress" 5 "Menu Package Integrity check complete" 6 "Gateway Package Distribution in progress" 7 "Gateway Package Integrity check in progress" 8 "Gateway Package Distribution complete" 9 "Parameters check in progress State" 10 "Installation in progress State" 11 "Installation complete State" 12 "Ready for activation State" 13 "Vehicle Condition check in progress" 14 "Switch in progress State" 15 "Reboot in progress" 16 "Component version check in progress" 17 "Configuration install in progress" 18 "Configuration complete" 19 "Activation complete" 20 "Finishing in progress" 21 "FOTA CLIENT related Error detected" 22 "FOTA CLIENT related cancel complete" 23 "Cancel in progress" 24 "Cancel failed" 25 "Cancel complete" 26 "Rollback in progress" 27 "Rollback complete" 28 "Not used" 29 "Not used" 30 "Not used" 31 "Invalid";
VAL_ 1695 VehicleID 0 "Table Value16392";
VAL_ 1697 ADASISv2_METADATA 0 "Table Value30476";
VAL_ 1698 BSWson_ChoiceRequest2 0 "No request" 1 "Selected" 2 "Not selected" 3 "Reset request";
VAL_ 1698 BSWrad_ChoiceRequest2 0 "No request" 1 "Selected" 2 "Not selected" 3 "Reset request";
VAL_ 1698 MOIS_ActivationRequest2 0 "No request" 1 "Activation request" 2 "Deactivation request" 3 "Reset request";
VAL_ 1698 SpeedLimNotifActivationRequest2 0 "No request" 1 "SpeedLimit Notif Activation request" 2 "SpeedLimit Notif deactivation request" 3 "Reset request";
VAL_ 1698 WDA_ChoiceRequest2 0 "No request" 1 "Selected" 2 "Not selected" 3 "Reset request";
VAL_ 1698 OverspeedAlertChoiceRequest2 0 "No request" 1 "Selected" 2 "Not Selected" 3 "Reset request";
VAL_ 1698 LDWLKA_ChoiceRequest2 0 "No request" 1 "Selected" 2 "Not selected" 3 "Reset request";
VAL_ 1698 ELKA_ChoiceRequest2 0 "No request" 1 "Selected" 2 "Not selected" 3 "Reset request";
VAL_ 1698 MOIS_MuteActivationRequest2 0 "No request" 1 "Mute request" 2 "Unmute request" 3 "Reset request";
VAL_ 1698 Fatigue_ChoiceRequest2 0 "No request" 1 "Selected" 2 "Not selected" 3 "Reset request";
VAL_ 1698 Distraction_ChoiceRequest2 0 "No request" 1 "Selected" 2 "Not selected" 3 "Reset request";
VAL_ 1698 ESA_ActivationRequest2 0 "No request" 1 "Activated" 2 "Deactivated" 3 "Reset request";
VAL_ 1703 ProgrammedChargeStatus 0 "Always authorized charge" 1 "Delayed charge" 2 "Programmed charge by Calendar" 3 "Not Used";
VAL_ 1705 SpeedLimNotifActivationStatus 0 "Not available" 1 "SpeedLimitNotificationActivated" 2 "SpeedLimitNotificationDeactivated" 3 "Not used";
VAL_ 1711 RouteGuiding_flag_GAS 0 "OFF" 1 "ON";
VAL_ 1711 RouteConf_METER_Request 0 "No Request" 1 "Confirm Request" 2 "Fail Request" 3 "Not used";
VAL_ 1711 ReRouteGuiding_flag_GAS 0 "No Request" 1 "Destination Reset Request";
VAL_ 1711 AD_RouteGuide_Status 0 "No Request" 1 "Google Navi" 2 "AD Navi" 3 "Error";
VAL_ 1711 RouteConf_ADAS_Ack 0 "No Request" 1 "Start Guide" 2 "Cancel" 3 "Not used";
VAL_ 1711 HVbatQCPreheatingOffRequest 0 "No request" 1 "Battery Preheating OFF request" 2 "Battery Preheating ON request" 3 "Reset request";
VAL_ 1711 N_AmbientLightPatternRequest 0 "No Request" 1 "Pattern 0 Request" 2 "Pattern 1 Request" 3 "Pattern 2 Request" 4 "Pattern 3 Request" 5 "Not used" 6 "Not used" 7 "Not used";
VAL_ 1711 TableModeRequest 0 "No request" 1 "Table Mode OFF" 2 "Table Mode ON" 3 "Not used";
VAL_ 1724 ChargeTimeIndexReachibility 0 "No Index Data" 1 "Index Data 1" 2 "Index Data 2" 3 "Index Data 3" 4 "Index Data 4" 5 "Index Data 5" 6 "Index Data 6" 7 "Index Data 7" 8 "Index Data 8" 9 "Not used" 10 "Not used" 11 "Not used" 12 "Not used" 13 "Not used" 14 "Not used" 15 "Not used";
VAL_ 1742 ADmodeStatus_Slow 0 "AD/RPK OFF" 1 "AD2 L2 regulation" 2 "AD1 L3 regulation" 3 "RPK regulation" 4 "AD/RPK OFF + TD or MRM in regulation" 5 "AD2 L2 regulation + TD or MRM in regulation" 6 "AD1 L3 regulation + TD or MRM in regulation" 7 "RPK regulation + TD or MRM in regulation";
VAL_ 1753 CPLC_FaultType 0 "No Fault" 1 "Contract NOK" 2 "Energy Transfer mode type not supported" 3 "PLC comm failure HLCcommstatus" 4 "EVSE comm Failure" 5 "EVSE Not Ready" 6 "EVSE Shutdown" 7 "EVSE Utility Interrupt Event" 8 "EVSE Isolation Monitoring Active" 9 "EVSE Emergency Shutdown" 10 "EVSE Malfunction Protocol with EVSE (Station charging)" 11 "EVSE_Renegociate" 12 "EVSE Pause" 13 "Certificate Error" 14 "Not used" 15 "Not used";
VAL_ 1754 Combo_DCExtendedConnectStatus 0 "Unavailable" 1 "DC extended not detected" 2 "DC extended detected" 3 "Not used";
VAL_ 1755 HVbatteryCoolingInProgressStatus 0 "No display" 1 "Battery cooling in progress";
VAL_ 1755 HVbatteryCoolingActivationState 0 "Battery cooling activated" 1 "Battery cooling desactivated";
VAL_ 1755 ClimHVpowerLimitationDisp_HEVC 0 "No display" 1 "Thermal Comfort available" 2 "SOC decreasing warning" 3 "No Thermal Comfort available" 4 "Downgraded charging time alert" 5 "Not used" 6 "Not used" 7 "Not used";
VAL_ 1755 HVbatteryWarmingState 0 "Battery warming OFF" 1 "Battery warming ON";
VAL_ 1756 Cluster_DispViewModeChangeResult 0 "No Message" 1 "Change accepted" 2 "Change Not accepted Temporary Reason" 3 "Change Not accepted Permanent Reason";
VAL_ 1756 Cluster_DisplayViewModeStatus 0 "INVALID" 1 "View Mode1" 2 "View Mode2" 3 "View Mode3" 4 "View Mode4" 5 "View Mode5" 6 "View Mode6" 7 "View Mode7";
VAL_ 1756 Cluster_DispContentsChangeResult 0 "No Message" 1 "Change accepted" 2 "Change Not accepted Temporary Reason" 3 "Change Not accepted Permanent Reason";
VAL_ 1756 Cluster_DisplayContentsStatus 0 "INVALID" 1 "Contents 1" 2 "Contents 2" 3 "Contents 3" 4 "Contents 4" 5 "Contents 5" 6 "Contents 6" 7 "Contents 7" 8 "Contents 8" 9 "Contents 9" 10 "Contents 10" 11 "Contents 11" 12 "Contents 12" 13 "Contents 13" 14 "Contents 14" 15 "Contents 15" 16 "Contents 16" 17 "Contents 17" 18 "Contents 18" 19 "Contents 19" 20 "Contents 20" 21 "Contents 21" 22 "Contents 22" 23 "Contents 23" 24 "Contents 24" 25 "Contents 25" 26 "Contents 26" 27 "Contents 27" 28 "Contents 28" 29 "Contents 29" 30 "Contents 30" 31 "Contents 31" 32 "Contents 32" 33 "Contents 33" 34 "Contents 34" 35 "Contents 35" 36 "Contents 36" 37 "Contents 37" 38 "Contents 38" 39 "Contents 39" 40 "Contents 40" 41 "Contents 41" 42 "Contents 42" 43 "Contents 43" 44 "Contents 44" 45 "Contents 45" 46 "Contents 46" 47 "Contents 47" 48 "Contents 48" 49 "Contents 49" 50 "Contents 50" 51 "Contents 51" 52 "Contents 52" 53 "Contents 53" 54 "Contents 54" 55 "Contents 55" 56 "Contents 56" 57 "Contents 57" 58 "Contents 58" 59 "Contents 59" 60 "Contents 60" 61 "Contents 61" 62 "Contents 62" 63 "Contents 63";
VAL_ 1768 VideoType 0 "Default" 1 "Camera" 2 "Movie" 3 "Not Used";
VAL_ 1768 FaceID_RecognitionRequest 0 "No Request" 1 "Request" 2 "Stop (Cancel)" 3 "Not used";
VAL_ 1768 FaceID_DeleteRequest 0 "No request" 1 "User No. 1" 2 "User No. 2" 3 "User No. 3" 4 "User No. 4" 5 "User No. 5" 6 "Not used" 7 "Not used";
VAL_ 1768 FaceID_ActivationState 0 "Activate" 1 "Deactivate";
VAL_ 1768 DayNightUserRequest 0 "Day" 1 "Night";
VAL_ 1768 DVR_CameraView_Change 0 "No Change view from current status" 1 "Change view to FR" 2 "Change view to RR" 3 "Change view to INCAM";
VAL_ 1768 DVR_Adjustment_Rotation 0 "0 deg" 1 "CCW plus 0_5deg" 2 "CW plus 0_5deg" 3 "Not used";
VAL_ 1768 FaceID_ResistrationRequest 0 "No request" 1 "User No. 1" 2 "User No. 2" 3 "User No. 3" 4 "User No. 4" 5 "User No. 5" 6 "Stop (Cancel)" 7 "Not used";
VAL_ 1768 ContrastRequestINcam 0 "No request" 1 "Level1" 2 "Level2" 3 "Level3" 4 "Level4" 5 "Level5" 6 "Reset request" 7 "Not Used";
VAL_ 1768 ContrastRequestFRcam 0 "No request" 1 "Level1" 2 "Level2" 3 "Level3" 4 "Level4" 5 "Level5" 6 "Reset request" 7 "Not Used";
VAL_ 1768 VDCActivationRequest2 0 "No Request" 1 "VDC function activation" 2 "VDC function deactivation" 3 "Reset Request";
VAL_ 1768 MMI_CommandList_2 0 "Taking inner camera photo" 1 "Taking inner camera video" 2 "Fast forward 10 sec" 3 "Fast forward 20 sec" 4 "Fast rewind 10 sec" 5 "Fast rewind 20 sec" 6 "Play back progress 0%" 7 "Play back progress 10%" 8 "Play back progress 20%" 9 "Play back progress 30%" 10 "Play back progress 40%" 11 "Play back progress 50%" 12 "Play back progress 60%" 13 "Play back progress 70%" 14 "Play back progress 80%" 15 "Play back progress 90%" 16 "Play back progress 100%" 17 "Not Used" 18 "Not Used" 19 "Not Used" 20 "Not Used" 21 "Not Used" 22 "Not Used" 23 "Not Used" 24 "Not Used" 25 "Not Used" 26 "Not Used" 27 "Not Used" 28 "Not Used" 29 "Not Used" 30 "Not Used" 31 "Not Used";
VAL_ 1768 ContrastRequestRRcam 0 "No request" 1 "Level1" 2 "Level2" 3 "Level3" 4 "Level4" 5 "Level5" 6 "Reset request" 7 "Not Used";
VAL_ 1768 BrightnessRequest 0 "No request" 1 "Level1" 2 "Level2" 3 "Level3" 4 "Level4" 5 "Level5" 6 "Reset request" 7 "Not Used";
VAL_ 1768 SelftimerRequest 0 "No request" 1 "Timer1" 2 "Timer2" 3 "Timer3" 4 "Reset request" 5 "Not Used" 6 "Not Used" 7 "Not Used";
VAL_ 1768 SetRecordQuality_HSL 0 "High" 1 "Standard" 2 "Long time" 3 "invalid value";
VAL_ 1768 BrightnessRequestRRcam 0 "No request" 1 "Level1" 2 "Level2" 3 "Level3" 4 "Level4" 5 "Level5" 6 "Reset request" 7 "Not Used";
VAL_ 1768 BrightnessRequestINcam 0 "No request" 1 "Level1" 2 "Level2" 3 "Level3" 4 "Level4" 5 "Level5" 6 "Reset request" 7 "Not Used";
VAL_ 1768 AudioOnStatus 0 "Audio Off" 1 "Audio On";
VAL_ 1768 WiFiSetting_v2 0 "turn on" 1 "turn off" 2 "Not used" 3 "Unavailable";
VAL_ 1768 IlluminationControlReq 0 "No request" 1 "Step1" 2 "Step2" 3 "Step3" 4 "Step4" 5 "Step5" 6 "Step6" 7 "Step7" 8 "Step8" 9 "Step9" 10 "Step10" 11 "Step11" 12 "Step12" 13 "Step13" 14 "Step14" 15 "Step15" 16 "Step16" 17 "Step17" 18 "Step18" 19 "Step19" 20 "Step20" 21 "Step21" 22 "Step22" 23 "Not used" 24 "Not used" 25 "Not used" 26 "Not used" 27 "Not used" 28 "Not used" 29 "Not used" 30 "Not used" 31 "Not used";
VAL_ 1768 GetSSIDandPassword 0 "Unavailable value" 1 "Get SSID+Password";
VAL_ 1768 GeneralRecordingSetting_v2 0 "turn on" 1 "turn off" 2 "Not used" 3 "Unavailable";
VAL_ 1768 IlluminationContReqForCamera 0 "No request" 1 "Step1" 2 "Step2" 3 "Step3" 4 "Step4" 5 "Step5" 6 "Step6" 7 "Step7" 8 "Step8" 9 "Step9" 10 "Step10" 11 "Step11" 12 "Step12" 13 "Step13" 14 "Step14" 15 "Step15" 16 "Step16" 17 "Step17" 18 "Step18" 19 "Step19" 20 "Step20" 21 "Step21" 22 "Step22" 23 "Not used" 24 "Not used" 25 "Not used" 26 "Not used" 27 "Not used" 28 "Not used" 29 "Not used" 30 "Not used" 31 "Not used";
VAL_ 1769 Navi_TollGateInformation 0 "Invalid (Charge process:N/A)" 65 "Access:Permitted (Charge process:Processed)" 66 "Stop (Charge process:Processed)" 67 "ETC line access:Denied (Charge process:Processed)" 68 "ETC line access:Permitted (Charge process:Processed)" 69 "To passing (rightmost) lane (ETC line:Denied) (Charge process:Processed)" 70 "To passing (rightmost) lane (ETC line:Permitted) (Charge process:Processed)" 71 "To cruising (leftmost) lane (ETC line:Denied) (Charge process:Processed)" 72 "To cruising (leftmost) lane (ETC line:Permitted) (Charge process:Processed)" 73 "To middle (midmost) lane (ETC line:Denied) (Charge process:Processed)" 74 "To middle(midmost) lane (ETC line:Permitted) (Charge process:Processed)" 75 "Slow down (ETC line:Denied) (Charge process:Processed)" 76 "Slow down (ETC line:Permitted) (Charge process:Processed)" 97 "Access:Permitted (Charge process:Not processed)" 98 "Stop (Charge process:Not processed)" 99 "ETC line access:Denied (Charge process:Not processed)" 100 "ETC line access:Permitted (Charge process:Not processed)" 101 "To passing (rightmost) lane (ETC line:Denied) (Charge process:Not processed)" 102 "To passing (rightmost) lane (ETC line:Permitted) (Charge process:Not processed)" 103 "To cruising (leftmost) lane (ETC line:Denied) (Charge process:Not processed)" 104 "To cruising (leftmost) lane (ETC line:Permitted) (Charge process:Not processed)" 105 "To middle (midmost) lane (ETC line:Denied) (Charge process:Not processed)" 106 "To middle(midmost) lane (ETC line:Permitted) (Charge process:Not processed)" 107 "Slow down (ETC line:Denied) (Charge process:Not processed)" 108 "Slow down (ETC line:Permitted) (Charge process:Not processed)";
VAL_ 1776 RouteConf_IVI_Ack 0 "No Request" 1 "Start Guide" 2 "Cancel" 3 "Not used";
VAL_ 1779 ChargeCal1TuesdayChange_MMI 0 "Unselected day" 1 "Selected day";
VAL_ 1779 ChargeCal1MondayChange_MMI 0 "Unselected day" 1 "Selected day";
VAL_ 1779 ChargeCal1SundayChange_MMI 0 "Unselected day" 1 "Selected day";
VAL_ 1779 ChargeCal1SaturdayChange_MMI 0 "Unselected day" 1 "Selected day";
VAL_ 1779 ChargeCal1FridayChange_MMI 0 "Unselected day" 1 "Selected day";
VAL_ 1779 ChargeCal1ThursdayChange_MMI 0 "Unselected day" 1 "Selected day";
VAL_ 1779 ChargeCal1WednesdayChange_MMI 0 "Unselected day" 1 "Selected day";
VAL_ 1779 ChargeCal2TuesdayChange_MMI 0 "Unselected day" 1 "Selected day";
VAL_ 1779 ChargeCal2MondayChange_MMI 0 "Unselected day" 1 "Selected day";
VAL_ 1779 ChargeCalAllChange_MMI 0 "No Request" 1 "Change all charge calendars request" 2 "Reset all charge calendars request" 3 "Not used";
VAL_ 1779 ChargeCal2SundayChange_MMI 0 "Unselected day" 1 "Selected day";
VAL_ 1779 ChargeCal2SaturdayChange_MMI 0 "Unselected day" 1 "Selected day";
VAL_ 1779 ChargeCal2FridayChange_MMI 0 "Unselected day" 1 "Selected day";
VAL_ 1779 ChargeCal2ThursdayChange_MMI 0 "Unselected day" 1 "Selected day";
VAL_ 1779 ChargeCal2WednesdayChange_MMI 0 "Unselected day" 1 "Selected day";
VAL_ 1780 ChargeCal3TuesdayChange_MMI 0 "Unselected day" 1 "Selected day";
VAL_ 1780 ChargeCal3MondayChange_MMI 0 "Unselected day" 1 "Selected day";
VAL_ 1780 ChargeCal3SundayChange_MMI 0 "Unselected day" 1 "Selected day";
VAL_ 1780 ChargeCal3SaturdayChange_MMI 0 "Unselected day" 1 "Selected day";
VAL_ 1780 ChargeCal3FridayChange_MMI 0 "Unselected day" 1 "Selected day";
VAL_ 1780 ChargeCal3ThursdayChange_MMI 0 "Unselected day" 1 "Selected day";
VAL_ 1780 ChargeCal3WednesdayChange_MMI 0 "Unselected day" 1 "Selected day";
VAL_ 1780 ChargeCal4TuesdayChange_MMI 0 "Unselected day" 1 "Selected day";
VAL_ 1780 ChargeCal4MondayChange_MMI 0 "Unselected day" 1 "Selected day";
VAL_ 1780 ChargeCal4SundayChange_MMI 0 "Unselected day" 1 "Selected day";
VAL_ 1780 ChargeCal4SaturdayChange_MMI 0 "Unselected day" 1 "Selected day";
VAL_ 1780 ChargeCal4FridayChange_MMI 0 "Unselected day" 1 "Selected day";
VAL_ 1780 ChargeCal4ThursdayChange_MMI 0 "Unselected day" 1 "Selected day";
VAL_ 1780 ChargeCal4WednesdayChange_MMI 0 "Unselected day" 1 "Selected day";
VAL_ 1781 ChargeCal5TuesdayChange_MMI 0 "Unselected day" 1 "Selected day";
VAL_ 1781 ChargeCal5MondayChange_MMI 0 "Unselected day" 1 "Selected day";
VAL_ 1781 ChargeCal5SundayChange_MMI 0 "Unselected day" 1 "Selected day";
VAL_ 1781 ChargeCal5SaturdayChange_MMI 0 "Unselected day" 1 "Selected day";
VAL_ 1781 ChargeCal5FridayChange_MMI 0 "Unselected day" 1 "Selected day";
VAL_ 1781 ChargeCal5ThursdayChange_MMI 0 "Unselected day" 1 "Selected day";
VAL_ 1781 ChargeCal5WednesdayChange_MMI 0 "Unselected day" 1 "Selected day";
VAL_ 1781 EcoTripResetRequest 0 "No Reset request" 1 "Reset request";
VAL_ 1781 ChargeDelayedRequest 0 "No request" 1 "Delayed charge request";
VAL_ 1781 ChargeAlwaysRequest 0 "No request" 1 "Always charge request";
VAL_ 1781 FuelSaveClearHistoRequest 0 "No Reset request" 1 "Reset request";
VAL_ 1782 PreSoakCal1FridayChange_MMI 0 "Unselected day" 1 "Selected day";
VAL_ 1782 PreSoakCal1ThursdayChange_MMI 0 "Unselected day" 1 "Selected day";
VAL_ 1782 PreSoakCal1WednesdayChange_MMI 0 "Unselected day" 1 "Selected day";
VAL_ 1782 PreSoakCal1TuesdayChange_MMI 0 "Unselected day" 1 "Selected day";
VAL_ 1782 PreSoakCal1MondayChange_MMI 0 "Unselected day" 1 "Selected day";
VAL_ 1782 PreSoakCal1SundayChange_MMI 0 "Unselected day" 1 "Selected day";
VAL_ 1782 PreSoakCal1SaturdayChange_MMI 0 "Unselected day" 1 "Selected day";
VAL_ 1782 PreSoakCal2WednesdayChange_MMI 0 "Unselected day" 1 "Selected day";
VAL_ 1782 PreSoakCal2TuesdayChange_MMI 0 "Unselected day" 1 "Selected day";
VAL_ 1782 PreSoakCal2MondayChange_MMI 0 "Unselected day" 1 "Selected day";
VAL_ 1782 PreSoakCal2SundayChange_MMI 0 "Unselected day" 1 "Selected day";
VAL_ 1782 PreSoakCal2SaturdayChange_MMI 0 "Unselected day" 1 "Selected day";
VAL_ 1782 PreSoakCal2FridayChange_MMI 0 "Unselected day" 1 "Selected day";
VAL_ 1782 PreSoakCal2ThursdayChange_MMI 0 "Unselected day" 1 "Selected day";
VAL_ 1782 PreSoakCal3MondayChange_MMI 0 "Unselected day" 1 "Selected day";
VAL_ 1782 PreSoakCalAllChange_MMI 0 "No Request" 1 "Change all presoak calendars request" 2 "Reset all presoak calendars request" 3 "Not used";
VAL_ 1782 PreSoakCal3SundayChange_MMI 0 "Unselected day" 1 "Selected day";
VAL_ 1782 PreSoakCal3SaturdayChange_MMI 0 "Unselected day" 1 "Selected day";
VAL_ 1782 PreSoakCal3FridayChange_MMI 0 "Unselected day" 1 "Selected day";
VAL_ 1782 PreSoakCal3ThursdayChange_MMI 0 "Unselected day" 1 "Selected day";
VAL_ 1782 PreSoakCal3WednesdayChange_MMI 0 "Unselected day" 1 "Selected day";
VAL_ 1782 PreSoakCal3TuesdayChange_MMI 0 "Unselected day" 1 "Selected day";
VAL_ 1783 PreSoakCal4FridayChange_MMI 0 "Unselected day" 1 "Selected day";
VAL_ 1783 PreSoakCal4ThursdayChange_MMI 0 "Unselected day" 1 "Selected day";
VAL_ 1783 PreSoakCal4WednesdayChange_MMI 0 "Unselected day" 1 "Selected day";
VAL_ 1783 PreSoakCal4TuesdayChange_MMI 0 "Unselected day" 1 "Selected day";
VAL_ 1783 PreSoakCal4MondayChange_MMI 0 "Unselected day" 1 "Selected day";
VAL_ 1783 PreSoakCal4SundayChange_MMI 0 "Unselected day" 1 "Selected day";
VAL_ 1783 PreSoakCal4SaturdayChange_MMI 0 "Unselected day" 1 "Selected day";
VAL_ 1783 PreSoakCal5WednesdayChange_MMI 0 "Unselected day" 1 "Selected day";
VAL_ 1783 PreSoakCal5TuesdayChange_MMI 0 "Unselected day" 1 "Selected day";
VAL_ 1783 PreSoakCal5MondayChange_MMI 0 "Unselected day" 1 "Selected day";
VAL_ 1783 PreSoakCal5SundayChange_MMI 0 "Unselected day" 1 "Selected day";
VAL_ 1783 PreSoakCal5SaturdayChange_MMI 0 "Unselected day" 1 "Selected day";
VAL_ 1783 PreSoakCal5FridayChange_MMI 0 "Unselected day" 1 "Selected day";
VAL_ 1783 PreSoakCal5ThursdayChange_MMI 0 "Unselected day" 1 "Selected day";
VAL_ 1789 VolumAlarmActivationState 0 "Unavailable" 1 "Intrusion Sensor Deactivated Ask On Exit" 2 "Intrusion Sensor Deactivated Once" 3 "Intrusion Sensor Activated" 4 "Intrusion Sensor Deactivated" 5 "Not used" 6 "Not used" 7 "Not used";
VAL_ 1789 FOTA_TimerExpiredStatus 0 "No timer expired" 1 "Timer expired";
VAL_ 1789 FOTA_ProgStatus 0 "No Timer" 1 "Timer Set";
VAL_ 1789 FunctionalLightingActivStatus 0 "Unavailable" 1 "Functional Light activated" 2 "Functional Light deactivated" 3 "Functional Light Auto";
VAL_ 1789 AmbientADLinkStatus 0 "AD LINK deactivated" 1 "AD LINK activated";
VAL_ 1790 V2Li_OverheatFailureDisplay 0 "No display" 1 "V2L Inside sockets overheat";
VAL_ 1790 ScreenDriverSaveModeState 0 "Unavailable" 1 "E Save not activated" 2 "E Save activated" 3 "Not used";
VAL_ 1790 PnCchargeStationCompatibility 0 "No Display" 1 "not compatible";
VAL_ 2563507968 SIGMA_CDM 0 "Table Value16461";
VAL_ 2563507968 SIGMA_DTCCDM 0 "Table Value26862";
VAL_ 2563508007 SIGMA_eHBox 0 "Table Value430561";
VAL_ 2563508007 SIGMA_DTCeHBox 0 "Table Value430559";
VAL_ 2563508009 SIGMA_PSD_R 0 "Table Value153060";
VAL_ 2563508009 SIGMA_DTCPSD_R 0 "Table Value153056";
VAL_ 2563508019 SIGMA_PBD 0 "Table Value16399";
VAL_ 2563508019 SIGMA_DTCPBD 0 "Table Value26865";
VAL_ 2563508021 SIGMA_RADAR 0 "Table Value16466";
VAL_ 2563508021 SIGMA_DTCRADAR 0 "Table Value26884";
VAL_ 2563508022 SIGMA_PSCU 0 "Table Value16465";
VAL_ 2563508022 SIGMA_DTCPSCU 0 "Table Value26866";
VAL_ 2563508030 SIGMA_SRad_RL 0 "Table Value16470";
VAL_ 2563508030 SIGMA_DTCSRad_RL 0 "Table Value26868";
VAL_ 2563508035 SIGMA_eRDC_L 0 "Table Value252236";
VAL_ 2563508035 SIGMA_DTCeRDC_L 0 "Table Value252232";
VAL_ 2563508037 SIGMA_eRDC_R 0 "Table Value252238";
VAL_ 2563508037 SIGMA_DTCeRDC_R 0 "Table Value252233";
VAL_ 2563508042 SIGMA_ANC 0 "Table Value16458";
VAL_ 2563508042 SIGMA_DTCANC 0 "Table Value26859";
VAL_ 2563508064 SIGMA_VDC 0 "Table Value16380";
VAL_ 2563508064 SIGMA_DTCVDC 0 "Table Value26886";
VAL_ 2563508066 SIGMA_EPS 0 "Table Value16377";
VAL_ 2563508066 SIGMA_DTCEPS 0 "Table Value26879";
VAL_ 2563508067 SIGMA_METER 0 "Table Value16379";
VAL_ 2563508067 SIGMA_DTCMETER 0 "Table Value26883";
VAL_ 2563508068 SIGMA_HVAC 0 "Table Value28686";
VAL_ 2563508068 SIGMA_DTCHVAC 0 "Table Value28682";
VAL_ 2563508069 SIGMA_BCM 0 "Table Value16381";
VAL_ 2563508069 SIGMA_DTCBCM 0 "Table Value26877";
VAL_ 2563508071 SIGMA_IVI 0 "Table Value16383";
VAL_ 2563508071 SIGMA_DTCIVI 0 "Table Value26882";
VAL_ 2563508072 SIGMA_4WD 0 "Table Value28679";
VAL_ 2563508072 SIGMA_DTC4WD 0 "Table Value28678";
VAL_ 2563508077 SIGMA_USM 0 "Table Value16384";
VAL_ 2563508077 SIGMA_DTCUSM 0 "Table Value26885";
VAL_ 2563508078 SIGMA_SONAR 0 "Table Value28703";
VAL_ 2563508078 SIGMA_DTCSONAR 0 "Table Value28702";
VAL_ 2563508079 SIGMA_DSMU 0 "Table Value16462";
VAL_ 2563508079 SIGMA_DTCDSMU 0 "Table Value26863";
VAL_ 2563508082 SIGMA_ACU 0 "Table Value16374";
VAL_ 2563508082 SIGMA_DTCACU 0 "Table Value26874";
VAL_ 2563508089 SIGMA_PSD_L 0 "Table Value153059";
VAL_ 2563508089 SIGMA_DTCPSD_L 0 "Table Value153054";
VAL_ 2563508093 SIGMA_ADAS 0 "Table Value16457";
VAL_ 2563508093 SIGMA_DTCADAS 0 "Table Value26875";
VAL_ 2563508099 SIGMA_A_IVC 0 "Table Value16456";
VAL_ 2563508099 SIGMA_DTCA_IVC 0 "Table Value26858";
VAL_ 2563508108 SIGMA_INV_ME 0 "Table Value27356";
VAL_ 2563508108 SIGMA_DTCINV_ME 0 "Table Value27351";
VAL_ 2563508115 SIGMA_OBC_AC 0 "Table Value28687";
VAL_ 2563508115 SIGMA_DTCOBC_AC 0 "Table Value28683";
VAL_ 2563508122 SIGMA_HEVC 0 "Table Value27338";
VAL_ 2563508122 SIGMA_DTCHEVC 0 "Table Value27347";
VAL_ 2563508130 SIGMA_AUDIOamp 0 "Table Value16459";
VAL_ 2563508130 SIGMA_DTCAUDIOamp 0 "Table Value26860";
VAL_ 2563508133 SIGMA_HNS 0 "Table Value27353";
VAL_ 2563508133 SIGMA_DTCHNS 0 "Table Value27348";
VAL_ 2563508139 SIGMA_VKM 0 "Table Value252239";
VAL_ 2563508139 SIGMA_DTCVKM 0 "Table Value252234";
VAL_ 2563508153 SIGMA_HFM 0 "Table Value16382";
VAL_ 2563508153 SIGMA_DTCHFM 0 "Table Value26881";
VAL_ 2563508154 SIGMA_AVM 0 "Table Value27338";
VAL_ 2563508154 SIGMA_DTCAVM 0 "Table Value27343";
VAL_ 2563508157 SIGMA_SCU 0 "Table Value28688";
VAL_ 2563508157 SIGMA_DTCSCU 0 "Table Value28684";
VAL_ 2563508164 SIGMA_eShifter 0 "Table Value153058";
VAL_ 2563508164 SIGMA_DTCeShifter 0 "Table Value153055";
VAL_ 2563508181 SIGMA_SRad_RR 0 "Table Value16471";
VAL_ 2563508181 SIGMA_DTCSRad_RR 0 "Table Value26871";
VAL_ 2563508189 SIGMA_FrCamera 0 "Table Value16378";
VAL_ 2563508189 SIGMA_DTCFrCamera 0 "Table Value26880";
VAL_ 2563508200 SIGMA_ECM 0 "Table Value16376";
VAL_ 2563508200 SIGMA_DTCECM 0 "Table Value26878";
VAL_ 2563508201 SIGMA_ATCU 0 "Table Value16375";
VAL_ 2563508201 SIGMA_DTCATCU 0 "Table Value26876";
VAL_ 2563508205 SIGMA_BMS_HV 0 "Table Value27340";
VAL_ 2563508205 SIGMA_DTCBMS_HV 0 "Table Value27344";
VAL_ 2563508207 SIGMA_INV_HSG 0 "Table Value27355";
VAL_ 2563508207 SIGMA_DTCINV_HSG 0 "Table Value27350";
VAL_ 2563567883 SIGMA_BMS_12V 0 "Table Value16460";
VAL_ 2563567883 SIGMA_DTCBMS_12V 0 "Table Value26861";
VAL_ 2563567951 SIGMA_EPS_sub 0 "Table Value28685";
VAL_ 2563567951 SIGMA_DTCEPS_sub 0 "Table Value28681";
VAL_ 2563567958 SIGMA_eShiftAct 0 "Table Value153057";
VAL_ 2563567958 SIGMA_DTCeShiftAct 0 "Table Value153053";
VAL_ 2563567968 SIGMA_HUD 0 "Table Value27354";
VAL_ 2563567968 SIGMA_DTCHUD 0 "Table Value27349";
VAL_ 2563568024 SIGMA_HPCU 0 "Table Value55692";
VAL_ 2563568024 SIGMA_DTCHPCU 0 "Table Value55693";
VAL_ 2563568093 SIGMA_DCDC_HV 0 "Table Value28677";
VAL_ 2563568093 SIGMA_DTCDCDC_HV 0 "Table Value28680";
VAL_ 2563568098 SIGMA_EBA 0 "Table Value16463";
VAL_ 2563568098 SIGMA_DTCEBA 0 "Table Value26864";
VAL_ 2563568101 SIGMA_INV_RE 0 "Table Value27357";
VAL_ 2563568101 SIGMA_DTCINV_RE 0 "Table Value27352";
VAL_ 2563568130 SIGMA_AirSUSP 0 "Table Value359670";
VAL_ 2563568130 SIGMA_DTCAirSUSP 0 "Table Value359671";
VAL_ 2563568148 SIGMA_BSG 0 "Table Value27341";
VAL_ 2563568148 SIGMA_DTCBSG 0 "Table Value27345";
VAL_ 2563568163 SIGMA_SRad_FL 0 "Table Value16468";
VAL_ 2563568163 SIGMA_DTCSRad_FL 0 "Table Value26869";
VAL_ 2563568164 SIGMA_SRad_FR 0 "Table Value16469";
VAL_ 2563568164 SIGMA_DTCSRad_FR 0 "Table Value26870";
VAL_ 2563568201 SIGMA_STBW 0 "Table Value161590";
VAL_ 2563568201 SIGMA_DTCSTBW 0 "Table Value161588";
VAL_ 2563568233 SIGMA_DMC 0 "Table Value27342";
VAL_ 2563568233 SIGMA_DTCDMC 0 "Table Value27346";
VAL_ 2563568267 SIGMA_RSCU3R 0 "Table Value407697";
VAL_ 2563568267 SIGMA_DTCRSCU3R 0 "Table Value407696";
VAL_ 2563568288 SIGMA_BLM_RPK 0 "Table Value55679";
VAL_ 2563568288 SIGMA_DTCBLM_RPK 0 "Table Value55690";
VAL_ 2563568290 SIGMA_SCCM 0 "Table Value16467";
VAL_ 2563568290 SIGMA_DTCSCCM 0 "Table Value26867";
VAL_ 2563568300 SIGMA_RSCU2R 0 "Table Value359675";
VAL_ 2563568300 SIGMA_DTCRSCU2R 0 "Table Value359672";
VAL_ 2609102848 CGW_WakeUp_Signal 0 "Table Value16477";
VAL_ 2615050482 FTOOLS_IVCtoSWMC 0 "Table Value16359";
VAL_ 2615070962 FTOOLS_SWMCtoCGW 0 "Table Value16360";
VAL_ 2615079552 FTOOLS_SWMCtoIVC 0 "Table Value16361";
VAL_ 2615079632 FTOOLS_CGWtoSWMC 0 "Table Value16357";
